VERSION ""

NS_ :

BS_:

BU_: WPC2 RLPSU DPSU PSB SHVU_RR APSU FCS EMCU SLB ARS RCM CGW_CCU ATS RLHV SGU PFSU ALBCU DSAU SWRC SHVU_FR RCS RRPSU BLTN_CAM SCM DLBCU OHCL RWPC RRHV WPC HOD ASAU

BO_ 2256644609 CLU_01_20ms_1: 8 CGW_CCU
 SG_ CLU_DtntOutSta : 28|2@1+ (1,0) [0|0] ""  FCS,WPC,RWPC,SWRC,APSU,RLHV,RRHV,SHVU_FR,SHVU_RR,DPSU,RCS,RRPSU,RLPSU,ATS,DSAU,ASAU,OHCL,WPC2
 SG_ CLU_RhstaLvlSta : 43|5@1+ (1,0) [0|0] ""  FCS,WPC,RWPC,SWRC,APSU,RLHV,RRHV,SHVU_FR,SHVU_RR,DPSU,RCS,RRPSU,RLPSU,ATS,DSAU,ASAU,OHCL,WPC2

BO_ 2470763009 CLU_09_00ms_1: 8 CGW_CCU
 SG_ USM_WpcSetReq : 34|2@1+ (1,0) [0|0] ""  WPC,WPC2

BO_ 2256644610 CLU_01_20ms_2: 8 CGW_CCU
 SG_ CLU_DisSpdVal_KPH : 0|9@1+ (1,0) [0|0] "km/h"  WPC,RWPC,APSU,RLHV,RRHV,SHVU_FR,SHVU_RR,DPSU,DLBCU,PFSU,RRPSU,RLPSU,ATS,DSAU,ASAU,RCM,ALBCU,WPC2
 SG_ CLU_AutoBrightSta : 15|8@1+ (1,0) [0|0] ""  FCS,WPC,RWPC,SWRC,APSU,RLHV,RRHV,SHVU_FR,SHVU_RR,DPSU,RCS,ATS,DSAU,ASAU,OHCL,BLTN_CAM,WPC2

BO_ 2214658049 EMS_02_10ms_1: 8 CGW_CCU
 SG_ ENG_EngSta : 61|3@1+ (1,0) [0|0] ""  SCM,WPC,RWPC,SWRC,APSU,RLHV,RRHV,SHVU_FR,SHVU_RR,DPSU,DLBCU,PFSU,RRPSU,RLPSU,HOD,RCM,BLTN_CAM,EMCU,WPC2

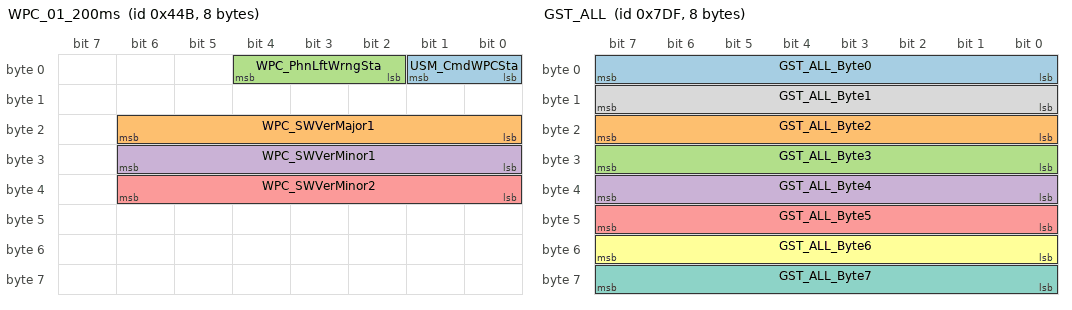
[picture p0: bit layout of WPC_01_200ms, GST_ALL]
BO_ 1099 WPC_01_200ms: 8 WPC
 SG_ USM_CmdWPCSta : 0|2@1+ (1,0) [0|0] ""  CGW_CCU
 SG_ WPC_SWVerMajor1 : 16|7@1+ (1,0) [0|0] ""  CGW_CCU
 SG_ WPC_PhnLftWrngSta : 2|3@1+ (1,0) [0|0] ""  CGW_CCU
 SG_ WPC_SWVerMinor1 : 24|7@1+ (1,0) [0|0] ""  CGW_CCU
 SG_ WPC_SWVerMinor2 : 32|7@1+ (1,0) [0|0] ""  CGW_CCU

BO_ 2470760705 CLU_05_00ms_1: 8 CGW_CCU
 SG_ USM_StaRst1Req : 34|2@1+ (1,0) [0|0] ""  WPC,DPSU,WPC2

BO_ 799 SBCM_DRV_01_200ms: 8 CGW_CCU
 SG_ Warn_DrvDrSwSta_SBCM : 20|2@1+ (1,0) [0|0] ""  WPC,RWPC,DPSU,ATS,BLTN_CAM,WPC2

BO_ 1195 HU_USM_E_04: 8 CGW_CCU
 SG_ CF_AVN_CluUSMReset : 62|2@1+ (1,0) [0|0] ""  WPC,RWPC,PSB,SLB,ARS,APSU,RLHV,RRHV,SHVU_FR,SHVU_RR,DPSU,DLBCU,PFSU,RRPSU,RLPSU,ATS,DSAU,ASAU,RCM,BLTN_CAM,ALBCU,WPC2

BO_ 1093 SMK_06_200ms: 8 CGW_CCU
 SG_ LFAnt_SrchSta : 42|2@1+ (1,0) [0|0] ""  WPC,RWPC,WPC2

BO_ 858 SBCM_AST_02_200ms: 8 CGW_CCU
 SG_ Warn_AsstDrSwSta_SBCM : 20|2@1+ (1,0) [0|0] ""  WPC,RWPC,APSU,ATS,BLTN_CAM,ALBCU,WPC2

BO_ 1193 HU_USM_E_02: 8 CGW_CCU
 SG_ CF_Gway_WPCNValueSet : 24|2@1+ (1,0) [0|0] ""  WPC,WPC2

BO_ 862 SBCM_RL_01_200ms: 8 CGW_CCU
 SG_ Warn_RrLftDrSwSta_SBCM : 16|2@1+ (1,0) [0|0] ""  WPC,RWPC,APSU,ATS,BLTN_CAM,WPC2

BO_ 2015 GST_ALL: 8 CGW_CCU
 SG_ GST_ALL_Byte0 : 0|8@1+ (1,0) [0|0] ""  FCS,SCM,WPC,RWPC,PSB,SLB,ARS,SWRC,APSU,RLHV,RRHV,SHVU_FR,SHVU_RR,DPSU,DLBCU,PFSU,RCS,RRPSU,RLPSU,HOD,ATS,DSAU,ASAU,RCM,EMCU,SGU,ALBCU,WPC2
 SG_ GST_ALL_Byte2 : 16|8@1+ (1,0) [0|0] ""  FCS,SCM,WPC,RWPC,PSB,SLB,ARS,SWRC,APSU,RLHV,RRHV,SHVU_FR,SHVU_RR,DPSU,DLBCU,PFSU,RCS,RRPSU,RLPSU,HOD,ATS,DSAU,ASAU,RCM,EMCU,SGU,ALBCU,WPC2
 SG_ GST_ALL_Byte3 : 24|8@1+ (1,0) [0|0] ""  FCS,SCM,WPC,RWPC,PSB,SLB,ARS,SWRC,APSU,RLHV,RRHV,SHVU_FR,SHVU_RR,DPSU,DLBCU,PFSU,RCS,RRPSU,RLPSU,HOD,ATS,DSAU,ASAU,RCM,EMCU,SGU,ALBCU,WPC2
 SG_ GST_ALL_Byte4 : 32|8@1+ (1,0) [0|0] ""  FCS,SCM,WPC,RWPC,PSB,SLB,ARS,SWRC,APSU,RLHV,RRHV,SHVU_FR,SHVU_RR,DPSU,DLBCU,PFSU,RCS,RRPSU,RLPSU,HOD,ATS,DSAU,ASAU,RCM,EMCU,SGU,ALBCU,WPC2
 SG_ GST_ALL_Byte5 : 40|8@1+ (1,0) [0|0] ""  FCS,SCM,WPC,RWPC,PSB,SLB,ARS,SWRC,APSU,RLHV,RRHV,SHVU_FR,SHVU_RR,DPSU,DLBCU,PFSU,RCS,RRPSU,RLPSU,HOD,ATS,DSAU,ASAU,RCM,EMCU,SGU,ALBCU,WPC2
 SG_ GST_ALL_Byte6 : 48|8@1+ (1,0) [0|0] ""  FCS,SCM,WPC,RWPC,PSB,SLB,ARS,SWRC,APSU,RLHV,RRHV,SHVU_FR,SHVU_RR,DPSU,DLBCU,PFSU,RCS,RRPSU,RLPSU,HOD,ATS,DSAU,ASAU,RCM,EMCU,SGU,ALBCU,WPC2
 SG_ GST_ALL_Byte7 : 56|8@1+ (1,0) [0|0] ""  FCS,SCM,WPC,RWPC,PSB,SLB,ARS,SWRC,APSU,RLHV,RRHV,SHVU_FR,SHVU_RR,DPSU,DLBCU,PFSU,RCS,RRPSU,RLPSU,HOD,ATS,DSAU,ASAU,RCM,EMCU,SGU,ALBCU,WPC2
 SG_ GST_ALL_Byte1 : 8|8@1+ (1,0) [0|0] ""  FCS,SCM,WPC,RWPC,PSB,SLB,ARS,SWRC,APSU,RLHV,RRHV,SHVU_FR,SHVU_RR,DPSU,DLBCU,PFSU,RCS,RRPSU,RLPSU,HOD,ATS,DSAU,ASAU,RCM,EMCU,SGU,ALBCU,WPC2

BO_ 1090 BCM_12_200ms: 8 CGW_CCU
 SG_ BCM_SmkOptTyp : 24|2@1+ (1,0) [0|0] ""  WPC,RWPC,WPC2

BO_ 2210462210 HCU_03_10ms_2: 8 CGW_CCU
 SG_ HCU_HevRdySta : 6|2@1+ (1,0) [0|0] ""  WPC,RWPC,SWRC,APSU,RLHV,RRHV,SHVU_FR,SHVU_RR,DPSU,DLBCU,PFSU,RRPSU,RLPSU,HOD,RCM,BLTN_CAM,WPC2

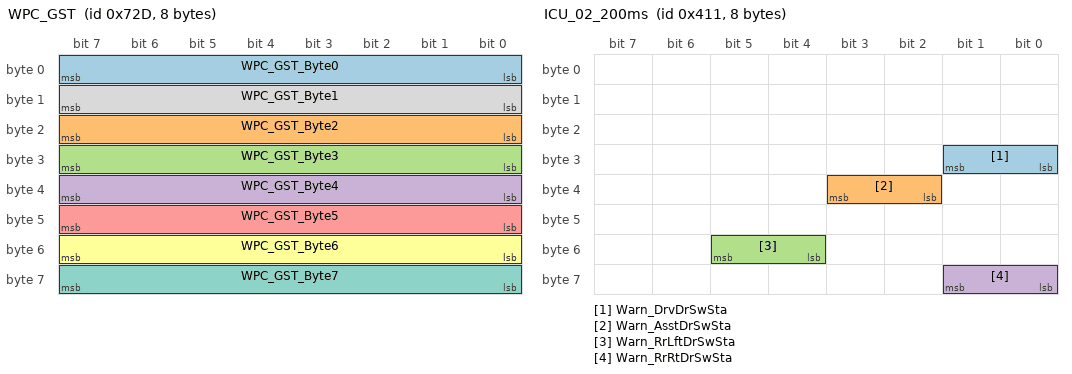
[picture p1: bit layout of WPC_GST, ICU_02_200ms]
BO_ 1837 WPC_GST: 8 WPC
 SG_ WPC_GST_Byte0 : 0|8@1+ (1,0) [0|0] ""  CGW_CCU
 SG_ WPC_GST_Byte2 : 16|8@1+ (1,0) [0|0] ""  CGW_CCU
 SG_ WPC_GST_Byte3 : 24|8@1+ (1,0) [0|0] ""  CGW_CCU
 SG_ WPC_GST_Byte4 : 32|8@1+ (1,0) [0|0] ""  CGW_CCU
 SG_ WPC_GST_Byte5 : 40|8@1+ (1,0) [0|0] ""  CGW_CCU
 SG_ WPC_GST_Byte6 : 48|8@1+ (1,0) [0|0] ""  CGW_CCU
 SG_ WPC_GST_Byte7 : 56|8@1+ (1,0) [0|0] ""  CGW_CCU
 SG_ WPC_GST_Byte1 : 8|8@1+ (1,0) [0|0] ""  CGW_CCU

BO_ 1050 BCM_07_200ms: 8 CGW_CCU
 SG_ Lamp_IntTailLmpOnReq : 36|2@1+ (1,0) [0|0] ""  FCS,WPC,RWPC,APSU,RLHV,RRHV,SHVU_FR,SHVU_RR,DPSU,WPC2

BO_ 905 SBCM_RR_01_200ms: 8 CGW_CCU
 SG_ Warn_RrRtDrSwSta_SBCM : 16|2@1+ (1,0) [0|0] ""  WPC,RWPC,APSU,RRPSU,ATS,BLTN_CAM,WPC2

BO_ 1041 ICU_02_200ms: 8 CGW_CCU
 SG_ Warn_DrvDrSwSta : 24|2@1+ (1,0) [0|0] ""  WPC,RWPC,DPSU,BLTN_CAM,WPC2
 SG_ Warn_AsstDrSwSta : 34|2@1+ (1,0) [0|0] ""  WPC,RWPC,APSU,RLPSU,BLTN_CAM,ALBCU,WPC2
 SG_ Warn_RrLftDrSwSta : 52|2@1+ (1,0) [0|0] ""  WPC,RWPC,APSU,RLHV,RLPSU,BLTN_CAM,WPC2
 SG_ Warn_RrRtDrSwSta : 56|2@1+ (1,0) [0|0] ""  WPC,RWPC,APSU,RRHV,RRPSU,RLPSU,BLTN_CAM,WPC2

BO_ 2353206529 CLU_20_200ms_1: 8 CGW_CCU
 SG_ CLU_ClusterUSM : 49|2@1+ (1,0) [0|0] ""  WPC,WPC2

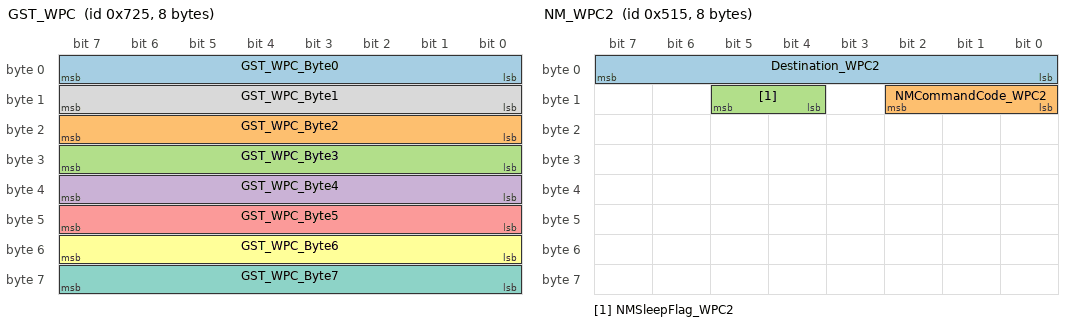
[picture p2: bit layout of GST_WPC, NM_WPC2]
BO_ 1829 GST_WPC: 8 CGW_CCU
 SG_ GST_WPC_Byte0 : 0|8@1+ (1,0) [0|0] ""  WPC
 SG_ GST_WPC_Byte2 : 16|8@1+ (1,0) [0|0] ""  WPC
 SG_ GST_WPC_Byte3 : 24|8@1+ (1,0) [0|0] ""  WPC
 SG_ GST_WPC_Byte4 : 32|8@1+ (1,0) [0|0] ""  WPC
 SG_ GST_WPC_Byte5 : 40|8@1+ (1,0) [0|0] ""  WPC
 SG_ GST_WPC_Byte6 : 48|8@1+ (1,0) [0|0] ""  WPC
 SG_ GST_WPC_Byte7 : 56|8@1+ (1,0) [0|0] ""  WPC
 SG_ GST_WPC_Byte1 : 8|8@1+ (1,0) [0|0] ""  WPC

BO_ 2160080129 VCU_01_10ms_1: 8 CGW_CCU
 SG_ VCU_EvDrvRdySta : 28|2@1+ (1,0) [0|3] ""  WPC,RWPC,SWRC,APSU,RLHV,RRHV,SHVU_FR,SHVU_RR,DPSU,DLBCU,PFSU,RRPSU,RLPSU,HOD,RCM,BLTN_CAM,WPC2

BO_ 1240 HU_GW_PE_01: 8 CGW_CCU
 SG_ CF_AVN_ProfileIDRValue : 40|4@1+ (1,0) [0|0] ""  WPC,RWPC,DPSU,DLBCU,RCM,BLTN_CAM,SGU,WPC2

BO_ 2214659330 EMS_07_10ms_2: 8 CGW_CCU
 SG_ HEV_EngOpSta : 28|3@1+ (1,0) [0|0] ""  WPC,RWPC,PFSU,WPC2

BO_ 1076 IAU_16_200ms: 8 CGW_CCU
 SG_ IAU_ProfileIDRVal : 10|4@1+ (1,0) [0|0] ""  WPC,RWPC,DPSU,DLBCU,RCM,BLTN_CAM,SGU,WPC2
 SG_ IAU_DigitalKey2Opt : 56|3@1+ (1,0) [0|0] ""  WPC,WPC2

BO_ 1301 NM_WPC2: 8 WPC2
 SG_ Destination_WPC2 : 0|8@1+ (1,0) [0|0] ""  RLPSU,DPSU,PSB,SHVU_RR,APSU,FCS,EMCU,SLB,ARS,RCM,CGW_CCU,ATS,RLHV,SGU,PFSU,ALBCU,DSAU,SWRC,SHVU_FR,RCS,RRPSU,BLTN_CAM,SCM,DLBCU,OHCL,RWPC,RRHV,WPC,HOD,ASAU
 SG_ NMCommandCode_WPC2 : 8|3@1+ (1,0) [0|0] ""  RLPSU,DPSU,PSB,SHVU_RR,APSU,FCS,EMCU,SLB,ARS,RCM,CGW_CCU,ATS,RLHV,SGU,PFSU,ALBCU,DSAU,SWRC,SHVU_FR,RCS,RRPSU,BLTN_CAM,SCM,DLBCU,OHCL,RWPC,RRHV,WPC,HOD,ASAU
 SG_ NMSleepFlag_WPC2 : 12|2@1+ (1,0) [0|0] ""  RLPSU,DPSU,PSB,SHVU_RR,APSU,FCS,EMCU,SLB,ARS,RCM,CGW_CCU,ATS,RLHV,SGU,PFSU,ALBCU,DSAU,SWRC,SHVU_FR,RCS,RRPSU,BLTN_CAM,SCM,DLBCU,OHCL,RWPC,RRHV,WPC,HOD,ASAU

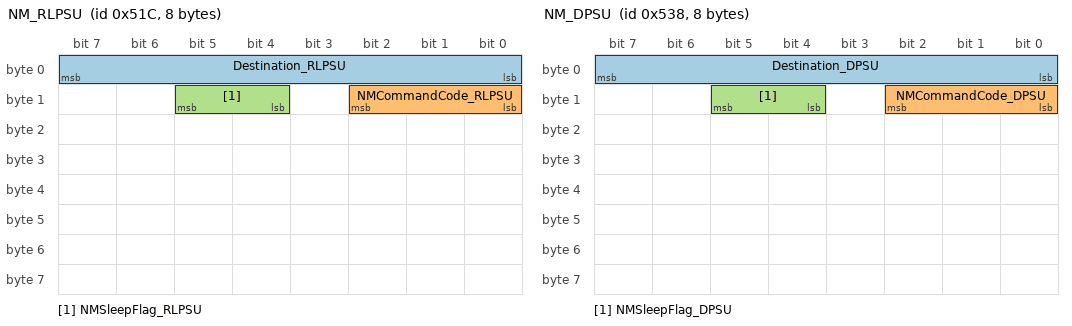
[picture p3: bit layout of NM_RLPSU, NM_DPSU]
BO_ 1308 NM_RLPSU: 8 RLPSU
 SG_ Destination_RLPSU : 0|8@1+ (1,0) [0|0] ""  WPC2,DPSU,PSB,SHVU_RR,APSU,FCS,EMCU,SLB,ARS,RCM,CGW_CCU,ATS,RLHV,SGU,PFSU,ALBCU,DSAU,SWRC,SHVU_FR,RCS,RRPSU,BLTN_CAM,SCM,DLBCU,OHCL,RWPC,RRHV,WPC,HOD,ASAU
 SG_ NMCommandCode_RLPSU : 8|3@1+ (1,0) [0|0] ""  WPC2,DPSU,PSB,SHVU_RR,APSU,FCS,EMCU,SLB,ARS,RCM,CGW_CCU,ATS,RLHV,SGU,PFSU,ALBCU,DSAU,SWRC,SHVU_FR,RCS,RRPSU,BLTN_CAM,SCM,DLBCU,OHCL,RWPC,RRHV,WPC,HOD,ASAU
 SG_ NMSleepFlag_RLPSU : 12|2@1+ (1,0) [0|0] ""  WPC2,DPSU,PSB,SHVU_RR,APSU,FCS,EMCU,SLB,ARS,RCM,CGW_CCU,ATS,RLHV,SGU,PFSU,ALBCU,DSAU,SWRC,SHVU_FR,RCS,RRPSU,BLTN_CAM,SCM,DLBCU,OHCL,RWPC,RRHV,WPC,HOD,ASAU

BO_ 1336 NM_DPSU: 8 DPSU
 SG_ Destination_DPSU : 0|8@1+ (1,0) [0|0] ""  WPC2,RLPSU,PSB,SHVU_RR,APSU,FCS,EMCU,SLB,ARS,RCM,CGW_CCU,ATS,RLHV,SGU,PFSU,ALBCU,DSAU,SWRC,SHVU_FR,RCS,RRPSU,BLTN_CAM,SCM,DLBCU,OHCL,RWPC,RRHV,WPC,HOD,ASAU
 SG_ NMCommandCode_DPSU : 8|3@1+ (1,0) [0|0] ""  WPC2,RLPSU,PSB,SHVU_RR,APSU,FCS,EMCU,SLB,ARS,RCM,CGW_CCU,ATS,RLHV,SGU,PFSU,ALBCU,DSAU,SWRC,SHVU_FR,RCS,RRPSU,BLTN_CAM,SCM,DLBCU,OHCL,RWPC,RRHV,WPC,HOD,ASAU
 SG_ NMSleepFlag_DPSU : 12|2@1+ (1,0) [0|0] ""  WPC2,RLPSU,PSB,SHVU_RR,APSU,FCS,EMCU,SLB,ARS,RCM,CGW_CCU,ATS,RLHV,SGU,PFSU,ALBCU,DSAU,SWRC,SHVU_FR,RCS,RRPSU,BLTN_CAM,SCM,DLBCU,OHCL,RWPC,RRHV,WPC,HOD,ASAU

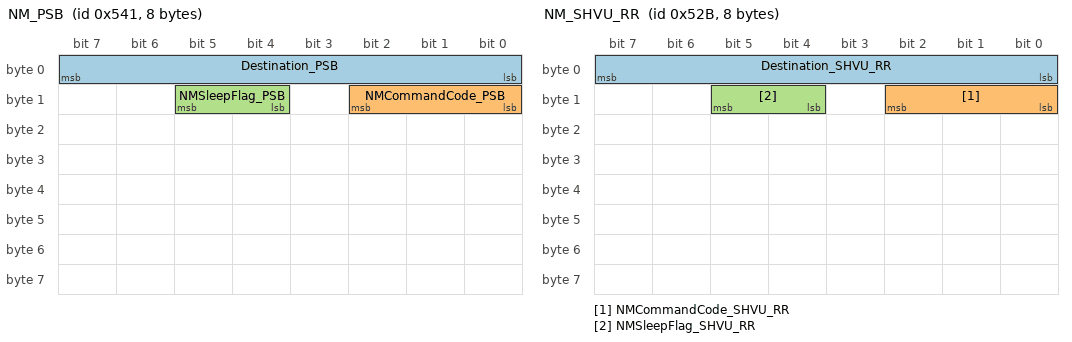
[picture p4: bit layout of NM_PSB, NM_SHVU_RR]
BO_ 1345 NM_PSB: 8 PSB
 SG_ Destination_PSB : 0|8@1+ (1,0) [0|0] ""  WPC2,RLPSU,DPSU,SHVU_RR,APSU,FCS,EMCU,SLB,ARS,RCM,CGW_CCU,ATS,RLHV,SGU,PFSU,ALBCU,DSAU,SWRC,SHVU_FR,RCS,RRPSU,BLTN_CAM,SCM,DLBCU,OHCL,RWPC,RRHV,WPC,HOD,ASAU
 SG_ NMCommandCode_PSB : 8|3@1+ (1,0) [0|0] ""  WPC2,RLPSU,DPSU,SHVU_RR,APSU,FCS,EMCU,SLB,ARS,RCM,CGW_CCU,ATS,RLHV,SGU,PFSU,ALBCU,DSAU,SWRC,SHVU_FR,RCS,RRPSU,BLTN_CAM,SCM,DLBCU,OHCL,RWPC,RRHV,WPC,HOD,ASAU
 SG_ NMSleepFlag_PSB : 12|2@1+ (1,0) [0|0] ""  WPC2,RLPSU,DPSU,SHVU_RR,APSU,FCS,EMCU,SLB,ARS,RCM,CGW_CCU,ATS,RLHV,SGU,PFSU,ALBCU,DSAU,SWRC,SHVU_FR,RCS,RRPSU,BLTN_CAM,SCM,DLBCU,OHCL,RWPC,RRHV,WPC,HOD,ASAU

BO_ 1323 NM_SHVU_RR: 8 SHVU_RR
 SG_ Destination_SHVU_RR : 0|8@1+ (1,0) [0|0] ""  WPC2,RLPSU,DPSU,PSB,APSU,FCS,EMCU,SLB,ARS,RCM,CGW_CCU,ATS,RLHV,SGU,PFSU,ALBCU,DSAU,SWRC,SHVU_FR,RCS,RRPSU,BLTN_CAM,SCM,DLBCU,OHCL,RWPC,RRHV,WPC,HOD,ASAU
 SG_ NMCommandCode_SHVU_RR : 8|3@1+ (1,0) [0|0] ""  WPC2,RLPSU,DPSU,PSB,APSU,FCS,EMCU,SLB,ARS,RCM,CGW_CCU,ATS,RLHV,SGU,PFSU,ALBCU,DSAU,SWRC,SHVU_FR,RCS,RRPSU,BLTN_CAM,SCM,DLBCU,OHCL,RWPC,RRHV,WPC,HOD,ASAU
 SG_ NMSleepFlag_SHVU_RR : 12|2@1+ (1,0) [0|0] ""  WPC2,RLPSU,DPSU,PSB,APSU,FCS,EMCU,SLB,ARS,RCM,CGW_CCU,ATS,RLHV,SGU,PFSU,ALBCU,DSAU,SWRC,SHVU_FR,RCS,RRPSU,BLTN_CAM,SCM,DLBCU,OHCL,RWPC,RRHV,WPC,HOD,ASAU

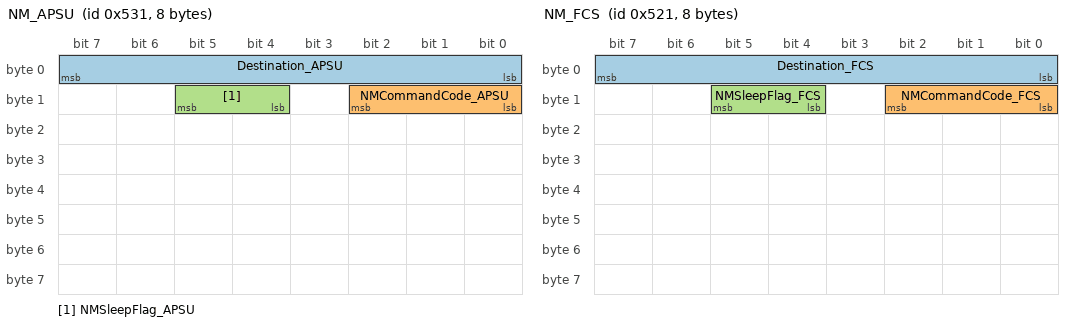
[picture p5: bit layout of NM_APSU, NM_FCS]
BO_ 1329 NM_APSU: 8 APSU
 SG_ Destination_APSU : 0|8@1+ (1,0) [0|0] ""  WPC2,RLPSU,DPSU,PSB,SHVU_RR,FCS,EMCU,SLB,ARS,RCM,CGW_CCU,ATS,RLHV,SGU,PFSU,ALBCU,DSAU,SWRC,SHVU_FR,RCS,RRPSU,BLTN_CAM,SCM,DLBCU,OHCL,RWPC,RRHV,WPC,HOD,ASAU
 SG_ NMCommandCode_APSU : 8|3@1+ (1,0) [0|0] ""  WPC2,RLPSU,DPSU,PSB,SHVU_RR,FCS,EMCU,SLB,ARS,RCM,CGW_CCU,ATS,RLHV,SGU,PFSU,ALBCU,DSAU,SWRC,SHVU_FR,RCS,RRPSU,BLTN_CAM,SCM,DLBCU,OHCL,RWPC,RRHV,WPC,HOD,ASAU
 SG_ NMSleepFlag_APSU : 12|2@1+ (1,0) [0|0] ""  WPC2,RLPSU,DPSU,PSB,SHVU_RR,FCS,EMCU,SLB,ARS,RCM,CGW_CCU,ATS,RLHV,SGU,PFSU,ALBCU,DSAU,SWRC,SHVU_FR,RCS,RRPSU,BLTN_CAM,SCM,DLBCU,OHCL,RWPC,RRHV,WPC,HOD,ASAU

BO_ 1313 NM_FCS: 8 FCS
 SG_ Destination_FCS : 0|8@1+ (1,0) [0|0] ""  WPC2,RLPSU,DPSU,PSB,SHVU_RR,APSU,EMCU,SLB,ARS,RCM,CGW_CCU,ATS,RLHV,SGU,PFSU,ALBCU,DSAU,SWRC,SHVU_FR,RCS,RRPSU,BLTN_CAM,SCM,DLBCU,OHCL,RWPC,RRHV,WPC,HOD,ASAU
 SG_ NMCommandCode_FCS : 8|3@1+ (1,0) [0|0] ""  WPC2,RLPSU,DPSU,PSB,SHVU_RR,APSU,EMCU,SLB,ARS,RCM,CGW_CCU,ATS,RLHV,SGU,PFSU,ALBCU,DSAU,SWRC,SHVU_FR,RCS,RRPSU,BLTN_CAM,SCM,DLBCU,OHCL,RWPC,RRHV,WPC,HOD,ASAU
 SG_ NMSleepFlag_FCS : 12|2@1+ (1,0) [0|0] ""  WPC2,RLPSU,DPSU,PSB,SHVU_RR,APSU,EMCU,SLB,ARS,RCM,CGW_CCU,ATS,RLHV,SGU,PFSU,ALBCU,DSAU,SWRC,SHVU_FR,RCS,RRPSU,BLTN_CAM,SCM,DLBCU,OHCL,RWPC,RRHV,WPC,HOD,ASAU

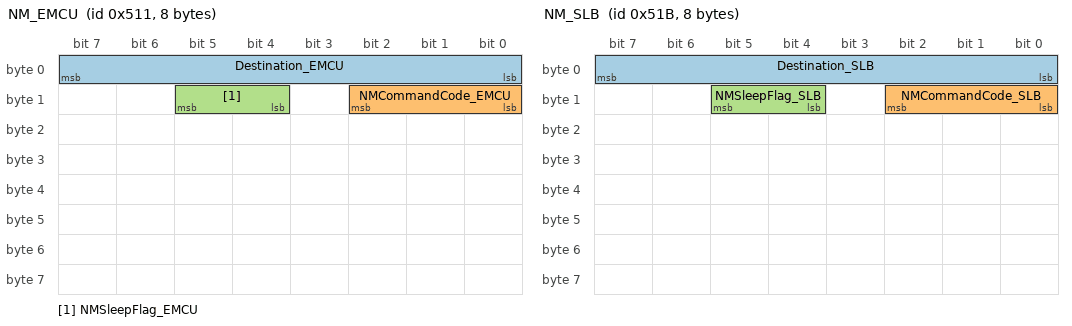
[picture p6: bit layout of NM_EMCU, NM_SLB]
BO_ 1297 NM_EMCU: 8 EMCU
 SG_ Destination_EMCU : 0|8@1+ (1,0) [0|0] ""  WPC2,RLPSU,DPSU,PSB,SHVU_RR,APSU,FCS,SLB,ARS,RCM,CGW_CCU,ATS,RLHV,SGU,PFSU,ALBCU,DSAU,SWRC,SHVU_FR,RCS,RRPSU,BLTN_CAM,SCM,DLBCU,OHCL,RWPC,RRHV,WPC,HOD,ASAU
 SG_ NMCommandCode_EMCU : 8|3@1+ (1,0) [0|0] ""  WPC2,RLPSU,DPSU,PSB,SHVU_RR,APSU,FCS,SLB,ARS,RCM,CGW_CCU,ATS,RLHV,SGU,PFSU,ALBCU,DSAU,SWRC,SHVU_FR,RCS,RRPSU,BLTN_CAM,SCM,DLBCU,OHCL,RWPC,RRHV,WPC,HOD,ASAU
 SG_ NMSleepFlag_EMCU : 12|2@1+ (1,0) [0|0] ""  WPC2,RLPSU,DPSU,PSB,SHVU_RR,APSU,FCS,SLB,ARS,RCM,CGW_CCU,ATS,RLHV,SGU,PFSU,ALBCU,DSAU,SWRC,SHVU_FR,RCS,RRPSU,BLTN_CAM,SCM,DLBCU,OHCL,RWPC,RRHV,WPC,HOD,ASAU

BO_ 1307 NM_SLB: 8 SLB
 SG_ Destination_SLB : 0|8@1+ (1,0) [0|0] ""  WPC2,RLPSU,DPSU,PSB,SHVU_RR,APSU,FCS,EMCU,ARS,RCM,CGW_CCU,ATS,RLHV,SGU,PFSU,ALBCU,DSAU,SWRC,SHVU_FR,RCS,RRPSU,BLTN_CAM,SCM,DLBCU,OHCL,RWPC,RRHV,WPC,HOD,ASAU
 SG_ NMCommandCode_SLB : 8|3@1+ (1,0) [0|0] ""  WPC2,RLPSU,DPSU,PSB,SHVU_RR,APSU,FCS,EMCU,ARS,RCM,CGW_CCU,ATS,RLHV,SGU,PFSU,ALBCU,DSAU,SWRC,SHVU_FR,RCS,RRPSU,BLTN_CAM,SCM,DLBCU,OHCL,RWPC,RRHV,WPC,HOD,ASAU
 SG_ NMSleepFlag_SLB : 12|2@1+ (1,0) [0|0] ""  WPC2,RLPSU,DPSU,PSB,SHVU_RR,APSU,FCS,EMCU,ARS,RCM,CGW_CCU,ATS,RLHV,SGU,PFSU,ALBCU,DSAU,SWRC,SHVU_FR,RCS,RRPSU,BLTN_CAM,SCM,DLBCU,OHCL,RWPC,RRHV,WPC,HOD,ASAU

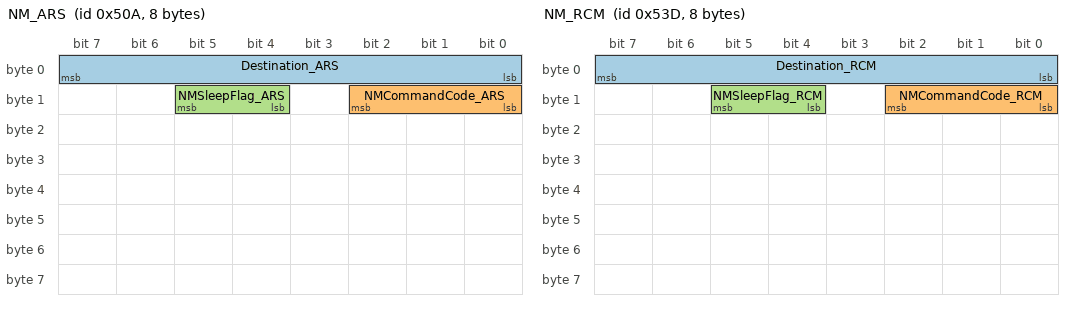
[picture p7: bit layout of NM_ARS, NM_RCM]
BO_ 1290 NM_ARS: 8 ARS
 SG_ Destination_ARS : 0|8@1+ (1,0) [0|0] ""  WPC2,RLPSU,DPSU,PSB,SHVU_RR,APSU,FCS,EMCU,SLB,RCM,CGW_CCU,ATS,RLHV,SGU,PFSU,ALBCU,DSAU,SWRC,SHVU_FR,RCS,RRPSU,BLTN_CAM,SCM,DLBCU,OHCL,RWPC,RRHV,WPC,HOD,ASAU
 SG_ NMCommandCode_ARS : 8|3@1+ (1,0) [0|0] ""  WPC2,RLPSU,DPSU,PSB,SHVU_RR,APSU,FCS,EMCU,SLB,RCM,CGW_CCU,ATS,RLHV,SGU,PFSU,ALBCU,DSAU,SWRC,SHVU_FR,RCS,RRPSU,BLTN_CAM,SCM,DLBCU,OHCL,RWPC,RRHV,WPC,HOD,ASAU
 SG_ NMSleepFlag_ARS : 12|2@1+ (1,0) [0|0] ""  WPC2,RLPSU,DPSU,PSB,SHVU_RR,APSU,FCS,EMCU,SLB,RCM,CGW_CCU,ATS,RLHV,SGU,PFSU,ALBCU,DSAU,SWRC,SHVU_FR,RCS,RRPSU,BLTN_CAM,SCM,DLBCU,OHCL,RWPC,RRHV,WPC,HOD,ASAU

BO_ 1341 NM_RCM: 8 RCM
 SG_ Destination_RCM : 0|8@1+ (1,0) [0|0] ""  WPC2,RLPSU,DPSU,PSB,SHVU_RR,APSU,FCS,EMCU,SLB,ARS,CGW_CCU,ATS,RLHV,SGU,PFSU,ALBCU,DSAU,SWRC,SHVU_FR,RCS,RRPSU,BLTN_CAM,SCM,DLBCU,OHCL,RWPC,RRHV,WPC,HOD,ASAU
 SG_ NMCommandCode_RCM : 8|3@1+ (1,0) [0|0] ""  WPC2,RLPSU,DPSU,PSB,SHVU_RR,APSU,FCS,EMCU,SLB,ARS,CGW_CCU,ATS,RLHV,SGU,PFSU,ALBCU,DSAU,SWRC,SHVU_FR,RCS,RRPSU,BLTN_CAM,SCM,DLBCU,OHCL,RWPC,RRHV,WPC,HOD,ASAU
 SG_ NMSleepFlag_RCM : 12|2@1+ (1,0) [0|0] ""  WPC2,RLPSU,DPSU,PSB,SHVU_RR,APSU,FCS,EMCU,SLB,ARS,CGW_CCU,ATS,RLHV,SGU,PFSU,ALBCU,DSAU,SWRC,SHVU_FR,RCS,RRPSU,BLTN_CAM,SCM,DLBCU,OHCL,RWPC,RRHV,WPC,HOD,ASAU

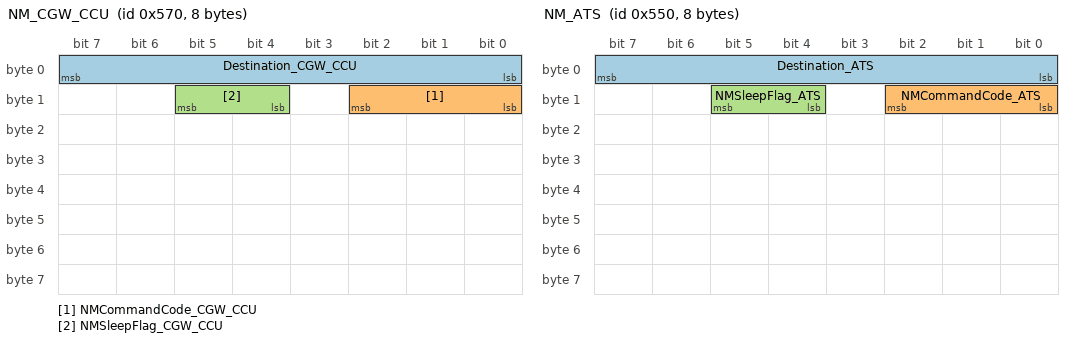
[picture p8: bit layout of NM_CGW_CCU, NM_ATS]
BO_ 1392 NM_CGW_CCU: 8 CGW_CCU
 SG_ Destination_CGW_CCU : 0|8@1+ (1,0) [0|0] ""  WPC2,RLPSU,DPSU,PSB,SHVU_RR,APSU,FCS,EMCU,SLB,ARS,RCM,ATS,RLHV,SGU,PFSU,ALBCU,DSAU,SWRC,SHVU_FR,RCS,RRPSU,BLTN_CAM,SCM,DLBCU,OHCL,RWPC,RRHV,WPC,HOD,ASAU
 SG_ NMCommandCode_CGW_CCU : 8|3@1+ (1,0) [0|0] ""  WPC2,RLPSU,DPSU,PSB,SHVU_RR,APSU,FCS,EMCU,SLB,ARS,RCM,ATS,RLHV,SGU,PFSU,ALBCU,DSAU,SWRC,SHVU_FR,RCS,RRPSU,BLTN_CAM,SCM,DLBCU,OHCL,RWPC,RRHV,WPC,HOD,ASAU
 SG_ NMSleepFlag_CGW_CCU : 12|2@1+ (1,0) [0|0] ""  WPC2,RLPSU,DPSU,PSB,SHVU_RR,APSU,FCS,EMCU,SLB,ARS,RCM,ATS,RLHV,SGU,PFSU,ALBCU,DSAU,SWRC,SHVU_FR,RCS,RRPSU,BLTN_CAM,SCM,DLBCU,OHCL,RWPC,RRHV,WPC,HOD,ASAU

BO_ 1360 NM_ATS: 8 ATS
 SG_ Destination_ATS : 0|8@1+ (1,0) [0|0] ""  WPC2,RLPSU,DPSU,PSB,SHVU_RR,APSU,FCS,EMCU,SLB,ARS,RCM,CGW_CCU,RLHV,SGU,PFSU,ALBCU,DSAU,SWRC,SHVU_FR,RCS,RRPSU,BLTN_CAM,SCM,DLBCU,OHCL,RWPC,RRHV,WPC,HOD,ASAU
 SG_ NMCommandCode_ATS : 8|3@1+ (1,0) [0|0] ""  WPC2,RLPSU,DPSU,PSB,SHVU_RR,APSU,FCS,EMCU,SLB,ARS,RCM,CGW_CCU,RLHV,SGU,PFSU,ALBCU,DSAU,SWRC,SHVU_FR,RCS,RRPSU,BLTN_CAM,SCM,DLBCU,OHCL,RWPC,RRHV,WPC,HOD,ASAU
 SG_ NMSleepFlag_ATS : 12|2@1+ (1,0) [0|0] ""  WPC2,RLPSU,DPSU,PSB,SHVU_RR,APSU,FCS,EMCU,SLB,ARS,RCM,CGW_CCU,RLHV,SGU,PFSU,ALBCU,DSAU,SWRC,SHVU_FR,RCS,RRPSU,BLTN_CAM,SCM,DLBCU,OHCL,RWPC,RRHV,WPC,HOD,ASAU

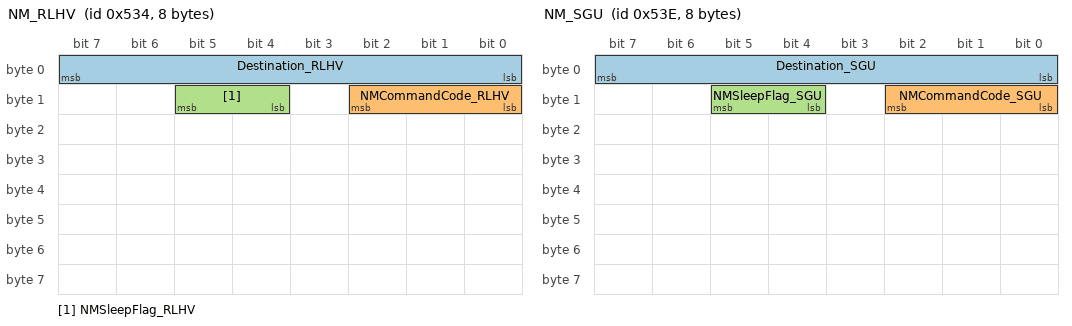
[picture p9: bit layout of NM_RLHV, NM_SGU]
BO_ 1332 NM_RLHV: 8 RLHV
 SG_ Destination_RLHV : 0|8@1+ (1,0) [0|0] ""  WPC2,RLPSU,DPSU,PSB,SHVU_RR,APSU,FCS,EMCU,SLB,ARS,RCM,CGW_CCU,ATS,SGU,PFSU,ALBCU,DSAU,SWRC,SHVU_FR,RCS,RRPSU,BLTN_CAM,SCM,DLBCU,OHCL,RWPC,RRHV,WPC,HOD,ASAU
 SG_ NMCommandCode_RLHV : 8|3@1+ (1,0) [0|0] ""  WPC2,RLPSU,DPSU,PSB,SHVU_RR,APSU,FCS,EMCU,SLB,ARS,RCM,CGW_CCU,ATS,SGU,PFSU,ALBCU,DSAU,SWRC,SHVU_FR,RCS,RRPSU,BLTN_CAM,SCM,DLBCU,OHCL,RWPC,RRHV,WPC,HOD,ASAU
 SG_ NMSleepFlag_RLHV : 12|2@1+ (1,0) [0|0] ""  WPC2,RLPSU,DPSU,PSB,SHVU_RR,APSU,FCS,EMCU,SLB,ARS,RCM,CGW_CCU,ATS,SGU,PFSU,ALBCU,DSAU,SWRC,SHVU_FR,RCS,RRPSU,BLTN_CAM,SCM,DLBCU,OHCL,RWPC,RRHV,WPC,HOD,ASAU

BO_ 1342 NM_SGU: 8 SGU
 SG_ Destination_SGU : 0|8@1+ (1,0) [0|0] ""  WPC2,RLPSU,DPSU,PSB,SHVU_RR,APSU,FCS,EMCU,SLB,ARS,RCM,CGW_CCU,ATS,RLHV,PFSU,ALBCU,DSAU,SWRC,SHVU_FR,RCS,RRPSU,BLTN_CAM,SCM,DLBCU,OHCL,RWPC,RRHV,WPC,HOD,ASAU
 SG_ NMCommandCode_SGU : 8|3@1+ (1,0) [0|0] ""  WPC2,RLPSU,DPSU,PSB,SHVU_RR,APSU,FCS,EMCU,SLB,ARS,RCM,CGW_CCU,ATS,RLHV,PFSU,ALBCU,DSAU,SWRC,SHVU_FR,RCS,RRPSU,BLTN_CAM,SCM,DLBCU,OHCL,RWPC,RRHV,WPC,HOD,ASAU
 SG_ NMSleepFlag_SGU : 12|2@1+ (1,0) [0|0] ""  WPC2,RLPSU,DPSU,PSB,SHVU_RR,APSU,FCS,EMCU,SLB,ARS,RCM,CGW_CCU,ATS,RLHV,PFSU,ALBCU,DSAU,SWRC,SHVU_FR,RCS,RRPSU,BLTN_CAM,SCM,DLBCU,OHCL,RWPC,RRHV,WPC,HOD,ASAU

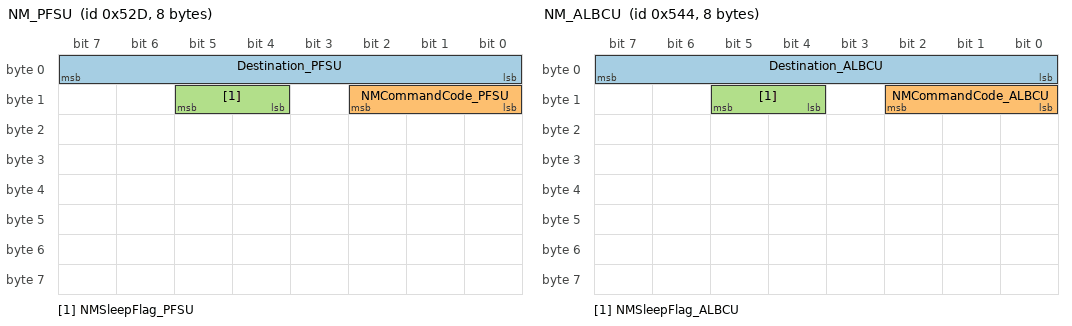
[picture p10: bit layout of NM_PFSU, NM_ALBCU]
BO_ 1325 NM_PFSU: 8 PFSU
 SG_ Destination_PFSU : 0|8@1+ (1,0) [0|0] ""  WPC2,RLPSU,DPSU,PSB,SHVU_RR,APSU,FCS,EMCU,SLB,ARS,RCM,CGW_CCU,ATS,RLHV,SGU,ALBCU,DSAU,SWRC,SHVU_FR,RCS,RRPSU,BLTN_CAM,SCM,DLBCU,OHCL,RWPC,RRHV,WPC,HOD,ASAU
 SG_ NMCommandCode_PFSU : 8|3@1+ (1,0) [0|0] ""  WPC2,RLPSU,DPSU,PSB,SHVU_RR,APSU,FCS,EMCU,SLB,ARS,RCM,CGW_CCU,ATS,RLHV,SGU,ALBCU,DSAU,SWRC,SHVU_FR,RCS,RRPSU,BLTN_CAM,SCM,DLBCU,OHCL,RWPC,RRHV,WPC,HOD,ASAU
 SG_ NMSleepFlag_PFSU : 12|2@1+ (1,0) [0|0] ""  WPC2,RLPSU,DPSU,PSB,SHVU_RR,APSU,FCS,EMCU,SLB,ARS,RCM,CGW_CCU,ATS,RLHV,SGU,ALBCU,DSAU,SWRC,SHVU_FR,RCS,RRPSU,BLTN_CAM,SCM,DLBCU,OHCL,RWPC,RRHV,WPC,HOD,ASAU

BO_ 1348 NM_ALBCU: 8 ALBCU
 SG_ Destination_ALBCU : 0|8@1+ (1,0) [0|0] ""  WPC2,RLPSU,DPSU,PSB,SHVU_RR,APSU,FCS,EMCU,SLB,ARS,RCM,CGW_CCU,ATS,RLHV,SGU,PFSU,DSAU,SWRC,SHVU_FR,RCS,RRPSU,BLTN_CAM,SCM,DLBCU,OHCL,RWPC,RRHV,WPC,HOD,ASAU
 SG_ NMCommandCode_ALBCU : 8|3@1+ (1,0) [0|0] ""  WPC2,RLPSU,DPSU,PSB,SHVU_RR,APSU,FCS,EMCU,SLB,ARS,RCM,CGW_CCU,ATS,RLHV,SGU,PFSU,DSAU,SWRC,SHVU_FR,RCS,RRPSU,BLTN_CAM,SCM,DLBCU,OHCL,RWPC,RRHV,WPC,HOD,ASAU
 SG_ NMSleepFlag_ALBCU : 12|2@1+ (1,0) [0|0] ""  WPC2,RLPSU,DPSU,PSB,SHVU_RR,APSU,FCS,EMCU,SLB,ARS,RCM,CGW_CCU,ATS,RLHV,SGU,PFSU,DSAU,SWRC,SHVU_FR,RCS,RRPSU,BLTN_CAM,SCM,DLBCU,OHCL,RWPC,RRHV,WPC,HOD,ASAU

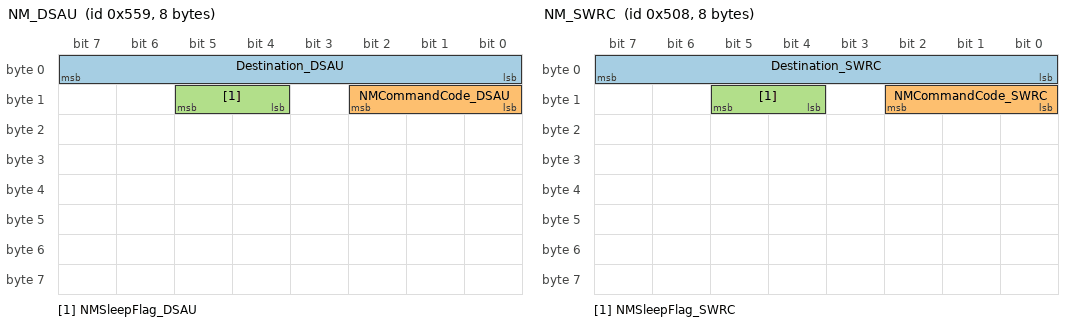
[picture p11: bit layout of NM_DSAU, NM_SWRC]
BO_ 1369 NM_DSAU: 8 DSAU
 SG_ Destination_DSAU : 0|8@1+ (1,0) [0|0] ""  WPC2,RLPSU,DPSU,PSB,SHVU_RR,APSU,FCS,EMCU,SLB,ARS,RCM,CGW_CCU,ATS,RLHV,SGU,PFSU,ALBCU,SWRC,SHVU_FR,RCS,RRPSU,BLTN_CAM,SCM,DLBCU,OHCL,RWPC,RRHV,WPC,HOD,ASAU
 SG_ NMCommandCode_DSAU : 8|3@1+ (1,0) [0|0] ""  WPC2,RLPSU,DPSU,PSB,SHVU_RR,APSU,FCS,EMCU,SLB,ARS,RCM,CGW_CCU,ATS,RLHV,SGU,PFSU,ALBCU,SWRC,SHVU_FR,RCS,RRPSU,BLTN_CAM,SCM,DLBCU,OHCL,RWPC,RRHV,WPC,HOD,ASAU
 SG_ NMSleepFlag_DSAU : 12|2@1+ (1,0) [0|0] ""  WPC2,RLPSU,DPSU,PSB,SHVU_RR,APSU,FCS,EMCU,SLB,ARS,RCM,CGW_CCU,ATS,RLHV,SGU,PFSU,ALBCU,SWRC,SHVU_FR,RCS,RRPSU,BLTN_CAM,SCM,DLBCU,OHCL,RWPC,RRHV,WPC,HOD,ASAU

BO_ 1288 NM_SWRC: 8 SWRC
 SG_ Destination_SWRC : 0|8@1+ (1,0) [0|0] ""  WPC2,RLPSU,DPSU,PSB,SHVU_RR,APSU,FCS,EMCU,SLB,ARS,RCM,CGW_CCU,ATS,RLHV,SGU,PFSU,ALBCU,DSAU,SHVU_FR,RCS,RRPSU,BLTN_CAM,SCM,DLBCU,OHCL,RWPC,RRHV,WPC,HOD,ASAU
 SG_ NMCommandCode_SWRC : 8|3@1+ (1,0) [0|0] ""  WPC2,RLPSU,DPSU,PSB,SHVU_RR,APSU,FCS,EMCU,SLB,ARS,RCM,CGW_CCU,ATS,RLHV,SGU,PFSU,ALBCU,DSAU,SHVU_FR,RCS,RRPSU,BLTN_CAM,SCM,DLBCU,OHCL,RWPC,RRHV,WPC,HOD,ASAU
 SG_ NMSleepFlag_SWRC : 12|2@1+ (1,0) [0|0] ""  WPC2,RLPSU,DPSU,PSB,SHVU_RR,APSU,FCS,EMCU,SLB,ARS,RCM,CGW_CCU,ATS,RLHV,SGU,PFSU,ALBCU,DSAU,SHVU_FR,RCS,RRPSU,BLTN_CAM,SCM,DLBCU,OHCL,RWPC,RRHV,WPC,HOD,ASAU

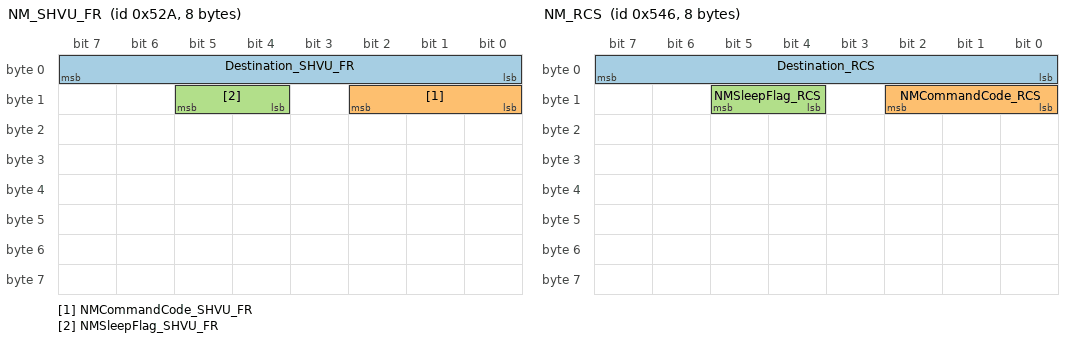
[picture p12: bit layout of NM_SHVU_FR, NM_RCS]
BO_ 1322 NM_SHVU_FR: 8 SHVU_FR
 SG_ Destination_SHVU_FR : 0|8@1+ (1,0) [0|0] ""  WPC2,RLPSU,DPSU,PSB,SHVU_RR,APSU,FCS,EMCU,SLB,ARS,RCM,CGW_CCU,ATS,RLHV,SGU,PFSU,ALBCU,DSAU,SWRC,RCS,RRPSU,BLTN_CAM,SCM,DLBCU,OHCL,RWPC,RRHV,WPC,HOD,ASAU
 SG_ NMCommandCode_SHVU_FR : 8|3@1+ (1,0) [0|0] ""  WPC2,RLPSU,DPSU,PSB,SHVU_RR,APSU,FCS,EMCU,SLB,ARS,RCM,CGW_CCU,ATS,RLHV,SGU,PFSU,ALBCU,DSAU,SWRC,RCS,RRPSU,BLTN_CAM,SCM,DLBCU,OHCL,RWPC,RRHV,WPC,HOD,ASAU
 SG_ NMSleepFlag_SHVU_FR : 12|2@1+ (1,0) [0|0] ""  WPC2,RLPSU,DPSU,PSB,SHVU_RR,APSU,FCS,EMCU,SLB,ARS,RCM,CGW_CCU,ATS,RLHV,SGU,PFSU,ALBCU,DSAU,SWRC,RCS,RRPSU,BLTN_CAM,SCM,DLBCU,OHCL,RWPC,RRHV,WPC,HOD,ASAU

BO_ 1350 NM_RCS: 8 RCS
 SG_ Destination_RCS : 0|8@1+ (1,0) [0|0] ""  WPC2,RLPSU,DPSU,PSB,SHVU_RR,APSU,FCS,EMCU,SLB,ARS,RCM,CGW_CCU,ATS,RLHV,SGU,PFSU,ALBCU,DSAU,SWRC,SHVU_FR,RRPSU,BLTN_CAM,SCM,DLBCU,OHCL,RWPC,RRHV,WPC,HOD,ASAU
 SG_ NMCommandCode_RCS : 8|3@1+ (1,0) [0|0] ""  WPC2,RLPSU,DPSU,PSB,SHVU_RR,APSU,FCS,EMCU,SLB,ARS,RCM,CGW_CCU,ATS,RLHV,SGU,PFSU,ALBCU,DSAU,SWRC,SHVU_FR,RRPSU,BLTN_CAM,SCM,DLBCU,OHCL,RWPC,RRHV,WPC,HOD,ASAU
 SG_ NMSleepFlag_RCS : 12|2@1+ (1,0) [0|0] ""  WPC2,RLPSU,DPSU,PSB,SHVU_RR,APSU,FCS,EMCU,SLB,ARS,RCM,CGW_CCU,ATS,RLHV,SGU,PFSU,ALBCU,DSAU,SWRC,SHVU_FR,RRPSU,BLTN_CAM,SCM,DLBCU,OHCL,RWPC,RRHV,WPC,HOD,ASAU

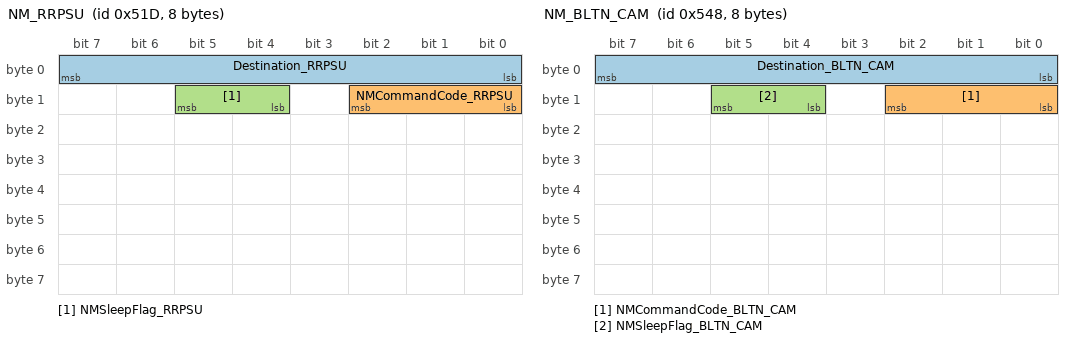
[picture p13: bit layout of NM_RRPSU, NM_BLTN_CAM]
BO_ 1309 NM_RRPSU: 8 RRPSU
 SG_ Destination_RRPSU : 0|8@1+ (1,0) [0|0] ""  WPC2,RLPSU,DPSU,PSB,SHVU_RR,APSU,FCS,EMCU,SLB,ARS,RCM,CGW_CCU,ATS,RLHV,SGU,PFSU,ALBCU,DSAU,SWRC,SHVU_FR,RCS,BLTN_CAM,SCM,DLBCU,OHCL,RWPC,RRHV,WPC,HOD,ASAU
 SG_ NMCommandCode_RRPSU : 8|3@1+ (1,0) [0|0] ""  WPC2,RLPSU,DPSU,PSB,SHVU_RR,APSU,FCS,EMCU,SLB,ARS,RCM,CGW_CCU,ATS,RLHV,SGU,PFSU,ALBCU,DSAU,SWRC,SHVU_FR,RCS,BLTN_CAM,SCM,DLBCU,OHCL,RWPC,RRHV,WPC,HOD,ASAU
 SG_ NMSleepFlag_RRPSU : 12|2@1+ (1,0) [0|0] ""  WPC2,RLPSU,DPSU,PSB,SHVU_RR,APSU,FCS,EMCU,SLB,ARS,RCM,CGW_CCU,ATS,RLHV,SGU,PFSU,ALBCU,DSAU,SWRC,SHVU_FR,RCS,BLTN_CAM,SCM,DLBCU,OHCL,RWPC,RRHV,WPC,HOD,ASAU

BO_ 1352 NM_BLTN_CAM: 8 BLTN_CAM
 SG_ Destination_BLTN_CAM : 0|8@1+ (1,0) [0|0] ""  WPC2,RLPSU,DPSU,PSB,SHVU_RR,APSU,FCS,EMCU,SLB,ARS,RCM,CGW_CCU,ATS,RLHV,SGU,PFSU,ALBCU,DSAU,SWRC,SHVU_FR,RCS,RRPSU,SCM,DLBCU,OHCL,RWPC,RRHV,WPC,HOD,ASAU
 SG_ NMCommandCode_BLTN_CAM : 8|3@1+ (1,0) [0|0] ""  WPC2,RLPSU,DPSU,PSB,SHVU_RR,APSU,FCS,EMCU,SLB,ARS,RCM,CGW_CCU,ATS,RLHV,SGU,PFSU,ALBCU,DSAU,SWRC,SHVU_FR,RCS,RRPSU,SCM,DLBCU,OHCL,RWPC,RRHV,WPC,HOD,ASAU
 SG_ NMSleepFlag_BLTN_CAM : 12|2@1+ (1,0) [0|0] ""  WPC2,RLPSU,DPSU,PSB,SHVU_RR,APSU,FCS,EMCU,SLB,ARS,RCM,CGW_CCU,ATS,RLHV,SGU,PFSU,ALBCU,DSAU,SWRC,SHVU_FR,RCS,RRPSU,SCM,DLBCU,OHCL,RWPC,RRHV,WPC,HOD,ASAU

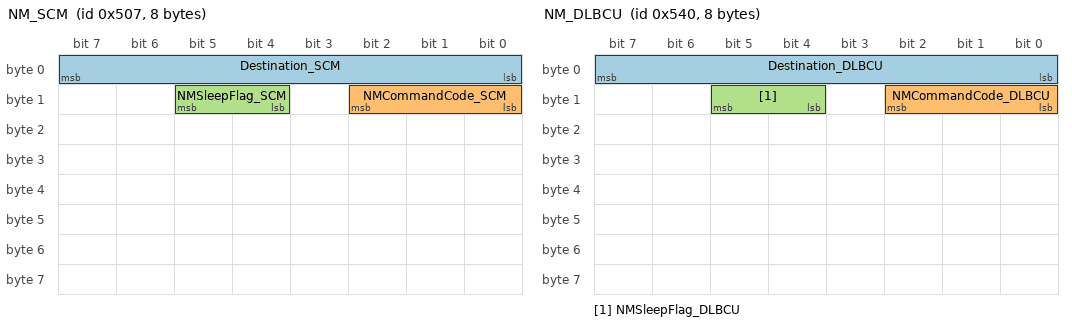
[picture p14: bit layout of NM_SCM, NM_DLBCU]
BO_ 1287 NM_SCM: 8 SCM
 SG_ Destination_SCM : 0|8@1+ (1,0) [0|0] ""  WPC2,RLPSU,DPSU,PSB,SHVU_RR,APSU,FCS,EMCU,SLB,ARS,RCM,CGW_CCU,ATS,RLHV,SGU,PFSU,ALBCU,DSAU,SWRC,SHVU_FR,RCS,RRPSU,BLTN_CAM,DLBCU,OHCL,RWPC,RRHV,WPC,HOD,ASAU
 SG_ NMCommandCode_SCM : 8|3@1+ (1,0) [0|0] ""  WPC2,RLPSU,DPSU,PSB,SHVU_RR,APSU,FCS,EMCU,SLB,ARS,RCM,CGW_CCU,ATS,RLHV,SGU,PFSU,ALBCU,DSAU,SWRC,SHVU_FR,RCS,RRPSU,BLTN_CAM,DLBCU,OHCL,RWPC,RRHV,WPC,HOD,ASAU
 SG_ NMSleepFlag_SCM : 12|2@1+ (1,0) [0|0] ""  WPC2,RLPSU,DPSU,PSB,SHVU_RR,APSU,FCS,EMCU,SLB,ARS,RCM,CGW_CCU,ATS,RLHV,SGU,PFSU,ALBCU,DSAU,SWRC,SHVU_FR,RCS,RRPSU,BLTN_CAM,DLBCU,OHCL,RWPC,RRHV,WPC,HOD,ASAU

BO_ 1344 NM_DLBCU: 8 DLBCU
 SG_ Destination_DLBCU : 0|8@1+ (1,0) [0|0] ""  WPC2,RLPSU,DPSU,PSB,SHVU_RR,APSU,FCS,EMCU,SLB,ARS,RCM,CGW_CCU,ATS,RLHV,SGU,PFSU,ALBCU,DSAU,SWRC,SHVU_FR,RCS,RRPSU,BLTN_CAM,SCM,OHCL,RWPC,RRHV,WPC,HOD,ASAU
 SG_ NMCommandCode_DLBCU : 8|3@1+ (1,0) [0|0] ""  WPC2,RLPSU,DPSU,PSB,SHVU_RR,APSU,FCS,EMCU,SLB,ARS,RCM,CGW_CCU,ATS,RLHV,SGU,PFSU,ALBCU,DSAU,SWRC,SHVU_FR,RCS,RRPSU,BLTN_CAM,SCM,OHCL,RWPC,RRHV,WPC,HOD,ASAU
 SG_ NMSleepFlag_DLBCU : 12|2@1+ (1,0) [0|0] ""  WPC2,RLPSU,DPSU,PSB,SHVU_RR,APSU,FCS,EMCU,SLB,ARS,RCM,CGW_CCU,ATS,RLHV,SGU,PFSU,ALBCU,DSAU,SWRC,SHVU_FR,RCS,RRPSU,BLTN_CAM,SCM,OHCL,RWPC,RRHV,WPC,HOD,ASAU

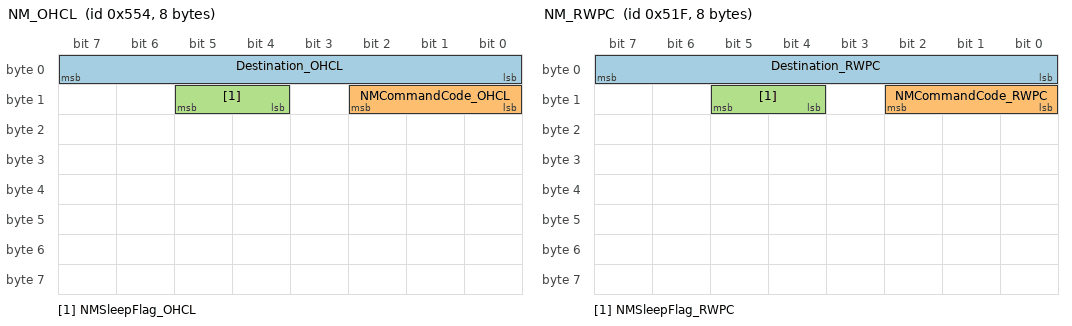
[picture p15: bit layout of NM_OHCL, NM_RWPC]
BO_ 1364 NM_OHCL: 8 OHCL
 SG_ Destination_OHCL : 0|8@1+ (1,0) [0|0] ""  WPC2,RLPSU,DPSU,PSB,SHVU_RR,APSU,FCS,EMCU,SLB,ARS,RCM,CGW_CCU,ATS,RLHV,SGU,PFSU,ALBCU,DSAU,SWRC,SHVU_FR,RCS,RRPSU,BLTN_CAM,SCM,DLBCU,RWPC,RRHV,WPC,HOD,ASAU
 SG_ NMCommandCode_OHCL : 8|3@1+ (1,0) [0|0] ""  WPC2,RLPSU,DPSU,PSB,SHVU_RR,APSU,FCS,EMCU,SLB,ARS,RCM,CGW_CCU,ATS,RLHV,SGU,PFSU,ALBCU,DSAU,SWRC,SHVU_FR,RCS,RRPSU,BLTN_CAM,SCM,DLBCU,RWPC,RRHV,WPC,HOD,ASAU
 SG_ NMSleepFlag_OHCL : 12|2@1+ (1,0) [0|0] ""  WPC2,RLPSU,DPSU,PSB,SHVU_RR,APSU,FCS,EMCU,SLB,ARS,RCM,CGW_CCU,ATS,RLHV,SGU,PFSU,ALBCU,DSAU,SWRC,SHVU_FR,RCS,RRPSU,BLTN_CAM,SCM,DLBCU,RWPC,RRHV,WPC,HOD,ASAU

BO_ 1311 NM_RWPC: 8 RWPC
 SG_ Destination_RWPC : 0|8@1+ (1,0) [0|0] ""  WPC2,RLPSU,DPSU,PSB,SHVU_RR,APSU,FCS,EMCU,SLB,ARS,RCM,CGW_CCU,ATS,RLHV,SGU,PFSU,ALBCU,DSAU,SWRC,SHVU_FR,RCS,RRPSU,BLTN_CAM,SCM,DLBCU,OHCL,RRHV,WPC,HOD,ASAU
 SG_ NMCommandCode_RWPC : 8|3@1+ (1,0) [0|0] ""  WPC2,RLPSU,DPSU,PSB,SHVU_RR,APSU,FCS,EMCU,SLB,ARS,RCM,CGW_CCU,ATS,RLHV,SGU,PFSU,ALBCU,DSAU,SWRC,SHVU_FR,RCS,RRPSU,BLTN_CAM,SCM,DLBCU,OHCL,RRHV,WPC,HOD,ASAU
 SG_ NMSleepFlag_RWPC : 12|2@1+ (1,0) [0|0] ""  WPC2,RLPSU,DPSU,PSB,SHVU_RR,APSU,FCS,EMCU,SLB,ARS,RCM,CGW_CCU,ATS,RLHV,SGU,PFSU,ALBCU,DSAU,SWRC,SHVU_FR,RCS,RRPSU,BLTN_CAM,SCM,DLBCU,OHCL,RRHV,WPC,HOD,ASAU

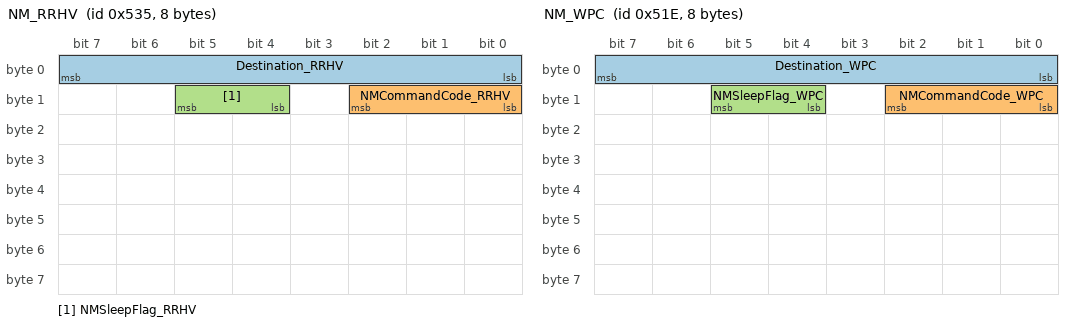
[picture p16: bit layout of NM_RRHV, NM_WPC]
BO_ 1333 NM_RRHV: 8 RRHV
 SG_ Destination_RRHV : 0|8@1+ (1,0) [0|0] ""  WPC2,RLPSU,DPSU,PSB,SHVU_RR,APSU,FCS,EMCU,SLB,ARS,RCM,CGW_CCU,ATS,RLHV,SGU,PFSU,ALBCU,DSAU,SWRC,SHVU_FR,RCS,RRPSU,BLTN_CAM,SCM,DLBCU,OHCL,RWPC,WPC,HOD,ASAU
 SG_ NMCommandCode_RRHV : 8|3@1+ (1,0) [0|0] ""  WPC2,RLPSU,DPSU,PSB,SHVU_RR,APSU,FCS,EMCU,SLB,ARS,RCM,CGW_CCU,ATS,RLHV,SGU,PFSU,ALBCU,DSAU,SWRC,SHVU_FR,RCS,RRPSU,BLTN_CAM,SCM,DLBCU,OHCL,RWPC,WPC,HOD,ASAU
 SG_ NMSleepFlag_RRHV : 12|2@1+ (1,0) [0|0] ""  WPC2,RLPSU,DPSU,PSB,SHVU_RR,APSU,FCS,EMCU,SLB,ARS,RCM,CGW_CCU,ATS,RLHV,SGU,PFSU,ALBCU,DSAU,SWRC,SHVU_FR,RCS,RRPSU,BLTN_CAM,SCM,DLBCU,OHCL,RWPC,WPC,HOD,ASAU

BO_ 1310 NM_WPC: 8 WPC
 SG_ Destination_WPC : 0|8@1+ (1,0) [0|0] ""  WPC2,RLPSU,DPSU,PSB,SHVU_RR,APSU,FCS,EMCU,SLB,ARS,RCM,CGW_CCU,ATS,RLHV,SGU,PFSU,ALBCU,DSAU,SWRC,SHVU_FR,RCS,RRPSU,BLTN_CAM,SCM,DLBCU,OHCL,RWPC,RRHV,HOD,ASAU
 SG_ NMCommandCode_WPC : 8|3@1+ (1,0) [0|0] ""  WPC2,RLPSU,DPSU,PSB,SHVU_RR,APSU,FCS,EMCU,SLB,ARS,RCM,CGW_CCU,ATS,RLHV,SGU,PFSU,ALBCU,DSAU,SWRC,SHVU_FR,RCS,RRPSU,BLTN_CAM,SCM,DLBCU,OHCL,RWPC,RRHV,HOD,ASAU
 SG_ NMSleepFlag_WPC : 12|2@1+ (1,0) [0|0] ""  WPC2,RLPSU,DPSU,PSB,SHVU_RR,APSU,FCS,EMCU,SLB,ARS,RCM,CGW_CCU,ATS,RLHV,SGU,PFSU,ALBCU,DSAU,SWRC,SHVU_FR,RCS,RRPSU,BLTN_CAM,SCM,DLBCU,OHCL,RWPC,RRHV,HOD,ASAU

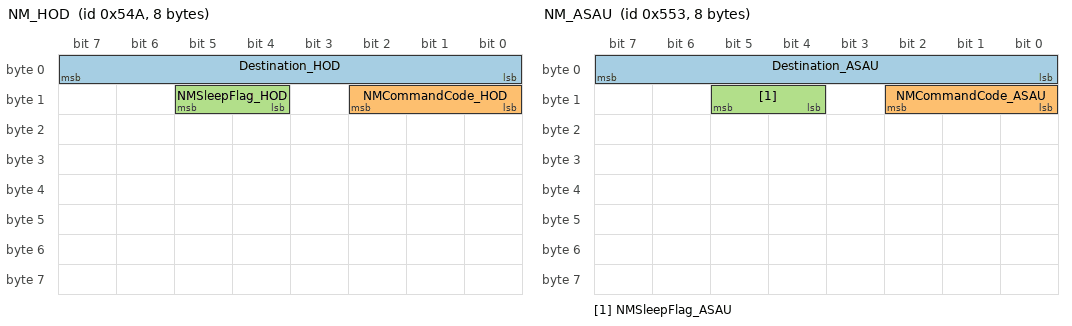
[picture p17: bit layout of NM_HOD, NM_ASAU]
BO_ 1354 NM_HOD: 8 HOD
 SG_ Destination_HOD : 0|8@1+ (1,0) [0|0] ""  WPC2,RLPSU,DPSU,PSB,SHVU_RR,APSU,FCS,EMCU,SLB,ARS,RCM,CGW_CCU,ATS,RLHV,SGU,PFSU,ALBCU,DSAU,SWRC,SHVU_FR,RCS,RRPSU,BLTN_CAM,SCM,DLBCU,OHCL,RWPC,RRHV,WPC,ASAU
 SG_ NMCommandCode_HOD : 8|3@1+ (1,0) [0|0] ""  WPC2,RLPSU,DPSU,PSB,SHVU_RR,APSU,FCS,EMCU,SLB,ARS,RCM,CGW_CCU,ATS,RLHV,SGU,PFSU,ALBCU,DSAU,SWRC,SHVU_FR,RCS,RRPSU,BLTN_CAM,SCM,DLBCU,OHCL,RWPC,RRHV,WPC,ASAU
 SG_ NMSleepFlag_HOD : 12|2@1+ (1,0) [0|0] ""  WPC2,RLPSU,DPSU,PSB,SHVU_RR,APSU,FCS,EMCU,SLB,ARS,RCM,CGW_CCU,ATS,RLHV,SGU,PFSU,ALBCU,DSAU,SWRC,SHVU_FR,RCS,RRPSU,BLTN_CAM,SCM,DLBCU,OHCL,RWPC,RRHV,WPC,ASAU

BO_ 1363 NM_ASAU: 8 ASAU
 SG_ Destination_ASAU : 0|8@1+ (1,0) [0|0] ""  WPC2,RLPSU,DPSU,PSB,SHVU_RR,APSU,FCS,EMCU,SLB,ARS,RCM,CGW_CCU,ATS,RLHV,SGU,PFSU,ALBCU,DSAU,SWRC,SHVU_FR,RCS,RRPSU,BLTN_CAM,SCM,DLBCU,OHCL,RWPC,RRHV,WPC,HOD
 SG_ NMCommandCode_ASAU : 8|3@1+ (1,0) [0|0] ""  WPC2,RLPSU,DPSU,PSB,SHVU_RR,APSU,FCS,EMCU,SLB,ARS,RCM,CGW_CCU,ATS,RLHV,SGU,PFSU,ALBCU,DSAU,SWRC,SHVU_FR,RCS,RRPSU,BLTN_CAM,SCM,DLBCU,OHCL,RWPC,RRHV,WPC,HOD
 SG_ NMSleepFlag_ASAU : 12|2@1+ (1,0) [0|0] ""  WPC2,RLPSU,DPSU,PSB,SHVU_RR,APSU,FCS,EMCU,SLB,ARS,RCM,CGW_CCU,ATS,RLHV,SGU,PFSU,ALBCU,DSAU,SWRC,SHVU_FR,RCS,RRPSU,BLTN_CAM,SCM,DLBCU,OHCL,RWPC,RRHV,WPC,HOD

CM_ BO_ 1050 "[PE] Periodic and On Event";
CM_ SG_ 1050 Lamp_IntTailLmpOnReq "Lamp_InternalTailLampOnRequest ##2G##BCM - BCMmsg19 - C_IntTailOn";
CM_ BO_ 1090 "[PE] Periodic and On Event";
CM_ SG_ 1090 BCM_SmkOptTyp "BCM_SmkOptionType ##2G##BCM - BCMmsg17 - C_SMKOption";
CM_ BO_ 2256644609 "[P] Periodic";
CM_ SG_ 2256644609 CLU_DtntOutSta "CLU_DetentOutStatus";
CM_ SG_ 2256644609 CLU_RhstaLvlSta "CLU_RheostatLevelStatus";
CM_ BO_ 2256644610 "[P] Periodic";
CM_ SG_ 2256644610 CLU_DisSpdVal_KPH "CLU_DisplaySpeedValue_KPH";
CM_ SG_ 2256644610 CLU_AutoBrightSta "CLU_AutoBrightStatus";
CM_ BO_ 2470760705 "[EC] On Event and On Change";
CM_ SG_ 2470760705 USM_StaRst1Req "USM_StatusReset1Request";
CM_ BO_ 2470763009 "[EC] On Event and On Change";
CM_ SG_ 2470763009 USM_WpcSetReq "USM_WpcSetRequest";
CM_ BO_ 2353206529 "[P] Periodic";
CM_ BO_ 2214658049 "[P] Periodic";
CM_ SG_ 2214658049 ENG_EngSta "ENG_EngineStatus ##2G##EMS - EMS16 - ENG_STAT";
CM_ BO_ 2214659330 "[P] Periodic";
CM_ SG_ 2214659330 HEV_EngOpSta "HEV_EngineOperatingStatus";
CM_ BO_ 2015 "[TP] Transport Protocol";
CM_ BO_ 1829 "[TP] Transport Protocol";
CM_ BO_ 2210462210 "[P] Periodic";
CM_ SG_ 2210462210 HCU_HevRdySta "HCU_HybridVehicleReadyStatus ##2G##HCU - HCU1 - CF_Hcu_HevRdy";
CM_ BO_ 1240 "[PE] Periodic and On Event";
CM_ SG_ 1240 CF_AVN_ProfileIDRValue "This signal is User ID value in H/Unit.";
CM_ BO_ 1193 "[EC] On Event and On Change";
CM_ SG_ 1193 CF_Gway_WPCNValueSet "Request to set Wireless Phone Charging mode";
CM_ BO_ 1195 "[EC] On Event and On Change";
CM_ SG_ 1195 CF_AVN_CluUSMReset "Request to reset all USM service";
CM_ BO_ 1076 "[PE] Periodic and On Event";
CM_ SG_ 1076 IAU_ProfileIDRVal "This signal Indicate the Current detected Profile ID by IAU.";
CM_ SG_ 1076 IAU_DigitalKey2Opt "Digital Key2 Option Signal";
CM_ BO_ 1041 "[PE] Periodic and On Event";
CM_ SG_ 1041 Warn_DrvDrSwSta "DoorLock_DriverDoorSwitchStatus ##2G## -  - C_DrvDrSw,CF_Gway_DrvDrSw,Warn_DrvDrSwSta";
CM_ SG_ 1041 Warn_AsstDrSwSta "Warn_AssistDoorSwitchStatus ##2G## -  - C_AstDrSw,CF_Gway_AstDrSw,Warn_AsstDrSwSta";
CM_ SG_ 1041 Warn_RrLftDrSwSta "Warn_RearLeftDoorSwitchStatus ##2G## -  - C_RLDrSw,CF_Gway_RLDrSw,Warn_RrLftDrSwSta";
CM_ SG_ 1041 Warn_RrRtDrSwSta "Warn_RearRightDoorSwitchStatus ##2G## -  - C_RRDrSw,CF_Gway_RRDrSw,Warn_RrRtDrSwSta";
CM_ BO_ 858 "[PE] Periodic and On Event";
CM_ SG_ 858 Warn_AsstDrSwSta_SBCM "Warn_AssistDoorSwitchStatus ##2G## -  - C_AstDrSw,CF_Gway_AstDrSw,Warn_AsstDrSwSta";
CM_ BO_ 799 "[PE] Periodic and On Event";
CM_ SG_ 799 Warn_DrvDrSwSta_SBCM "DoorLock_DriverDoorSwitchStatus ##2G## -  - C_DrvDrSw,CF_Gway_DrvDrSw,Warn_DrvDrSwSta";
CM_ BO_ 862 "[PE] Periodic and On Event";
CM_ SG_ 862 Warn_RrLftDrSwSta_SBCM "Warn_RearLeftDoorSwitchStatus ##2G## -  - C_RLDrSw,CF_Gway_RLDrSw,Warn_RrLftDrSwSta";
CM_ BO_ 905 "[PE] Periodic and On Event";
CM_ SG_ 905 Warn_RrRtDrSwSta_SBCM "Warn_RearRightDoorSwitchStatus ##2G## -  - C_RRDrSw,CF_Gway_RRDrSw,Warn_RrRtDrSwSta";
CM_ BO_ 1093 "[PE] Periodic and On Event";
CM_ SG_ 1093 LFAnt_SrchSta "LFAntenna_SearchingStatus ##2G##SMK - SMKmsg19 - C_LFSearchingOn";
CM_ BO_ 2160080129 "[P] Periodic";
CM_ SG_ 2160080129 VCU_EvDrvRdySta "VCU_EvDriveReadyStatus ##2G##VCU - VCU1 - CF_Vcu_EvRdy";
CM_ BO_ 1099 "[PE] Periodic and On Event";
CM_ SG_ 1099 USM_CmdWPCSta "USM_CommandWPCStatus";
CM_ SG_ 1099 WPC_SWVerMajor1 "First Word(ASCII) in WPC S/W Ver";
CM_ SG_ 1099 WPC_PhnLftWrngSta "WPC_PhoneLeftWarningStatus";
CM_ SG_ 1099 WPC_SWVerMinor1 "Second Word(ASCII) in WPC S/W Ver";
CM_ SG_ 1099 WPC_SWVerMinor2 "Third Word(ASCII) in WPC S/W Ver";
CM_ BO_ 1837 "[TP] Transport Protocol";
CM_ BO_ 1301 "NM Message";
CM_ SG_ 1301 Destination_WPC2 "NM Source Node Identifier";
CM_ SG_ 1301 NMCommandCode_WPC2 "NM Control Bit Vector - Repeat Message Request";
CM_ SG_ 1301 NMSleepFlag_WPC2 "NM Control Bit Vector - NM Coordinator ID";
CM_ BO_ 1308 "NM Message";
CM_ SG_ 1308 Destination_RLPSU "NM Source Node Identifier";
CM_ SG_ 1308 NMCommandCode_RLPSU "NM Control Bit Vector - Repeat Message Request";
CM_ SG_ 1308 NMSleepFlag_RLPSU "NM Control Bit Vector - NM Coordinator ID";
CM_ BO_ 1336 "NM Message";
CM_ SG_ 1336 Destination_DPSU "NM Source Node Identifier";
CM_ SG_ 1336 NMCommandCode_DPSU "NM Control Bit Vector - Repeat Message Request";
CM_ SG_ 1336 NMSleepFlag_DPSU "NM Control Bit Vector - NM Coordinator ID";
CM_ BO_ 1345 "NM Message";
CM_ SG_ 1345 Destination_PSB "NM Source Node Identifier";
CM_ SG_ 1345 NMCommandCode_PSB "NM Control Bit Vector - Repeat Message Request";
CM_ SG_ 1345 NMSleepFlag_PSB "NM Control Bit Vector - NM Coordinator ID";
CM_ BO_ 1323 "NM Message";
CM_ SG_ 1323 Destination_SHVU_RR "NM Source Node Identifier";
CM_ SG_ 1323 NMCommandCode_SHVU_RR "NM Control Bit Vector - Repeat Message Request";
CM_ SG_ 1323 NMSleepFlag_SHVU_RR "NM Control Bit Vector - NM Coordinator ID";
CM_ BO_ 1329 "NM Message";
CM_ SG_ 1329 Destination_APSU "NM Source Node Identifier";
CM_ SG_ 1329 NMCommandCode_APSU "NM Control Bit Vector - Repeat Message Request";
CM_ SG_ 1329 NMSleepFlag_APSU "NM Control Bit Vector - NM Coordinator ID";
CM_ BO_ 1313 "NM Message";
CM_ SG_ 1313 Destination_FCS "NM Source Node Identifier";
CM_ SG_ 1313 NMCommandCode_FCS "NM Control Bit Vector - Repeat Message Request";
CM_ SG_ 1313 NMSleepFlag_FCS "NM Control Bit Vector - NM Coordinator ID";
CM_ BO_ 1297 "NM Message";
CM_ SG_ 1297 Destination_EMCU "NM Source Node Identifier";
CM_ SG_ 1297 NMCommandCode_EMCU "NM Control Bit Vector - Repeat Message Request";
CM_ SG_ 1297 NMSleepFlag_EMCU "NM Control Bit Vector - NM Coordinator ID";
CM_ BO_ 1307 "NM Message";
CM_ SG_ 1307 Destination_SLB "NM Source Node Identifier";
CM_ SG_ 1307 NMCommandCode_SLB "NM Control Bit Vector - Repeat Message Request";
CM_ SG_ 1307 NMSleepFlag_SLB "NM Control Bit Vector - NM Coordinator ID";
CM_ BO_ 1290 "NM Message";
CM_ SG_ 1290 Destination_ARS "NM Source Node Identifier";
CM_ SG_ 1290 NMCommandCode_ARS "NM Control Bit Vector - Repeat Message Request";
CM_ SG_ 1290 NMSleepFlag_ARS "NM Control Bit Vector - NM Coordinator ID";
CM_ BO_ 1341 "NM Message";
CM_ SG_ 1341 Destination_RCM "NM Source Node Identifier";
CM_ SG_ 1341 NMCommandCode_RCM "NM Control Bit Vector - Repeat Message Request";
CM_ SG_ 1341 NMSleepFlag_RCM "NM Control Bit Vector - NM Coordinator ID";
CM_ BO_ 1392 "NM Message";
CM_ SG_ 1392 Destination_CGW_CCU "NM Source Node Identifier";
CM_ SG_ 1392 NMCommandCode_CGW_CCU "NM Control Bit Vector - Repeat Message Request";
CM_ SG_ 1392 NMSleepFlag_CGW_CCU "NM Control Bit Vector - NM Coordinator ID";
CM_ BO_ 1360 "NM Message";
CM_ SG_ 1360 Destination_ATS "NM Source Node Identifier";
CM_ SG_ 1360 NMCommandCode_ATS "NM Control Bit Vector - Repeat Message Request";
CM_ SG_ 1360 NMSleepFlag_ATS "NM Control Bit Vector - NM Coordinator ID";
CM_ BO_ 1332 "NM Message";
CM_ SG_ 1332 Destination_RLHV "NM Source Node Identifier";
CM_ SG_ 1332 NMCommandCode_RLHV "NM Control Bit Vector - Repeat Message Request";
CM_ SG_ 1332 NMSleepFlag_RLHV "NM Control Bit Vector - NM Coordinator ID";
CM_ BO_ 1342 "NM Message";
CM_ SG_ 1342 Destination_SGU "NM Source Node Identifier";
CM_ SG_ 1342 NMCommandCode_SGU "NM Control Bit Vector - Repeat Message Request";
CM_ SG_ 1342 NMSleepFlag_SGU "NM Control Bit Vector - NM Coordinator ID";
CM_ BO_ 1325 "NM Message";
CM_ SG_ 1325 Destination_PFSU "NM Source Node Identifier";
CM_ SG_ 1325 NMCommandCode_PFSU "NM Control Bit Vector - Repeat Message Request";
CM_ SG_ 1325 NMSleepFlag_PFSU "NM Control Bit Vector - NM Coordinator ID";
CM_ BO_ 1348 "NM Message";
CM_ SG_ 1348 Destination_ALBCU "NM Source Node Identifier";
CM_ SG_ 1348 NMCommandCode_ALBCU "NM Control Bit Vector - Repeat Message Request";
CM_ SG_ 1348 NMSleepFlag_ALBCU "NM Control Bit Vector - NM Coordinator ID";
CM_ BO_ 1369 "NM Message";
CM_ SG_ 1369 Destination_DSAU "NM Source Node Identifier";
CM_ SG_ 1369 NMCommandCode_DSAU "NM Control Bit Vector - Repeat Message Request";
CM_ SG_ 1369 NMSleepFlag_DSAU "NM Control Bit Vector - NM Coordinator ID";
CM_ BO_ 1288 "NM Message";
CM_ SG_ 1288 Destination_SWRC "NM Source Node Identifier";
CM_ SG_ 1288 NMCommandCode_SWRC "NM Control Bit Vector - Repeat Message Request";
CM_ SG_ 1288 NMSleepFlag_SWRC "NM Control Bit Vector - NM Coordinator ID";
CM_ BO_ 1322 "NM Message";
CM_ SG_ 1322 Destination_SHVU_FR "NM Source Node Identifier";
CM_ SG_ 1322 NMCommandCode_SHVU_FR "NM Control Bit Vector - Repeat Message Request";
CM_ SG_ 1322 NMSleepFlag_SHVU_FR "NM Control Bit Vector - NM Coordinator ID";
CM_ BO_ 1350 "NM Message";
CM_ SG_ 1350 Destination_RCS "NM Source Node Identifier";
CM_ SG_ 1350 NMCommandCode_RCS "NM Control Bit Vector - Repeat Message Request";
CM_ SG_ 1350 NMSleepFlag_RCS "NM Control Bit Vector - NM Coordinator ID";
CM_ BO_ 1309 "NM Message";
CM_ SG_ 1309 Destination_RRPSU "NM Source Node Identifier";
CM_ SG_ 1309 NMCommandCode_RRPSU "NM Control Bit Vector - Repeat Message Request";
CM_ SG_ 1309 NMSleepFlag_RRPSU "NM Control Bit Vector - NM Coordinator ID";
CM_ BO_ 1352 "NM Message";
CM_ SG_ 1352 Destination_BLTN_CAM "NM Source Node Identifier";
CM_ SG_ 1352 NMCommandCode_BLTN_CAM "NM Control Bit Vector - Repeat Message Request";
CM_ SG_ 1352 NMSleepFlag_BLTN_CAM "NM Control Bit Vector - NM Coordinator ID";
CM_ BO_ 1287 "NM Message";
CM_ SG_ 1287 Destination_SCM "NM Source Node Identifier";
CM_ SG_ 1287 NMCommandCode_SCM "NM Control Bit Vector - Repeat Message Request";
CM_ SG_ 1287 NMSleepFlag_SCM "NM Control Bit Vector - NM Coordinator ID";
CM_ BO_ 1344 "NM Message";
CM_ SG_ 1344 Destination_DLBCU "NM Source Node Identifier";
CM_ SG_ 1344 NMCommandCode_DLBCU "NM Control Bit Vector - Repeat Message Request";
CM_ SG_ 1344 NMSleepFlag_DLBCU "NM Control Bit Vector - NM Coordinator ID";
CM_ BO_ 1364 "NM Message";
CM_ SG_ 1364 Destination_OHCL "NM Source Node Identifier";
CM_ SG_ 1364 NMCommandCode_OHCL "NM Control Bit Vector - Repeat Message Request";
CM_ SG_ 1364 NMSleepFlag_OHCL "NM Control Bit Vector - NM Coordinator ID";
CM_ BO_ 1311 "NM Message";
CM_ SG_ 1311 Destination_RWPC "NM Source Node Identifier";
CM_ SG_ 1311 NMCommandCode_RWPC "NM Control Bit Vector - Repeat Message Request";
CM_ SG_ 1311 NMSleepFlag_RWPC "NM Control Bit Vector - NM Coordinator ID";
CM_ BO_ 1333 "NM Message";
CM_ SG_ 1333 Destination_RRHV "NM Source Node Identifier";
CM_ SG_ 1333 NMCommandCode_RRHV "NM Control Bit Vector - Repeat Message Request";
CM_ SG_ 1333 NMSleepFlag_RRHV "NM Control Bit Vector - NM Coordinator ID";
CM_ BO_ 1310 "NM Message";
CM_ SG_ 1310 Destination_WPC "NM Source Node Identifier";
CM_ SG_ 1310 NMCommandCode_WPC "NM Control Bit Vector - Repeat Message Request";
CM_ SG_ 1310 NMSleepFlag_WPC "NM Control Bit Vector - NM Coordinator ID";
CM_ BO_ 1354 "NM Message";
CM_ SG_ 1354 Destination_HOD "NM Source Node Identifier";
CM_ SG_ 1354 NMCommandCode_HOD "NM Control Bit Vector - Repeat Message Request";
CM_ SG_ 1354 NMSleepFlag_HOD "NM Control Bit Vector - NM Coordinator ID";
CM_ BO_ 1363 "NM Message";
CM_ SG_ 1363 Destination_ASAU "NM Source Node Identifier";
CM_ SG_ 1363 NMCommandCode_ASAU "NM Control Bit Vector - Repeat Message Request";
CM_ SG_ 1363 NMSleepFlag_ASAU "NM Control Bit Vector - NM Coordinator ID";
BA_DEF_ BO_ "DiagState" ENUM "No","Yes" ;
BA_DEF_ BO_ "DiagResponse" ENUM "No","Yes" ;
BA_DEF_ BO_ "DiagRequest" ENUM "No","Yes" ;
BA_DEF_ BO_ "TpMessage" ENUM "No","Yes" ;
BA_DEF_ BO_ "UsrMsgIDSforwardDeviation" INT 0 100 ;
BA_DEF_ BO_ "UsrMsgIDSbackwardDeviation" INT 50 1000 ;
BA_DEF_ "BusType" STRING ;
BA_DEF_ "DBName" STRING ;
BA_DEF_ "Baudrate" INT 50000 1000000 ;
BA_DEF_ "GenEnvVarEndingDsp" STRING ;
BA_DEF_ "GenEnvVarEndingSnd" STRING ;
BA_DEF_ "GenEnvVarPrefix" STRING ;
BA_DEF_ "GenNWMApBusSleep" STRING ;
BA_DEF_ "GenNWMApCanNormal" STRING ;
BA_DEF_ "GenNWMApCanOff" STRING ;
BA_DEF_ "GenNWMApCanOn" STRING ;
BA_DEF_ "GenNWMApCanSleep" STRING ;
BA_DEF_ "GenNWMApCanWakeUp" STRING ;
BA_DEF_ "GenNWMGotoMode_Awake" STRING ;
BA_DEF_ "GenNWMGotoMode_BusSleep" STRING ;
BA_DEF_ "GenNWMSleepTime" INT 1375 1650 ;
BA_DEF_ "GenNWMTalkNM" STRING ;
BA_DEF_ "Manufacturer" STRING ;
BA_DEF_ "NmBaseAddress" HEX 0 2047 ;
BA_DEF_ "NmMessageCount" INT 0 128 ;
BA_DEF_ "NmType" STRING ;
BA_DEF_ "SamplePointMax" INT 50 85 ;
BA_DEF_ "SamplePointMin" INT 55 85 ;
BA_DEF_ "SyncJumpWidthMax" INT 1 8 ;
BA_DEF_ "SyncJumpWidthMin" INT 1 4 ;
BA_DEF_ "VersionDay" INT 1 31 ;
BA_DEF_ "VersionMonth" INT 1 12 ;
BA_DEF_ "VersionNumber" INT 0 999999 ;
BA_DEF_ "VersionNumberInternal" INT 0 9999 ;
BA_DEF_ "VersionWeek" INT 1 53 ;
BA_DEF_ "VersionYear" INT 0 9999 ;
BA_DEF_ BU_ "NmStationAddress" HEX 0 127 ;
BA_DEF_ BU_ "NmNode" ENUM "No","Yes" ;
BA_DEF_ BU_ "GenNodSleepTime" INT 1375 1650 ;
BA_DEF_ BU_ "ILUsed" ENUM "No","Yes" ;
BA_DEF_ BU_ "NmCAN" INT 1 2 ;
BA_DEF_ BU_ "NodeLayerModules" STRING ;
BA_DEF_ BU_ "NWM_Knoten" ENUM "No","Yes" ;
BA_DEF_ BO_ "GenMsgCycleTime" INT 0 2000 ;
BA_DEF_ BO_ "GenMsgStartDelayTime" INT 0 2000 ;
BA_DEF_ BO_ "GenMsgSendType" ENUM "Cyclic","NoMsgSendType" ;
BA_DEF_ BO_ "GenMsgCycleTimeFast" INT 0 500 ;
BA_DEF_ BO_ "GenMsgDelayTime" INT 0 20 ;
BA_DEF_ BO_ "GenMsgILSupport" ENUM "No","Yes" ;
BA_DEF_ BO_ "GenMsgNrOfRepetition" INT 0 3 ;
BA_DEF_ BO_ "NmMessage" ENUM "No","Yes" ;
BA_DEF_ BO_ "NWM-Botschaft" ENUM "No","Yes" ;
BA_DEF_ BO_ "TpTxIndex" INT 0 255 ;
BA_DEF_ BO_ "VFrameFormat" ENUM "StandardCAN","ExtendedCAN","reserved","reserved","reserved","reserved","reserved","reserved","reserved","reserved","reserved","reserved","reserved","reserved","StandardCAN_FD","ExtendedCAN_FD" ;
BA_DEF_ SG_ "UserSigValidity" ENUM "B+","ACC","IG","IG1","IG2","IG3","IG1 or IG2","IG1 or IG3","Undef" ;
BA_DEF_ SG_ "UsrSigPurpose" ENUM "Undef","FN","DIAG","DIAG(Req)","DIAG(Res)","DIAG(Phy)","DEV","CCP(Req)","CCP(Res)","NM","TP" ;
BA_DEF_ SG_ "GenSigStartValue" INT 0 1215752192 ;
BA_DEF_ SG_ "NetworkRequest" ENUM "Yes","No" ;
BA_DEF_ SG_ "NetworkRequestHoldingTime" INT 0 65535 ;
BA_DEF_ SG_ "Description" STRING ;
BA_DEF_ SG_ "Version" STRING ;
BA_DEF_ SG_ "GenSigEnvVarType" ENUM "Int","Float","Undef" ;
BA_DEF_ SG_ "GenSigSendType" ENUM "Cyclic","OnWrite","OnWriteWithRepetition","OnChange","OnChangeWithRepetition","IfActive","IfActiveWithRepetition","NoSigSendType","OnChangeAndIfActive","OnChangeAndIfActiveWithRepetition" ;
BA_DEF_ SG_ "GwSigLatencyTime" INT 0 65536 ;
BA_DEF_ SG_ "GwSigMissingSourceType" ENUM "Undef","OldValue","DefaultValue","InitialValue" ;
BA_DEF_ SG_ "NWM-WakeupAllowed" ENUM "<n.a.>" ;
BA_DEF_ SG_ "RoutingFactor" INT 1 1215752192 ;
BA_DEF_REL_ BU_SG_REL_ "GenSigTimeoutTime" INT 0 7000 ;
BA_DEF_DEF_ "DiagState" "No" ;
BA_DEF_DEF_ "DiagResponse" "No" ;
BA_DEF_DEF_ "DiagRequest" "No" ;
BA_DEF_DEF_ "TpMessage" "No" ;
BA_DEF_DEF_ "UsrMsgIDSforwardDeviation" 10 ;
BA_DEF_DEF_ "UsrMsgIDSbackwardDeviation" 100 ;
BA_DEF_DEF_ "BusType" "CAN" ;
BA_DEF_DEF_ "DBName" "" ;
BA_DEF_DEF_ "Baudrate" 500000 ;
BA_DEF_DEF_ "GenEnvVarEndingDsp" "Dsp_" ;
BA_DEF_DEF_ "GenEnvVarEndingSnd" "_" ;
BA_DEF_DEF_ "GenEnvVarPrefix" "Env" ;
BA_DEF_DEF_ "GenNWMApBusSleep" "AppNmCanBusSleep()" ;
BA_DEF_DEF_ "GenNWMApCanNormal" "AppNmCanNormal()" ;
BA_DEF_DEF_ "GenNWMApCanOff" "ApplCanOffline()" ;
BA_DEF_DEF_ "GenNWMApCanOn" "ApplCanOnline()" ;
BA_DEF_DEF_ "GenNWMApCanSleep" "ApplNmCanSleep()" ;
BA_DEF_DEF_ "GenNWMApCanWakeUp" "ApplCanWakeUp()" ;
BA_DEF_DEF_ "GenNWMGotoMode_Awake" "GotoMode_Awake()" ;
BA_DEF_DEF_ "GenNWMGotoMode_BusSleep" "GotoMode_BusSleep()" ;
BA_DEF_DEF_ "GenNWMSleepTime" 1500 ;
BA_DEF_DEF_ "GenNWMTalkNM" "TalkNM()" ;
BA_DEF_DEF_ "Manufacturer" "HMC" ;
BA_DEF_DEF_ "NmBaseAddress" 1280 ;
BA_DEF_DEF_ "NmMessageCount" 128 ;
BA_DEF_DEF_ "NmType" "Vector" ;
BA_DEF_DEF_ "SamplePointMax" 80 ;
BA_DEF_DEF_ "SamplePointMin" 80 ;
BA_DEF_DEF_ "SyncJumpWidthMax" 3 ;
BA_DEF_DEF_ "SyncJumpWidthMin" 2 ;
BA_DEF_DEF_ "VersionDay" 1 ;
BA_DEF_DEF_ "VersionMonth" 1 ;
BA_DEF_DEF_ "VersionNumber" 0 ;
BA_DEF_DEF_ "VersionNumberInternal" 0 ;
BA_DEF_DEF_ "VersionWeek" 1 ;
BA_DEF_DEF_ "VersionYear" 0 ;
BA_DEF_DEF_ "NmStationAddress" 0 ;
BA_DEF_DEF_ "NmNode" "Yes" ;
BA_DEF_DEF_ "GenNodSleepTime" 1500 ;
BA_DEF_DEF_ "ILUsed" "Yes" ;
BA_DEF_DEF_ "NmCAN" 1 ;
BA_DEF_DEF_ "NodeLayerModules" "oseknm01.dll,CANoeILNLVector.dll" ;
BA_DEF_DEF_ "NWM_Knoten" "Yes" ;
BA_DEF_DEF_ "GenMsgCycleTime" 200 ;
BA_DEF_DEF_ "GenMsgStartDelayTime" 0 ;
BA_DEF_DEF_ "GenMsgSendType" "NoMsgSendType" ;
BA_DEF_DEF_ "GenMsgCycleTimeFast" 40 ;
BA_DEF_DEF_ "GenMsgDelayTime" 20 ;
BA_DEF_DEF_ "GenMsgILSupport" "Yes" ;
BA_DEF_DEF_ "GenMsgNrOfRepetition" 3 ;
BA_DEF_DEF_ "NmMessage" "No" ;
BA_DEF_DEF_ "NWM-Botschaft" "No" ;
BA_DEF_DEF_ "TpTxIndex" 0 ;
BA_DEF_DEF_ "VFrameFormat" "StandardCAN" ;
BA_DEF_DEF_ "UserSigValidity" "IG" ;
BA_DEF_DEF_ "UsrSigPurpose" "FN" ;
BA_DEF_DEF_ "GenSigStartValue" 0 ;
BA_DEF_DEF_ "NetworkRequest" "No" ;
BA_DEF_DEF_ "NetworkRequestHoldingTime" 0 ;
BA_DEF_DEF_ "Description" "" ;
BA_DEF_DEF_ "Version" "" ;
BA_DEF_DEF_ "GenSigEnvVarType" "Undef" ;
BA_DEF_DEF_ "GenSigSendType" "NoSigSendType" ;
BA_DEF_DEF_ "GwSigLatencyTime" 40 ;
BA_DEF_DEF_ "GwSigMissingSourceType" "Undef" ;
BA_DEF_DEF_ "NWM-WakeupAllowed" "<n.a.>" ;
BA_DEF_DEF_ "RoutingFactor" 1 ;
BA_DEF_DEF_REL_ "GenSigTimeoutTime" 500 ;
BA_ "DBName" "HS_B2";
BA_ "VersionYear" 1;
BA_ "VersionNumber" 220301;
BA_ "NmStationAddress" BU_ CGW_CCU 112;
BA_ "GenMsgSendType" BO_ 1050 0;
BA_ "NmStationAddress" BU_ FCS 33;
BA_ "NmStationAddress" BU_ WPC 30;
BA_ "NmStationAddress" BU_ RWPC 31;
BA_ "NmStationAddress" BU_ APSU 49;
BA_ "NmStationAddress" BU_ RLHV 52;
BA_ "NmStationAddress" BU_ RRHV 53;
BA_ "NmStationAddress" BU_ SHVU_FR 42;
BA_ "NmStationAddress" BU_ SHVU_RR 43;
BA_ "NmStationAddress" BU_ DPSU 56;
BA_ "NmStationAddress" BU_ WPC2 21;
BA_ "Description" SG_ 1050 Lamp_IntTailLmpOnReq "-(Old)C_INTTailOn";
BA_ "GenSigSendType" SG_ 1050 Lamp_IntTailLmpOnReq 4;
BA_ "UserSigValidity" SG_ 1050 Lamp_IntTailLmpOnReq 0;
BA_REL_ "GenSigTimeoutTime" BU_SG_REL_ FCS SG_ 1050 Lamp_IntTailLmpOnReq 1500;
BA_REL_ "GenSigTimeoutTime" BU_SG_REL_ WPC SG_ 1050 Lamp_IntTailLmpOnReq 1500;
BA_REL_ "GenSigTimeoutTime" BU_SG_REL_ RWPC SG_ 1050 Lamp_IntTailLmpOnReq 1500;
BA_REL_ "GenSigTimeoutTime" BU_SG_REL_ APSU SG_ 1050 Lamp_IntTailLmpOnReq 1500;
BA_REL_ "GenSigTimeoutTime" BU_SG_REL_ RLHV SG_ 1050 Lamp_IntTailLmpOnReq 1500;
BA_REL_ "GenSigTimeoutTime" BU_SG_REL_ RRHV SG_ 1050 Lamp_IntTailLmpOnReq 1500;
BA_REL_ "GenSigTimeoutTime" BU_SG_REL_ SHVU_FR SG_ 1050 Lamp_IntTailLmpOnReq 1500;
BA_REL_ "GenSigTimeoutTime" BU_SG_REL_ SHVU_RR SG_ 1050 Lamp_IntTailLmpOnReq 1500;
BA_REL_ "GenSigTimeoutTime" BU_SG_REL_ DPSU SG_ 1050 Lamp_IntTailLmpOnReq 1500;
BA_REL_ "GenSigTimeoutTime" BU_SG_REL_ WPC2 SG_ 1050 Lamp_IntTailLmpOnReq 1500;
BA_ "NetworkRequest" SG_ 1050 Lamp_IntTailLmpOnReq 0;
BA_ "NetworkRequestHoldingTime" SG_ 1050 Lamp_IntTailLmpOnReq 5000;
BA_ "Version" SG_ 1050 Lamp_IntTailLmpOnReq "17.12.00";
BA_ "GenMsgSendType" BO_ 1090 0;
BA_ "Description" SG_ 1090 BCM_SmkOptTyp "-(Old)C_PICOption";
BA_ "GenSigSendType" SG_ 1090 BCM_SmkOptTyp 4;
BA_ "UserSigValidity" SG_ 1090 BCM_SmkOptTyp 0;
BA_REL_ "GenSigTimeoutTime" BU_SG_REL_ WPC SG_ 1090 BCM_SmkOptTyp 1500;
BA_REL_ "GenSigTimeoutTime" BU_SG_REL_ RWPC SG_ 1090 BCM_SmkOptTyp 1500;
BA_REL_ "GenSigTimeoutTime" BU_SG_REL_ WPC2 SG_ 1090 BCM_SmkOptTyp 1500;
BA_ "NetworkRequest" SG_ 1090 BCM_SmkOptTyp 0;
BA_ "NetworkRequestHoldingTime" SG_ 1090 BCM_SmkOptTyp 5000;
BA_ "Version" SG_ 1090 BCM_SmkOptTyp "17.12.00";
BA_ "GenMsgSendType" BO_ 2256644609 0;
BA_ "GenMsgCycleTime" BO_ 2256644609 100;
BA_ "GenMsgCycleTimeFast" BO_ 2256644609 0;
BA_ "GenMsgNrOfRepetition" BO_ 2256644609 0;
BA_ "VFrameFormat" BO_ 2256644609 1;
BA_ "NmStationAddress" BU_ SWRC 8;
BA_ "NmStationAddress" BU_ RCS 70;
BA_ "NmStationAddress" BU_ RRPSU 29;
BA_ "NmStationAddress" BU_ RLPSU 28;
BA_ "NmStationAddress" BU_ ATS 80;
BA_ "NmStationAddress" BU_ DSAU 89;
BA_ "NmStationAddress" BU_ ASAU 83;
BA_ "NmStationAddress" BU_ OHCL 84;
BA_ "Description" SG_ 2256644609 CLU_DtntOutSta "This signal indicates the status of detent illumination. Cluster sends the detent information for a Unified Illumination system.";
BA_ "UserSigValidity" SG_ 2256644609 CLU_DtntOutSta 0;
BA_REL_ "GenSigTimeoutTime" BU_SG_REL_ FCS SG_ 2256644609 CLU_DtntOutSta 1500;
BA_REL_ "GenSigTimeoutTime" BU_SG_REL_ WPC SG_ 2256644609 CLU_DtntOutSta 1500;
BA_REL_ "GenSigTimeoutTime" BU_SG_REL_ RWPC SG_ 2256644609 CLU_DtntOutSta 1500;
BA_REL_ "GenSigTimeoutTime" BU_SG_REL_ SWRC SG_ 2256644609 CLU_DtntOutSta 1500;
BA_REL_ "GenSigTimeoutTime" BU_SG_REL_ APSU SG_ 2256644609 CLU_DtntOutSta 1500;
BA_REL_ "GenSigTimeoutTime" BU_SG_REL_ RLHV SG_ 2256644609 CLU_DtntOutSta 1500;
BA_REL_ "GenSigTimeoutTime" BU_SG_REL_ RRHV SG_ 2256644609 CLU_DtntOutSta 1500;
BA_REL_ "GenSigTimeoutTime" BU_SG_REL_ SHVU_FR SG_ 2256644609 CLU_DtntOutSta 1500;
BA_REL_ "GenSigTimeoutTime" BU_SG_REL_ SHVU_RR SG_ 2256644609 CLU_DtntOutSta 1500;
BA_REL_ "GenSigTimeoutTime" BU_SG_REL_ DPSU SG_ 2256644609 CLU_DtntOutSta 1500;
BA_REL_ "GenSigTimeoutTime" BU_SG_REL_ RCS SG_ 2256644609 CLU_DtntOutSta 1500;
BA_REL_ "GenSigTimeoutTime" BU_SG_REL_ RRPSU SG_ 2256644609 CLU_DtntOutSta 1500;
BA_REL_ "GenSigTimeoutTime" BU_SG_REL_ RLPSU SG_ 2256644609 CLU_DtntOutSta 1500;
BA_REL_ "GenSigTimeoutTime" BU_SG_REL_ ATS SG_ 2256644609 CLU_DtntOutSta 1500;
BA_REL_ "GenSigTimeoutTime" BU_SG_REL_ DSAU SG_ 2256644609 CLU_DtntOutSta 1500;
BA_REL_ "GenSigTimeoutTime" BU_SG_REL_ ASAU SG_ 2256644609 CLU_DtntOutSta 1500;
BA_REL_ "GenSigTimeoutTime" BU_SG_REL_ OHCL SG_ 2256644609 CLU_DtntOutSta 1500;
BA_REL_ "GenSigTimeoutTime" BU_SG_REL_ WPC2 SG_ 2256644609 CLU_DtntOutSta 1500;
BA_ "RoutingFactor" SG_ 2256644609 CLU_DtntOutSta 5;
BA_ "Version" SG_ 2256644609 CLU_DtntOutSta "17.11.00";
BA_ "Description" SG_ 2256644609 CLU_RhstaLvlSta "This signal is used for a rheostat level of CLUSTER from 1 to 21 level (21 level : Detent) for a Unified Illumination system.



『 Start Value : Current value";
BA_ "UserSigValidity" SG_ 2256644609 CLU_RhstaLvlSta 0;
BA_REL_ "GenSigTimeoutTime" BU_SG_REL_ FCS SG_ 2256644609 CLU_RhstaLvlSta 1500;
BA_REL_ "GenSigTimeoutTime" BU_SG_REL_ WPC SG_ 2256644609 CLU_RhstaLvlSta 1500;
BA_REL_ "GenSigTimeoutTime" BU_SG_REL_ RWPC SG_ 2256644609 CLU_RhstaLvlSta 1500;
BA_REL_ "GenSigTimeoutTime" BU_SG_REL_ SWRC SG_ 2256644609 CLU_RhstaLvlSta 1500;
BA_REL_ "GenSigTimeoutTime" BU_SG_REL_ APSU SG_ 2256644609 CLU_RhstaLvlSta 1500;
BA_REL_ "GenSigTimeoutTime" BU_SG_REL_ RLHV SG_ 2256644609 CLU_RhstaLvlSta 1500;
BA_REL_ "GenSigTimeoutTime" BU_SG_REL_ RRHV SG_ 2256644609 CLU_RhstaLvlSta 1500;
BA_REL_ "GenSigTimeoutTime" BU_SG_REL_ SHVU_FR SG_ 2256644609 CLU_RhstaLvlSta 1500;
BA_REL_ "GenSigTimeoutTime" BU_SG_REL_ SHVU_RR SG_ 2256644609 CLU_RhstaLvlSta 1500;
BA_REL_ "GenSigTimeoutTime" BU_SG_REL_ DPSU SG_ 2256644609 CLU_RhstaLvlSta 1500;
BA_REL_ "GenSigTimeoutTime" BU_SG_REL_ RCS SG_ 2256644609 CLU_RhstaLvlSta 1500;
BA_REL_ "GenSigTimeoutTime" BU_SG_REL_ RRPSU SG_ 2256644609 CLU_RhstaLvlSta 1500;
BA_REL_ "GenSigTimeoutTime" BU_SG_REL_ RLPSU SG_ 2256644609 CLU_RhstaLvlSta 1500;
BA_REL_ "GenSigTimeoutTime" BU_SG_REL_ ATS SG_ 2256644609 CLU_RhstaLvlSta 1500;
BA_REL_ "GenSigTimeoutTime" BU_SG_REL_ DSAU SG_ 2256644609 CLU_RhstaLvlSta 1500;
BA_REL_ "GenSigTimeoutTime" BU_SG_REL_ ASAU SG_ 2256644609 CLU_RhstaLvlSta 1500;
BA_REL_ "GenSigTimeoutTime" BU_SG_REL_ OHCL SG_ 2256644609 CLU_RhstaLvlSta 1500;
BA_REL_ "GenSigTimeoutTime" BU_SG_REL_ WPC2 SG_ 2256644609 CLU_RhstaLvlSta 1500;
BA_ "RoutingFactor" SG_ 2256644609 CLU_RhstaLvlSta 5;
BA_ "Version" SG_ 2256644609 CLU_RhstaLvlSta "17.11.00";
BA_ "GenMsgSendType" BO_ 2256644610 0;
BA_ "GenMsgCycleTime" BO_ 2256644610 100;
BA_ "GenMsgCycleTimeFast" BO_ 2256644610 0;
BA_ "GenMsgNrOfRepetition" BO_ 2256644610 0;
BA_ "VFrameFormat" BO_ 2256644610 1;
BA_ "NmStationAddress" BU_ DLBCU 64;
BA_ "NmStationAddress" BU_ PFSU 45;
BA_ "NmStationAddress" BU_ RCM 61;
BA_ "NmStationAddress" BU_ ALBCU 68;
BA_ "Description" SG_ 2256644610 CLU_DisSpdVal_KPH "The vehicle speed which is indicated in the speedmeter.

This signal should be sent in km/h only.";
BA_ "UserSigValidity" SG_ 2256644610 CLU_DisSpdVal_KPH 3;
BA_REL_ "GenSigTimeoutTime" BU_SG_REL_ WPC SG_ 2256644610 CLU_DisSpdVal_KPH 1500;
BA_REL_ "GenSigTimeoutTime" BU_SG_REL_ RWPC SG_ 2256644610 CLU_DisSpdVal_KPH 1500;
BA_REL_ "GenSigTimeoutTime" BU_SG_REL_ APSU SG_ 2256644610 CLU_DisSpdVal_KPH 1500;
BA_REL_ "GenSigTimeoutTime" BU_SG_REL_ RLHV SG_ 2256644610 CLU_DisSpdVal_KPH 1500;
BA_REL_ "GenSigTimeoutTime" BU_SG_REL_ RRHV SG_ 2256644610 CLU_DisSpdVal_KPH 1500;
BA_REL_ "GenSigTimeoutTime" BU_SG_REL_ SHVU_FR SG_ 2256644610 CLU_DisSpdVal_KPH 1500;
BA_REL_ "GenSigTimeoutTime" BU_SG_REL_ SHVU_RR SG_ 2256644610 CLU_DisSpdVal_KPH 1500;
BA_REL_ "GenSigTimeoutTime" BU_SG_REL_ DPSU SG_ 2256644610 CLU_DisSpdVal_KPH 1500;
BA_REL_ "GenSigTimeoutTime" BU_SG_REL_ DLBCU SG_ 2256644610 CLU_DisSpdVal_KPH 1500;
BA_REL_ "GenSigTimeoutTime" BU_SG_REL_ PFSU SG_ 2256644610 CLU_DisSpdVal_KPH 1500;
BA_REL_ "GenSigTimeoutTime" BU_SG_REL_ RRPSU SG_ 2256644610 CLU_DisSpdVal_KPH 1500;
BA_REL_ "GenSigTimeoutTime" BU_SG_REL_ RLPSU SG_ 2256644610 CLU_DisSpdVal_KPH 1500;
BA_REL_ "GenSigTimeoutTime" BU_SG_REL_ ATS SG_ 2256644610 CLU_DisSpdVal_KPH 1500;
BA_REL_ "GenSigTimeoutTime" BU_SG_REL_ DSAU SG_ 2256644610 CLU_DisSpdVal_KPH 1500;
BA_REL_ "GenSigTimeoutTime" BU_SG_REL_ ASAU SG_ 2256644610 CLU_DisSpdVal_KPH 1500;
BA_REL_ "GenSigTimeoutTime" BU_SG_REL_ RCM SG_ 2256644610 CLU_DisSpdVal_KPH 1500;
BA_REL_ "GenSigTimeoutTime" BU_SG_REL_ ALBCU SG_ 2256644610 CLU_DisSpdVal_KPH 1500;
BA_REL_ "GenSigTimeoutTime" BU_SG_REL_ WPC2 SG_ 2256644610 CLU_DisSpdVal_KPH 1500;
BA_ "RoutingFactor" SG_ 2256644610 CLU_DisSpdVal_KPH 5;
BA_ "Version" SG_ 2256644610 CLU_DisSpdVal_KPH "17.12.09";
BA_ "NmStationAddress" BU_ BLTN_CAM 72;
BA_ "Description" SG_ 2256644610 CLU_AutoBrightSta "This signal is used for a auto bright level of CLUSTER from 1step to 200step for a Unified Illumination system.



『 Start Value : Current value";
BA_ "UserSigValidity" SG_ 2256644610 CLU_AutoBrightSta 0;
BA_REL_ "GenSigTimeoutTime" BU_SG_REL_ FCS SG_ 2256644610 CLU_AutoBrightSta 1500;
BA_REL_ "GenSigTimeoutTime" BU_SG_REL_ WPC SG_ 2256644610 CLU_AutoBrightSta 1500;
BA_REL_ "GenSigTimeoutTime" BU_SG_REL_ RWPC SG_ 2256644610 CLU_AutoBrightSta 1500;
BA_REL_ "GenSigTimeoutTime" BU_SG_REL_ SWRC SG_ 2256644610 CLU_AutoBrightSta 1500;
BA_REL_ "GenSigTimeoutTime" BU_SG_REL_ APSU SG_ 2256644610 CLU_AutoBrightSta 1500;
BA_REL_ "GenSigTimeoutTime" BU_SG_REL_ RLHV SG_ 2256644610 CLU_AutoBrightSta 1500;
BA_REL_ "GenSigTimeoutTime" BU_SG_REL_ RRHV SG_ 2256644610 CLU_AutoBrightSta 1500;
BA_REL_ "GenSigTimeoutTime" BU_SG_REL_ SHVU_FR SG_ 2256644610 CLU_AutoBrightSta 1500;
BA_REL_ "GenSigTimeoutTime" BU_SG_REL_ SHVU_RR SG_ 2256644610 CLU_AutoBrightSta 1500;
BA_REL_ "GenSigTimeoutTime" BU_SG_REL_ DPSU SG_ 2256644610 CLU_AutoBrightSta 1500;
BA_REL_ "GenSigTimeoutTime" BU_SG_REL_ RCS SG_ 2256644610 CLU_AutoBrightSta 1500;
BA_REL_ "GenSigTimeoutTime" BU_SG_REL_ ATS SG_ 2256644610 CLU_AutoBrightSta 1500;
BA_REL_ "GenSigTimeoutTime" BU_SG_REL_ DSAU SG_ 2256644610 CLU_AutoBrightSta 1500;
BA_REL_ "GenSigTimeoutTime" BU_SG_REL_ ASAU SG_ 2256644610 CLU_AutoBrightSta 1500;
BA_REL_ "GenSigTimeoutTime" BU_SG_REL_ OHCL SG_ 2256644610 CLU_AutoBrightSta 1500;
BA_REL_ "GenSigTimeoutTime" BU_SG_REL_ BLTN_CAM SG_ 2256644610 CLU_AutoBrightSta 1500;
BA_REL_ "GenSigTimeoutTime" BU_SG_REL_ WPC2 SG_ 2256644610 CLU_AutoBrightSta 1500;
BA_ "RoutingFactor" SG_ 2256644610 CLU_AutoBrightSta 5;
BA_ "Version" SG_ 2256644610 CLU_AutoBrightSta "20.12.05";
BA_ "GenMsgCycleTime" BO_ 2470760705 0;
BA_ "VFrameFormat" BO_ 2470760705 1;
BA_ "Description" SG_ 2470760705 USM_StaRst1Req "This signal is used for a request to reset the value of USM menus.

When this signal change, the message (CLU16) is sent 3 times.";
BA_ "GenSigSendType" SG_ 2470760705 USM_StaRst1Req 4;
BA_ "UserSigValidity" SG_ 2470760705 USM_StaRst1Req 3;
BA_REL_ "GenSigTimeoutTime" BU_SG_REL_ WPC SG_ 2470760705 USM_StaRst1Req 0;
BA_REL_ "GenSigTimeoutTime" BU_SG_REL_ DPSU SG_ 2470760705 USM_StaRst1Req 0;
BA_REL_ "GenSigTimeoutTime" BU_SG_REL_ WPC2 SG_ 2470760705 USM_StaRst1Req 0;
BA_ "Version" SG_ 2470760705 USM_StaRst1Req "17.11.00";
BA_ "GenMsgCycleTime" BO_ 2470763009 0;
BA_ "VFrameFormat" BO_ 2470763009 1;
BA_ "Description" SG_ 2470763009 USM_WpcSetReq "USM Function for WPC(Wireless Phone Chager) on/off SW";
BA_ "GenSigSendType" SG_ 2470763009 USM_WpcSetReq 4;
BA_ "UserSigValidity" SG_ 2470763009 USM_WpcSetReq 3;
BA_REL_ "GenSigTimeoutTime" BU_SG_REL_ WPC SG_ 2470763009 USM_WpcSetReq 0;
BA_REL_ "GenSigTimeoutTime" BU_SG_REL_ WPC2 SG_ 2470763009 USM_WpcSetReq 0;
BA_ "Version" SG_ 2470763009 USM_WpcSetReq "17.11.00";
BA_ "GenMsgSendType" BO_ 2353206529 0;
BA_ "GenMsgCycleTimeFast" BO_ 2353206529 0;
BA_ "GenMsgNrOfRepetition" BO_ 2353206529 0;
BA_ "VFrameFormat" BO_ 2353206529 1;
BA_ "Description" SG_ 2353206529 CLU_ClusterUSM "USM application of Cluster

If USM is applied in Cluster, Signal send 0x1";
BA_ "UserSigValidity" SG_ 2353206529 CLU_ClusterUSM 3;
BA_REL_ "GenSigTimeoutTime" BU_SG_REL_ WPC SG_ 2353206529 CLU_ClusterUSM 1500;
BA_REL_ "GenSigTimeoutTime" BU_SG_REL_ WPC2 SG_ 2353206529 CLU_ClusterUSM 1500;
BA_ "Version" SG_ 2353206529 CLU_ClusterUSM "20.06.05";
BA_ "GenMsgSendType" BO_ 2214658049 0;
BA_ "GenMsgCycleTime" BO_ 2214658049 50;
BA_ "GenMsgCycleTimeFast" BO_ 2214658049 0;
BA_ "GenMsgNrOfRepetition" BO_ 2214658049 0;
BA_ "VFrameFormat" BO_ 2214658049 1;
BA_ "NmStationAddress" BU_ SCM 7;
BA_ "NmStationAddress" BU_ HOD 74;
BA_ "NmStationAddress" BU_ EMCU 17;
BA_ "Description" SG_ 2214658049 ENG_EngSta "This signal indicates that a status of engine.";
BA_ "UserSigValidity" SG_ 2214658049 ENG_EngSta 3;
BA_ "RoutingFactor" SG_ 2214658049 ENG_EngSta 5;
BA_ "Version" SG_ 2214658049 ENG_EngSta "17.12.00";
BA_ "GenMsgSendType" BO_ 2214659330 0;
BA_ "GenMsgCycleTime" BO_ 2214659330 50;
BA_ "GenMsgCycleTimeFast" BO_ 2214659330 0;
BA_ "GenMsgNrOfRepetition" BO_ 2214659330 0;
BA_ "VFrameFormat" BO_ 2214659330 1;
BA_ "Description" SG_ 2214659330 HEV_EngOpSta "Engine Operating State";
BA_ "UserSigValidity" SG_ 2214659330 HEV_EngOpSta 3;
BA_ "RoutingFactor" SG_ 2214659330 HEV_EngOpSta 5;
BA_ "Version" SG_ 2214659330 HEV_EngOpSta "18.05.04";
BA_ "GenMsgCycleTime" BO_ 2015 0;
BA_ "GenMsgCycleTimeFast" BO_ 2015 0;
BA_ "GenMsgNrOfRepetition" BO_ 2015 0;
BA_ "DiagState" BO_ 2015 1;
BA_ "GenMsgILSupport" BO_ 2015 0;
BA_ "TpMessage" BO_ 2015 1;
BA_ "NmStationAddress" BU_ PSB 65;
BA_ "NmStationAddress" BU_ SLB 27;
BA_ "NmStationAddress" BU_ ARS 10;
BA_ "NmStationAddress" BU_ SGU 62;
BA_ "Description" SG_ 2015 GST_ALL_Byte0 "TP Index : 0";
BA_ "UsrSigPurpose" SG_ 2015 GST_ALL_Byte0 0;
BA_ "UserSigValidity" SG_ 2015 GST_ALL_Byte0 0;
BA_REL_ "GenSigTimeoutTime" BU_SG_REL_ FCS SG_ 2015 GST_ALL_Byte0 0;
BA_REL_ "GenSigTimeoutTime" BU_SG_REL_ SCM SG_ 2015 GST_ALL_Byte0 0;
BA_REL_ "GenSigTimeoutTime" BU_SG_REL_ WPC SG_ 2015 GST_ALL_Byte0 0;
BA_REL_ "GenSigTimeoutTime" BU_SG_REL_ RWPC SG_ 2015 GST_ALL_Byte0 0;
BA_REL_ "GenSigTimeoutTime" BU_SG_REL_ PSB SG_ 2015 GST_ALL_Byte0 0;
BA_REL_ "GenSigTimeoutTime" BU_SG_REL_ SLB SG_ 2015 GST_ALL_Byte0 0;
BA_REL_ "GenSigTimeoutTime" BU_SG_REL_ ARS SG_ 2015 GST_ALL_Byte0 0;
BA_REL_ "GenSigTimeoutTime" BU_SG_REL_ SWRC SG_ 2015 GST_ALL_Byte0 0;
BA_REL_ "GenSigTimeoutTime" BU_SG_REL_ APSU SG_ 2015 GST_ALL_Byte0 0;
BA_REL_ "GenSigTimeoutTime" BU_SG_REL_ RLHV SG_ 2015 GST_ALL_Byte0 0;
BA_REL_ "GenSigTimeoutTime" BU_SG_REL_ RRHV SG_ 2015 GST_ALL_Byte0 0;
BA_REL_ "GenSigTimeoutTime" BU_SG_REL_ SHVU_FR SG_ 2015 GST_ALL_Byte0 0;
BA_REL_ "GenSigTimeoutTime" BU_SG_REL_ SHVU_RR SG_ 2015 GST_ALL_Byte0 0;
BA_REL_ "GenSigTimeoutTime" BU_SG_REL_ DPSU SG_ 2015 GST_ALL_Byte0 0;
BA_REL_ "GenSigTimeoutTime" BU_SG_REL_ DLBCU SG_ 2015 GST_ALL_Byte0 0;
BA_REL_ "GenSigTimeoutTime" BU_SG_REL_ PFSU SG_ 2015 GST_ALL_Byte0 0;
BA_REL_ "GenSigTimeoutTime" BU_SG_REL_ RCS SG_ 2015 GST_ALL_Byte0 0;
BA_REL_ "GenSigTimeoutTime" BU_SG_REL_ RRPSU SG_ 2015 GST_ALL_Byte0 0;
BA_REL_ "GenSigTimeoutTime" BU_SG_REL_ RLPSU SG_ 2015 GST_ALL_Byte0 0;
BA_REL_ "GenSigTimeoutTime" BU_SG_REL_ HOD SG_ 2015 GST_ALL_Byte0 0;
BA_REL_ "GenSigTimeoutTime" BU_SG_REL_ ATS SG_ 2015 GST_ALL_Byte0 0;
BA_REL_ "GenSigTimeoutTime" BU_SG_REL_ DSAU SG_ 2015 GST_ALL_Byte0 0;
BA_REL_ "GenSigTimeoutTime" BU_SG_REL_ ASAU SG_ 2015 GST_ALL_Byte0 0;
BA_REL_ "GenSigTimeoutTime" BU_SG_REL_ RCM SG_ 2015 GST_ALL_Byte0 0;
BA_REL_ "GenSigTimeoutTime" BU_SG_REL_ EMCU SG_ 2015 GST_ALL_Byte0 0;
BA_REL_ "GenSigTimeoutTime" BU_SG_REL_ SGU SG_ 2015 GST_ALL_Byte0 0;
BA_REL_ "GenSigTimeoutTime" BU_SG_REL_ ALBCU SG_ 2015 GST_ALL_Byte0 0;
BA_REL_ "GenSigTimeoutTime" BU_SG_REL_ WPC2 SG_ 2015 GST_ALL_Byte0 0;
BA_ "NetworkRequest" SG_ 2015 GST_ALL_Byte0 0;
BA_ "NetworkRequestHoldingTime" SG_ 2015 GST_ALL_Byte0 5000;
BA_ "Version" SG_ 2015 GST_ALL_Byte0 "21.02.04";
BA_ "Description" SG_ 2015 GST_ALL_Byte2 "TP Index : 0";
BA_ "UsrSigPurpose" SG_ 2015 GST_ALL_Byte2 0;
BA_ "UserSigValidity" SG_ 2015 GST_ALL_Byte2 0;
BA_REL_ "GenSigTimeoutTime" BU_SG_REL_ FCS SG_ 2015 GST_ALL_Byte2 0;
BA_REL_ "GenSigTimeoutTime" BU_SG_REL_ SCM SG_ 2015 GST_ALL_Byte2 0;
BA_REL_ "GenSigTimeoutTime" BU_SG_REL_ WPC SG_ 2015 GST_ALL_Byte2 0;
BA_REL_ "GenSigTimeoutTime" BU_SG_REL_ RWPC SG_ 2015 GST_ALL_Byte2 0;
BA_REL_ "GenSigTimeoutTime" BU_SG_REL_ PSB SG_ 2015 GST_ALL_Byte2 0;
BA_REL_ "GenSigTimeoutTime" BU_SG_REL_ SLB SG_ 2015 GST_ALL_Byte2 0;
BA_REL_ "GenSigTimeoutTime" BU_SG_REL_ ARS SG_ 2015 GST_ALL_Byte2 0;
BA_REL_ "GenSigTimeoutTime" BU_SG_REL_ SWRC SG_ 2015 GST_ALL_Byte2 0;
BA_REL_ "GenSigTimeoutTime" BU_SG_REL_ APSU SG_ 2015 GST_ALL_Byte2 0;
BA_REL_ "GenSigTimeoutTime" BU_SG_REL_ RLHV SG_ 2015 GST_ALL_Byte2 0;
BA_REL_ "GenSigTimeoutTime" BU_SG_REL_ RRHV SG_ 2015 GST_ALL_Byte2 0;
BA_REL_ "GenSigTimeoutTime" BU_SG_REL_ SHVU_FR SG_ 2015 GST_ALL_Byte2 0;
BA_REL_ "GenSigTimeoutTime" BU_SG_REL_ SHVU_RR SG_ 2015 GST_ALL_Byte2 0;
BA_REL_ "GenSigTimeoutTime" BU_SG_REL_ DPSU SG_ 2015 GST_ALL_Byte2 0;
BA_REL_ "GenSigTimeoutTime" BU_SG_REL_ DLBCU SG_ 2015 GST_ALL_Byte2 0;
BA_REL_ "GenSigTimeoutTime" BU_SG_REL_ PFSU SG_ 2015 GST_ALL_Byte2 0;
BA_REL_ "GenSigTimeoutTime" BU_SG_REL_ RCS SG_ 2015 GST_ALL_Byte2 0;
BA_REL_ "GenSigTimeoutTime" BU_SG_REL_ RRPSU SG_ 2015 GST_ALL_Byte2 0;
BA_REL_ "GenSigTimeoutTime" BU_SG_REL_ RLPSU SG_ 2015 GST_ALL_Byte2 0;
BA_REL_ "GenSigTimeoutTime" BU_SG_REL_ HOD SG_ 2015 GST_ALL_Byte2 0;
BA_REL_ "GenSigTimeoutTime" BU_SG_REL_ ATS SG_ 2015 GST_ALL_Byte2 0;
BA_REL_ "GenSigTimeoutTime" BU_SG_REL_ DSAU SG_ 2015 GST_ALL_Byte2 0;
BA_REL_ "GenSigTimeoutTime" BU_SG_REL_ ASAU SG_ 2015 GST_ALL_Byte2 0;
BA_REL_ "GenSigTimeoutTime" BU_SG_REL_ RCM SG_ 2015 GST_ALL_Byte2 0;
BA_REL_ "GenSigTimeoutTime" BU_SG_REL_ EMCU SG_ 2015 GST_ALL_Byte2 0;
BA_REL_ "GenSigTimeoutTime" BU_SG_REL_ SGU SG_ 2015 GST_ALL_Byte2 0;
BA_REL_ "GenSigTimeoutTime" BU_SG_REL_ ALBCU SG_ 2015 GST_ALL_Byte2 0;
BA_REL_ "GenSigTimeoutTime" BU_SG_REL_ WPC2 SG_ 2015 GST_ALL_Byte2 0;
BA_ "NetworkRequest" SG_ 2015 GST_ALL_Byte2 0;
BA_ "NetworkRequestHoldingTime" SG_ 2015 GST_ALL_Byte2 5000;
BA_ "Version" SG_ 2015 GST_ALL_Byte2 "21.02.04";
BA_ "Description" SG_ 2015 GST_ALL_Byte3 "TP Index : 0";
BA_ "UsrSigPurpose" SG_ 2015 GST_ALL_Byte3 0;
BA_ "UserSigValidity" SG_ 2015 GST_ALL_Byte3 0;
BA_REL_ "GenSigTimeoutTime" BU_SG_REL_ FCS SG_ 2015 GST_ALL_Byte3 0;
BA_REL_ "GenSigTimeoutTime" BU_SG_REL_ SCM SG_ 2015 GST_ALL_Byte3 0;
BA_REL_ "GenSigTimeoutTime" BU_SG_REL_ WPC SG_ 2015 GST_ALL_Byte3 0;
BA_REL_ "GenSigTimeoutTime" BU_SG_REL_ RWPC SG_ 2015 GST_ALL_Byte3 0;
BA_REL_ "GenSigTimeoutTime" BU_SG_REL_ PSB SG_ 2015 GST_ALL_Byte3 0;
BA_REL_ "GenSigTimeoutTime" BU_SG_REL_ SLB SG_ 2015 GST_ALL_Byte3 0;
BA_REL_ "GenSigTimeoutTime" BU_SG_REL_ ARS SG_ 2015 GST_ALL_Byte3 0;
BA_REL_ "GenSigTimeoutTime" BU_SG_REL_ SWRC SG_ 2015 GST_ALL_Byte3 0;
BA_REL_ "GenSigTimeoutTime" BU_SG_REL_ APSU SG_ 2015 GST_ALL_Byte3 0;
BA_REL_ "GenSigTimeoutTime" BU_SG_REL_ RLHV SG_ 2015 GST_ALL_Byte3 0;
BA_REL_ "GenSigTimeoutTime" BU_SG_REL_ RRHV SG_ 2015 GST_ALL_Byte3 0;
BA_REL_ "GenSigTimeoutTime" BU_SG_REL_ SHVU_FR SG_ 2015 GST_ALL_Byte3 0;
BA_REL_ "GenSigTimeoutTime" BU_SG_REL_ SHVU_RR SG_ 2015 GST_ALL_Byte3 0;
BA_REL_ "GenSigTimeoutTime" BU_SG_REL_ DPSU SG_ 2015 GST_ALL_Byte3 0;
BA_REL_ "GenSigTimeoutTime" BU_SG_REL_ DLBCU SG_ 2015 GST_ALL_Byte3 0;
BA_REL_ "GenSigTimeoutTime" BU_SG_REL_ PFSU SG_ 2015 GST_ALL_Byte3 0;
BA_REL_ "GenSigTimeoutTime" BU_SG_REL_ RCS SG_ 2015 GST_ALL_Byte3 0;
BA_REL_ "GenSigTimeoutTime" BU_SG_REL_ RRPSU SG_ 2015 GST_ALL_Byte3 0;
BA_REL_ "GenSigTimeoutTime" BU_SG_REL_ RLPSU SG_ 2015 GST_ALL_Byte3 0;
BA_REL_ "GenSigTimeoutTime" BU_SG_REL_ HOD SG_ 2015 GST_ALL_Byte3 0;
BA_REL_ "GenSigTimeoutTime" BU_SG_REL_ ATS SG_ 2015 GST_ALL_Byte3 0;
BA_REL_ "GenSigTimeoutTime" BU_SG_REL_ DSAU SG_ 2015 GST_ALL_Byte3 0;
BA_REL_ "GenSigTimeoutTime" BU_SG_REL_ ASAU SG_ 2015 GST_ALL_Byte3 0;
BA_REL_ "GenSigTimeoutTime" BU_SG_REL_ RCM SG_ 2015 GST_ALL_Byte3 0;
BA_REL_ "GenSigTimeoutTime" BU_SG_REL_ EMCU SG_ 2015 GST_ALL_Byte3 0;
BA_REL_ "GenSigTimeoutTime" BU_SG_REL_ SGU SG_ 2015 GST_ALL_Byte3 0;
BA_REL_ "GenSigTimeoutTime" BU_SG_REL_ ALBCU SG_ 2015 GST_ALL_Byte3 0;
BA_REL_ "GenSigTimeoutTime" BU_SG_REL_ WPC2 SG_ 2015 GST_ALL_Byte3 0;
BA_ "NetworkRequest" SG_ 2015 GST_ALL_Byte3 0;
BA_ "NetworkRequestHoldingTime" SG_ 2015 GST_ALL_Byte3 5000;
BA_ "Version" SG_ 2015 GST_ALL_Byte3 "21.02.04";
BA_ "Description" SG_ 2015 GST_ALL_Byte4 "TP Index : 0";
BA_ "UsrSigPurpose" SG_ 2015 GST_ALL_Byte4 0;
BA_ "UserSigValidity" SG_ 2015 GST_ALL_Byte4 0;
BA_REL_ "GenSigTimeoutTime" BU_SG_REL_ FCS SG_ 2015 GST_ALL_Byte4 0;
BA_REL_ "GenSigTimeoutTime" BU_SG_REL_ SCM SG_ 2015 GST_ALL_Byte4 0;
BA_REL_ "GenSigTimeoutTime" BU_SG_REL_ WPC SG_ 2015 GST_ALL_Byte4 0;
BA_REL_ "GenSigTimeoutTime" BU_SG_REL_ RWPC SG_ 2015 GST_ALL_Byte4 0;
BA_REL_ "GenSigTimeoutTime" BU_SG_REL_ PSB SG_ 2015 GST_ALL_Byte4 0;
BA_REL_ "GenSigTimeoutTime" BU_SG_REL_ SLB SG_ 2015 GST_ALL_Byte4 0;
BA_REL_ "GenSigTimeoutTime" BU_SG_REL_ ARS SG_ 2015 GST_ALL_Byte4 0;
BA_REL_ "GenSigTimeoutTime" BU_SG_REL_ SWRC SG_ 2015 GST_ALL_Byte4 0;
BA_REL_ "GenSigTimeoutTime" BU_SG_REL_ APSU SG_ 2015 GST_ALL_Byte4 0;
BA_REL_ "GenSigTimeoutTime" BU_SG_REL_ RLHV SG_ 2015 GST_ALL_Byte4 0;
BA_REL_ "GenSigTimeoutTime" BU_SG_REL_ RRHV SG_ 2015 GST_ALL_Byte4 0;
BA_REL_ "GenSigTimeoutTime" BU_SG_REL_ SHVU_FR SG_ 2015 GST_ALL_Byte4 0;
BA_REL_ "GenSigTimeoutTime" BU_SG_REL_ SHVU_RR SG_ 2015 GST_ALL_Byte4 0;
BA_REL_ "GenSigTimeoutTime" BU_SG_REL_ DPSU SG_ 2015 GST_ALL_Byte4 0;
BA_REL_ "GenSigTimeoutTime" BU_SG_REL_ DLBCU SG_ 2015 GST_ALL_Byte4 0;
BA_REL_ "GenSigTimeoutTime" BU_SG_REL_ PFSU SG_ 2015 GST_ALL_Byte4 0;
BA_REL_ "GenSigTimeoutTime" BU_SG_REL_ RCS SG_ 2015 GST_ALL_Byte4 0;
BA_REL_ "GenSigTimeoutTime" BU_SG_REL_ RRPSU SG_ 2015 GST_ALL_Byte4 0;
BA_REL_ "GenSigTimeoutTime" BU_SG_REL_ RLPSU SG_ 2015 GST_ALL_Byte4 0;
BA_REL_ "GenSigTimeoutTime" BU_SG_REL_ HOD SG_ 2015 GST_ALL_Byte4 0;
BA_REL_ "GenSigTimeoutTime" BU_SG_REL_ ATS SG_ 2015 GST_ALL_Byte4 0;
BA_REL_ "GenSigTimeoutTime" BU_SG_REL_ DSAU SG_ 2015 GST_ALL_Byte4 0;
BA_REL_ "GenSigTimeoutTime" BU_SG_REL_ ASAU SG_ 2015 GST_ALL_Byte4 0;
BA_REL_ "GenSigTimeoutTime" BU_SG_REL_ RCM SG_ 2015 GST_ALL_Byte4 0;
BA_REL_ "GenSigTimeoutTime" BU_SG_REL_ EMCU SG_ 2015 GST_ALL_Byte4 0;
BA_REL_ "GenSigTimeoutTime" BU_SG_REL_ SGU SG_ 2015 GST_ALL_Byte4 0;
BA_REL_ "GenSigTimeoutTime" BU_SG_REL_ ALBCU SG_ 2015 GST_ALL_Byte4 0;
BA_REL_ "GenSigTimeoutTime" BU_SG_REL_ WPC2 SG_ 2015 GST_ALL_Byte4 0;
BA_ "NetworkRequest" SG_ 2015 GST_ALL_Byte4 0;
BA_ "NetworkRequestHoldingTime" SG_ 2015 GST_ALL_Byte4 5000;
BA_ "Version" SG_ 2015 GST_ALL_Byte4 "21.02.04";
BA_ "Description" SG_ 2015 GST_ALL_Byte5 "TP Index : 0";
BA_ "UsrSigPurpose" SG_ 2015 GST_ALL_Byte5 0;
BA_ "UserSigValidity" SG_ 2015 GST_ALL_Byte5 0;
BA_REL_ "GenSigTimeoutTime" BU_SG_REL_ FCS SG_ 2015 GST_ALL_Byte5 0;
BA_REL_ "GenSigTimeoutTime" BU_SG_REL_ SCM SG_ 2015 GST_ALL_Byte5 0;
BA_REL_ "GenSigTimeoutTime" BU_SG_REL_ WPC SG_ 2015 GST_ALL_Byte5 0;
BA_REL_ "GenSigTimeoutTime" BU_SG_REL_ RWPC SG_ 2015 GST_ALL_Byte5 0;
BA_REL_ "GenSigTimeoutTime" BU_SG_REL_ PSB SG_ 2015 GST_ALL_Byte5 0;
BA_REL_ "GenSigTimeoutTime" BU_SG_REL_ SLB SG_ 2015 GST_ALL_Byte5 0;
BA_REL_ "GenSigTimeoutTime" BU_SG_REL_ ARS SG_ 2015 GST_ALL_Byte5 0;
BA_REL_ "GenSigTimeoutTime" BU_SG_REL_ SWRC SG_ 2015 GST_ALL_Byte5 0;
BA_REL_ "GenSigTimeoutTime" BU_SG_REL_ APSU SG_ 2015 GST_ALL_Byte5 0;
BA_REL_ "GenSigTimeoutTime" BU_SG_REL_ RLHV SG_ 2015 GST_ALL_Byte5 0;
BA_REL_ "GenSigTimeoutTime" BU_SG_REL_ RRHV SG_ 2015 GST_ALL_Byte5 0;
BA_REL_ "GenSigTimeoutTime" BU_SG_REL_ SHVU_FR SG_ 2015 GST_ALL_Byte5 0;
BA_REL_ "GenSigTimeoutTime" BU_SG_REL_ SHVU_RR SG_ 2015 GST_ALL_Byte5 0;
BA_REL_ "GenSigTimeoutTime" BU_SG_REL_ DPSU SG_ 2015 GST_ALL_Byte5 0;
BA_REL_ "GenSigTimeoutTime" BU_SG_REL_ DLBCU SG_ 2015 GST_ALL_Byte5 0;
BA_REL_ "GenSigTimeoutTime" BU_SG_REL_ PFSU SG_ 2015 GST_ALL_Byte5 0;
BA_REL_ "GenSigTimeoutTime" BU_SG_REL_ RCS SG_ 2015 GST_ALL_Byte5 0;
BA_REL_ "GenSigTimeoutTime" BU_SG_REL_ RRPSU SG_ 2015 GST_ALL_Byte5 0;
BA_REL_ "GenSigTimeoutTime" BU_SG_REL_ RLPSU SG_ 2015 GST_ALL_Byte5 0;
BA_REL_ "GenSigTimeoutTime" BU_SG_REL_ HOD SG_ 2015 GST_ALL_Byte5 0;
BA_REL_ "GenSigTimeoutTime" BU_SG_REL_ ATS SG_ 2015 GST_ALL_Byte5 0;
BA_REL_ "GenSigTimeoutTime" BU_SG_REL_ DSAU SG_ 2015 GST_ALL_Byte5 0;
BA_REL_ "GenSigTimeoutTime" BU_SG_REL_ ASAU SG_ 2015 GST_ALL_Byte5 0;
BA_REL_ "GenSigTimeoutTime" BU_SG_REL_ RCM SG_ 2015 GST_ALL_Byte5 0;
BA_REL_ "GenSigTimeoutTime" BU_SG_REL_ EMCU SG_ 2015 GST_ALL_Byte5 0;
BA_REL_ "GenSigTimeoutTime" BU_SG_REL_ SGU SG_ 2015 GST_ALL_Byte5 0;
BA_REL_ "GenSigTimeoutTime" BU_SG_REL_ ALBCU SG_ 2015 GST_ALL_Byte5 0;
BA_REL_ "GenSigTimeoutTime" BU_SG_REL_ WPC2 SG_ 2015 GST_ALL_Byte5 0;
BA_ "NetworkRequest" SG_ 2015 GST_ALL_Byte5 0;
BA_ "NetworkRequestHoldingTime" SG_ 2015 GST_ALL_Byte5 5000;
BA_ "Version" SG_ 2015 GST_ALL_Byte5 "21.02.04";
BA_ "Description" SG_ 2015 GST_ALL_Byte6 "TP Index : 0";
BA_ "UsrSigPurpose" SG_ 2015 GST_ALL_Byte6 0;
BA_ "UserSigValidity" SG_ 2015 GST_ALL_Byte6 0;
BA_REL_ "GenSigTimeoutTime" BU_SG_REL_ FCS SG_ 2015 GST_ALL_Byte6 0;
BA_REL_ "GenSigTimeoutTime" BU_SG_REL_ SCM SG_ 2015 GST_ALL_Byte6 0;
BA_REL_ "GenSigTimeoutTime" BU_SG_REL_ WPC SG_ 2015 GST_ALL_Byte6 0;
BA_REL_ "GenSigTimeoutTime" BU_SG_REL_ RWPC SG_ 2015 GST_ALL_Byte6 0;
BA_REL_ "GenSigTimeoutTime" BU_SG_REL_ PSB SG_ 2015 GST_ALL_Byte6 0;
BA_REL_ "GenSigTimeoutTime" BU_SG_REL_ SLB SG_ 2015 GST_ALL_Byte6 0;
BA_REL_ "GenSigTimeoutTime" BU_SG_REL_ ARS SG_ 2015 GST_ALL_Byte6 0;
BA_REL_ "GenSigTimeoutTime" BU_SG_REL_ SWRC SG_ 2015 GST_ALL_Byte6 0;
BA_REL_ "GenSigTimeoutTime" BU_SG_REL_ APSU SG_ 2015 GST_ALL_Byte6 0;
BA_REL_ "GenSigTimeoutTime" BU_SG_REL_ RLHV SG_ 2015 GST_ALL_Byte6 0;
BA_REL_ "GenSigTimeoutTime" BU_SG_REL_ RRHV SG_ 2015 GST_ALL_Byte6 0;
BA_REL_ "GenSigTimeoutTime" BU_SG_REL_ SHVU_FR SG_ 2015 GST_ALL_Byte6 0;
BA_REL_ "GenSigTimeoutTime" BU_SG_REL_ SHVU_RR SG_ 2015 GST_ALL_Byte6 0;
BA_REL_ "GenSigTimeoutTime" BU_SG_REL_ DPSU SG_ 2015 GST_ALL_Byte6 0;
BA_REL_ "GenSigTimeoutTime" BU_SG_REL_ DLBCU SG_ 2015 GST_ALL_Byte6 0;
BA_REL_ "GenSigTimeoutTime" BU_SG_REL_ PFSU SG_ 2015 GST_ALL_Byte6 0;
BA_REL_ "GenSigTimeoutTime" BU_SG_REL_ RCS SG_ 2015 GST_ALL_Byte6 0;
BA_REL_ "GenSigTimeoutTime" BU_SG_REL_ RRPSU SG_ 2015 GST_ALL_Byte6 0;
BA_REL_ "GenSigTimeoutTime" BU_SG_REL_ RLPSU SG_ 2015 GST_ALL_Byte6 0;
BA_REL_ "GenSigTimeoutTime" BU_SG_REL_ HOD SG_ 2015 GST_ALL_Byte6 0;
BA_REL_ "GenSigTimeoutTime" BU_SG_REL_ ATS SG_ 2015 GST_ALL_Byte6 0;
BA_REL_ "GenSigTimeoutTime" BU_SG_REL_ DSAU SG_ 2015 GST_ALL_Byte6 0;
BA_REL_ "GenSigTimeoutTime" BU_SG_REL_ ASAU SG_ 2015 GST_ALL_Byte6 0;
BA_REL_ "GenSigTimeoutTime" BU_SG_REL_ RCM SG_ 2015 GST_ALL_Byte6 0;
BA_REL_ "GenSigTimeoutTime" BU_SG_REL_ EMCU SG_ 2015 GST_ALL_Byte6 0;
BA_REL_ "GenSigTimeoutTime" BU_SG_REL_ SGU SG_ 2015 GST_ALL_Byte6 0;
BA_REL_ "GenSigTimeoutTime" BU_SG_REL_ ALBCU SG_ 2015 GST_ALL_Byte6 0;
BA_REL_ "GenSigTimeoutTime" BU_SG_REL_ WPC2 SG_ 2015 GST_ALL_Byte6 0;
BA_ "NetworkRequest" SG_ 2015 GST_ALL_Byte6 0;
BA_ "NetworkRequestHoldingTime" SG_ 2015 GST_ALL_Byte6 5000;
BA_ "Version" SG_ 2015 GST_ALL_Byte6 "21.02.04";
BA_ "Description" SG_ 2015 GST_ALL_Byte7 "TP Index : 0";
BA_ "UsrSigPurpose" SG_ 2015 GST_ALL_Byte7 0;
BA_ "UserSigValidity" SG_ 2015 GST_ALL_Byte7 0;
BA_REL_ "GenSigTimeoutTime" BU_SG_REL_ FCS SG_ 2015 GST_ALL_Byte7 0;
BA_REL_ "GenSigTimeoutTime" BU_SG_REL_ SCM SG_ 2015 GST_ALL_Byte7 0;
BA_REL_ "GenSigTimeoutTime" BU_SG_REL_ WPC SG_ 2015 GST_ALL_Byte7 0;
BA_REL_ "GenSigTimeoutTime" BU_SG_REL_ RWPC SG_ 2015 GST_ALL_Byte7 0;
BA_REL_ "GenSigTimeoutTime" BU_SG_REL_ PSB SG_ 2015 GST_ALL_Byte7 0;
BA_REL_ "GenSigTimeoutTime" BU_SG_REL_ SLB SG_ 2015 GST_ALL_Byte7 0;
BA_REL_ "GenSigTimeoutTime" BU_SG_REL_ ARS SG_ 2015 GST_ALL_Byte7 0;
BA_REL_ "GenSigTimeoutTime" BU_SG_REL_ SWRC SG_ 2015 GST_ALL_Byte7 0;
BA_REL_ "GenSigTimeoutTime" BU_SG_REL_ APSU SG_ 2015 GST_ALL_Byte7 0;
BA_REL_ "GenSigTimeoutTime" BU_SG_REL_ RLHV SG_ 2015 GST_ALL_Byte7 0;
BA_REL_ "GenSigTimeoutTime" BU_SG_REL_ RRHV SG_ 2015 GST_ALL_Byte7 0;
BA_REL_ "GenSigTimeoutTime" BU_SG_REL_ SHVU_FR SG_ 2015 GST_ALL_Byte7 0;
BA_REL_ "GenSigTimeoutTime" BU_SG_REL_ SHVU_RR SG_ 2015 GST_ALL_Byte7 0;
BA_REL_ "GenSigTimeoutTime" BU_SG_REL_ DPSU SG_ 2015 GST_ALL_Byte7 0;
BA_REL_ "GenSigTimeoutTime" BU_SG_REL_ DLBCU SG_ 2015 GST_ALL_Byte7 0;
BA_REL_ "GenSigTimeoutTime" BU_SG_REL_ PFSU SG_ 2015 GST_ALL_Byte7 0;
BA_REL_ "GenSigTimeoutTime" BU_SG_REL_ RCS SG_ 2015 GST_ALL_Byte7 0;
BA_REL_ "GenSigTimeoutTime" BU_SG_REL_ RRPSU SG_ 2015 GST_ALL_Byte7 0;
BA_REL_ "GenSigTimeoutTime" BU_SG_REL_ RLPSU SG_ 2015 GST_ALL_Byte7 0;
BA_REL_ "GenSigTimeoutTime" BU_SG_REL_ HOD SG_ 2015 GST_ALL_Byte7 0;
BA_REL_ "GenSigTimeoutTime" BU_SG_REL_ ATS SG_ 2015 GST_ALL_Byte7 0;
BA_REL_ "GenSigTimeoutTime" BU_SG_REL_ DSAU SG_ 2015 GST_ALL_Byte7 0;
BA_REL_ "GenSigTimeoutTime" BU_SG_REL_ ASAU SG_ 2015 GST_ALL_Byte7 0;
BA_REL_ "GenSigTimeoutTime" BU_SG_REL_ RCM SG_ 2015 GST_ALL_Byte7 0;
BA_REL_ "GenSigTimeoutTime" BU_SG_REL_ EMCU SG_ 2015 GST_ALL_Byte7 0;
BA_REL_ "GenSigTimeoutTime" BU_SG_REL_ SGU SG_ 2015 GST_ALL_Byte7 0;
BA_REL_ "GenSigTimeoutTime" BU_SG_REL_ ALBCU SG_ 2015 GST_ALL_Byte7 0;
BA_REL_ "GenSigTimeoutTime" BU_SG_REL_ WPC2 SG_ 2015 GST_ALL_Byte7 0;
BA_ "NetworkRequest" SG_ 2015 GST_ALL_Byte7 0;
BA_ "NetworkRequestHoldingTime" SG_ 2015 GST_ALL_Byte7 5000;
BA_ "Version" SG_ 2015 GST_ALL_Byte7 "21.02.04";
BA_ "Description" SG_ 2015 GST_ALL_Byte1 "TP Index : 0";
BA_ "UsrSigPurpose" SG_ 2015 GST_ALL_Byte1 0;
BA_ "UserSigValidity" SG_ 2015 GST_ALL_Byte1 0;
BA_REL_ "GenSigTimeoutTime" BU_SG_REL_ FCS SG_ 2015 GST_ALL_Byte1 0;
BA_REL_ "GenSigTimeoutTime" BU_SG_REL_ SCM SG_ 2015 GST_ALL_Byte1 0;
BA_REL_ "GenSigTimeoutTime" BU_SG_REL_ WPC SG_ 2015 GST_ALL_Byte1 0;
BA_REL_ "GenSigTimeoutTime" BU_SG_REL_ RWPC SG_ 2015 GST_ALL_Byte1 0;
BA_REL_ "GenSigTimeoutTime" BU_SG_REL_ PSB SG_ 2015 GST_ALL_Byte1 0;
BA_REL_ "GenSigTimeoutTime" BU_SG_REL_ SLB SG_ 2015 GST_ALL_Byte1 0;
BA_REL_ "GenSigTimeoutTime" BU_SG_REL_ ARS SG_ 2015 GST_ALL_Byte1 0;
BA_REL_ "GenSigTimeoutTime" BU_SG_REL_ SWRC SG_ 2015 GST_ALL_Byte1 0;
BA_REL_ "GenSigTimeoutTime" BU_SG_REL_ APSU SG_ 2015 GST_ALL_Byte1 0;
BA_REL_ "GenSigTimeoutTime" BU_SG_REL_ RLHV SG_ 2015 GST_ALL_Byte1 0;
BA_REL_ "GenSigTimeoutTime" BU_SG_REL_ RRHV SG_ 2015 GST_ALL_Byte1 0;
BA_REL_ "GenSigTimeoutTime" BU_SG_REL_ SHVU_FR SG_ 2015 GST_ALL_Byte1 0;
BA_REL_ "GenSigTimeoutTime" BU_SG_REL_ SHVU_RR SG_ 2015 GST_ALL_Byte1 0;
BA_REL_ "GenSigTimeoutTime" BU_SG_REL_ DPSU SG_ 2015 GST_ALL_Byte1 0;
BA_REL_ "GenSigTimeoutTime" BU_SG_REL_ DLBCU SG_ 2015 GST_ALL_Byte1 0;
BA_REL_ "GenSigTimeoutTime" BU_SG_REL_ PFSU SG_ 2015 GST_ALL_Byte1 0;
BA_REL_ "GenSigTimeoutTime" BU_SG_REL_ RCS SG_ 2015 GST_ALL_Byte1 0;
BA_REL_ "GenSigTimeoutTime" BU_SG_REL_ RRPSU SG_ 2015 GST_ALL_Byte1 0;
BA_REL_ "GenSigTimeoutTime" BU_SG_REL_ RLPSU SG_ 2015 GST_ALL_Byte1 0;
BA_REL_ "GenSigTimeoutTime" BU_SG_REL_ HOD SG_ 2015 GST_ALL_Byte1 0;
BA_REL_ "GenSigTimeoutTime" BU_SG_REL_ ATS SG_ 2015 GST_ALL_Byte1 0;
BA_REL_ "GenSigTimeoutTime" BU_SG_REL_ DSAU SG_ 2015 GST_ALL_Byte1 0;
BA_REL_ "GenSigTimeoutTime" BU_SG_REL_ ASAU SG_ 2015 GST_ALL_Byte1 0;
BA_REL_ "GenSigTimeoutTime" BU_SG_REL_ RCM SG_ 2015 GST_ALL_Byte1 0;
BA_REL_ "GenSigTimeoutTime" BU_SG_REL_ EMCU SG_ 2015 GST_ALL_Byte1 0;
BA_REL_ "GenSigTimeoutTime" BU_SG_REL_ SGU SG_ 2015 GST_ALL_Byte1 0;
BA_REL_ "GenSigTimeoutTime" BU_SG_REL_ ALBCU SG_ 2015 GST_ALL_Byte1 0;
BA_REL_ "GenSigTimeoutTime" BU_SG_REL_ WPC2 SG_ 2015 GST_ALL_Byte1 0;
BA_ "NetworkRequest" SG_ 2015 GST_ALL_Byte1 0;
BA_ "NetworkRequestHoldingTime" SG_ 2015 GST_ALL_Byte1 5000;
BA_ "Version" SG_ 2015 GST_ALL_Byte1 "21.02.04";
BA_ "GenMsgCycleTime" BO_ 1829 0;
BA_ "GenMsgCycleTimeFast" BO_ 1829 0;
BA_ "GenMsgNrOfRepetition" BO_ 1829 0;
BA_ "DiagRequest" BO_ 1829 1;
BA_ "GenMsgILSupport" BO_ 1829 0;
BA_ "TpMessage" BO_ 1829 1;
BA_ "TpTxIndex" BO_ 1829 180;
BA_ "Description" SG_ 1829 GST_WPC_Byte0 "TP Index : 180";
BA_ "UsrSigPurpose" SG_ 1829 GST_WPC_Byte0 3;
BA_ "UserSigValidity" SG_ 1829 GST_WPC_Byte0 0;
BA_REL_ "GenSigTimeoutTime" BU_SG_REL_ WPC SG_ 1829 GST_WPC_Byte0 0;
BA_ "NetworkRequest" SG_ 1829 GST_WPC_Byte0 0;
BA_ "NetworkRequestHoldingTime" SG_ 1829 GST_WPC_Byte0 5000;
BA_ "Version" SG_ 1829 GST_WPC_Byte0 "21.02.04";
BA_ "Description" SG_ 1829 GST_WPC_Byte2 "TP Index : 180";
BA_ "UsrSigPurpose" SG_ 1829 GST_WPC_Byte2 3;
BA_ "UserSigValidity" SG_ 1829 GST_WPC_Byte2 0;
BA_REL_ "GenSigTimeoutTime" BU_SG_REL_ WPC SG_ 1829 GST_WPC_Byte2 0;
BA_ "NetworkRequest" SG_ 1829 GST_WPC_Byte2 0;
BA_ "NetworkRequestHoldingTime" SG_ 1829 GST_WPC_Byte2 5000;
BA_ "Version" SG_ 1829 GST_WPC_Byte2 "21.02.04";
BA_ "Description" SG_ 1829 GST_WPC_Byte3 "TP Index : 180";
BA_ "UsrSigPurpose" SG_ 1829 GST_WPC_Byte3 3;
BA_ "UserSigValidity" SG_ 1829 GST_WPC_Byte3 0;
BA_REL_ "GenSigTimeoutTime" BU_SG_REL_ WPC SG_ 1829 GST_WPC_Byte3 0;
BA_ "NetworkRequest" SG_ 1829 GST_WPC_Byte3 0;
BA_ "NetworkRequestHoldingTime" SG_ 1829 GST_WPC_Byte3 5000;
BA_ "Version" SG_ 1829 GST_WPC_Byte3 "21.02.04";
BA_ "Description" SG_ 1829 GST_WPC_Byte4 "TP Index : 180";
BA_ "UsrSigPurpose" SG_ 1829 GST_WPC_Byte4 3;
BA_ "UserSigValidity" SG_ 1829 GST_WPC_Byte4 0;
BA_REL_ "GenSigTimeoutTime" BU_SG_REL_ WPC SG_ 1829 GST_WPC_Byte4 0;
BA_ "NetworkRequest" SG_ 1829 GST_WPC_Byte4 0;
BA_ "NetworkRequestHoldingTime" SG_ 1829 GST_WPC_Byte4 5000;
BA_ "Version" SG_ 1829 GST_WPC_Byte4 "21.02.04";
BA_ "Description" SG_ 1829 GST_WPC_Byte5 "TP Index : 180";
BA_ "UsrSigPurpose" SG_ 1829 GST_WPC_Byte5 3;
BA_ "UserSigValidity" SG_ 1829 GST_WPC_Byte5 0;
BA_REL_ "GenSigTimeoutTime" BU_SG_REL_ WPC SG_ 1829 GST_WPC_Byte5 0;
BA_ "NetworkRequest" SG_ 1829 GST_WPC_Byte5 0;
BA_ "NetworkRequestHoldingTime" SG_ 1829 GST_WPC_Byte5 5000;
BA_ "Version" SG_ 1829 GST_WPC_Byte5 "21.02.04";
BA_ "Description" SG_ 1829 GST_WPC_Byte6 "TP Index : 180";
BA_ "UsrSigPurpose" SG_ 1829 GST_WPC_Byte6 3;
BA_ "UserSigValidity" SG_ 1829 GST_WPC_Byte6 0;
BA_REL_ "GenSigTimeoutTime" BU_SG_REL_ WPC SG_ 1829 GST_WPC_Byte6 0;
BA_ "NetworkRequest" SG_ 1829 GST_WPC_Byte6 0;
BA_ "NetworkRequestHoldingTime" SG_ 1829 GST_WPC_Byte6 5000;
BA_ "Version" SG_ 1829 GST_WPC_Byte6 "21.02.04";
BA_ "Description" SG_ 1829 GST_WPC_Byte7 "TP Index : 180";
BA_ "UsrSigPurpose" SG_ 1829 GST_WPC_Byte7 3;
BA_ "UserSigValidity" SG_ 1829 GST_WPC_Byte7 0;
BA_REL_ "GenSigTimeoutTime" BU_SG_REL_ WPC SG_ 1829 GST_WPC_Byte7 0;
BA_ "NetworkRequest" SG_ 1829 GST_WPC_Byte7 0;
BA_ "NetworkRequestHoldingTime" SG_ 1829 GST_WPC_Byte7 5000;
BA_ "Version" SG_ 1829 GST_WPC_Byte7 "21.02.04";
BA_ "Description" SG_ 1829 GST_WPC_Byte1 "TP Index : 180";
BA_ "UsrSigPurpose" SG_ 1829 GST_WPC_Byte1 3;
BA_ "UserSigValidity" SG_ 1829 GST_WPC_Byte1 0;
BA_REL_ "GenSigTimeoutTime" BU_SG_REL_ WPC SG_ 1829 GST_WPC_Byte1 0;
BA_ "NetworkRequest" SG_ 1829 GST_WPC_Byte1 0;
BA_ "NetworkRequestHoldingTime" SG_ 1829 GST_WPC_Byte1 5000;
BA_ "Version" SG_ 1829 GST_WPC_Byte1 "21.02.04";
BA_ "GenMsgSendType" BO_ 2210462210 0;
BA_ "GenMsgCycleTime" BO_ 2210462210 50;
BA_ "GenMsgCycleTimeFast" BO_ 2210462210 0;
BA_ "GenMsgNrOfRepetition" BO_ 2210462210 0;
BA_ "VFrameFormat" BO_ 2210462210 1;
BA_ "Description" SG_ 2210462210 HCU_HevRdySta "Hybrid Vehicle Drivable ready";
BA_ "UserSigValidity" SG_ 2210462210 HCU_HevRdySta 3;
BA_ "RoutingFactor" SG_ 2210462210 HCU_HevRdySta 5;
BA_ "Version" SG_ 2210462210 HCU_HevRdySta "18.08.02";
BA_ "GenMsgSendType" BO_ 1240 0;
BA_ "Description" SG_ 1240 CF_AVN_ProfileIDRValue "18.08.22_This signal is only used in User Profile applied H/Unit";
BA_ "GenSigSendType" SG_ 1240 CF_AVN_ProfileIDRValue 4;
BA_ "GenSigStartValue" SG_ 1240 CF_AVN_ProfileIDRValue 15;
BA_ "UserSigValidity" SG_ 1240 CF_AVN_ProfileIDRValue 0;
BA_REL_ "GenSigTimeoutTime" BU_SG_REL_ WPC SG_ 1240 CF_AVN_ProfileIDRValue 1500;
BA_REL_ "GenSigTimeoutTime" BU_SG_REL_ RWPC SG_ 1240 CF_AVN_ProfileIDRValue 1500;
BA_REL_ "GenSigTimeoutTime" BU_SG_REL_ DPSU SG_ 1240 CF_AVN_ProfileIDRValue 1500;
BA_REL_ "GenSigTimeoutTime" BU_SG_REL_ DLBCU SG_ 1240 CF_AVN_ProfileIDRValue 1500;
BA_REL_ "GenSigTimeoutTime" BU_SG_REL_ RCM SG_ 1240 CF_AVN_ProfileIDRValue 1500;
BA_REL_ "GenSigTimeoutTime" BU_SG_REL_ BLTN_CAM SG_ 1240 CF_AVN_ProfileIDRValue 1500;
BA_REL_ "GenSigTimeoutTime" BU_SG_REL_ SGU SG_ 1240 CF_AVN_ProfileIDRValue 1500;
BA_REL_ "GenSigTimeoutTime" BU_SG_REL_ WPC2 SG_ 1240 CF_AVN_ProfileIDRValue 1500;
BA_ "Version" SG_ 1240 CF_AVN_ProfileIDRValue "18.09.04";
BA_ "GenMsgCycleTime" BO_ 1193 0;
BA_ "Description" SG_ 1193 CF_Gway_WPCNValueSet "18.08.09_";
BA_ "GenSigSendType" SG_ 1193 CF_Gway_WPCNValueSet 4;
BA_ "UserSigValidity" SG_ 1193 CF_Gway_WPCNValueSet 3;
BA_REL_ "GenSigTimeoutTime" BU_SG_REL_ WPC SG_ 1193 CF_Gway_WPCNValueSet 0;
BA_REL_ "GenSigTimeoutTime" BU_SG_REL_ WPC2 SG_ 1193 CF_Gway_WPCNValueSet 0;
BA_ "Version" SG_ 1193 CF_Gway_WPCNValueSet "18.09.04";
BA_ "GenMsgCycleTime" BO_ 1195 0;
BA_ "GenSigSendType" SG_ 1195 CF_AVN_CluUSMReset 4;
BA_ "UserSigValidity" SG_ 1195 CF_AVN_CluUSMReset 3;
BA_REL_ "GenSigTimeoutTime" BU_SG_REL_ WPC SG_ 1195 CF_AVN_CluUSMReset 0;
BA_REL_ "GenSigTimeoutTime" BU_SG_REL_ RWPC SG_ 1195 CF_AVN_CluUSMReset 0;
BA_REL_ "GenSigTimeoutTime" BU_SG_REL_ PSB SG_ 1195 CF_AVN_CluUSMReset 0;
BA_REL_ "GenSigTimeoutTime" BU_SG_REL_ SLB SG_ 1195 CF_AVN_CluUSMReset 0;
BA_REL_ "GenSigTimeoutTime" BU_SG_REL_ ARS SG_ 1195 CF_AVN_CluUSMReset 0;
BA_REL_ "GenSigTimeoutTime" BU_SG_REL_ APSU SG_ 1195 CF_AVN_CluUSMReset 0;
BA_REL_ "GenSigTimeoutTime" BU_SG_REL_ RLHV SG_ 1195 CF_AVN_CluUSMReset 0;
BA_REL_ "GenSigTimeoutTime" BU_SG_REL_ RRHV SG_ 1195 CF_AVN_CluUSMReset 0;
BA_REL_ "GenSigTimeoutTime" BU_SG_REL_ SHVU_FR SG_ 1195 CF_AVN_CluUSMReset 0;
BA_REL_ "GenSigTimeoutTime" BU_SG_REL_ SHVU_RR SG_ 1195 CF_AVN_CluUSMReset 0;
BA_REL_ "GenSigTimeoutTime" BU_SG_REL_ DPSU SG_ 1195 CF_AVN_CluUSMReset 0;
BA_REL_ "GenSigTimeoutTime" BU_SG_REL_ DLBCU SG_ 1195 CF_AVN_CluUSMReset 0;
BA_REL_ "GenSigTimeoutTime" BU_SG_REL_ PFSU SG_ 1195 CF_AVN_CluUSMReset 0;
BA_REL_ "GenSigTimeoutTime" BU_SG_REL_ RRPSU SG_ 1195 CF_AVN_CluUSMReset 0;
BA_REL_ "GenSigTimeoutTime" BU_SG_REL_ RLPSU SG_ 1195 CF_AVN_CluUSMReset 0;
BA_REL_ "GenSigTimeoutTime" BU_SG_REL_ ATS SG_ 1195 CF_AVN_CluUSMReset 0;
BA_REL_ "GenSigTimeoutTime" BU_SG_REL_ DSAU SG_ 1195 CF_AVN_CluUSMReset 0;
BA_REL_ "GenSigTimeoutTime" BU_SG_REL_ ASAU SG_ 1195 CF_AVN_CluUSMReset 0;
BA_REL_ "GenSigTimeoutTime" BU_SG_REL_ RCM SG_ 1195 CF_AVN_CluUSMReset 0;
BA_REL_ "GenSigTimeoutTime" BU_SG_REL_ BLTN_CAM SG_ 1195 CF_AVN_CluUSMReset 0;
BA_REL_ "GenSigTimeoutTime" BU_SG_REL_ ALBCU SG_ 1195 CF_AVN_CluUSMReset 0;
BA_REL_ "GenSigTimeoutTime" BU_SG_REL_ WPC2 SG_ 1195 CF_AVN_CluUSMReset 0;
BA_ "Version" SG_ 1195 CF_AVN_CluUSMReset "21.01.08";
BA_ "GenMsgSendType" BO_ 1076 0;
BA_ "GenSigSendType" SG_ 1076 IAU_ProfileIDRVal 4;
BA_ "UserSigValidity" SG_ 1076 IAU_ProfileIDRVal 0;
BA_REL_ "GenSigTimeoutTime" BU_SG_REL_ WPC SG_ 1076 IAU_ProfileIDRVal 1500;
BA_REL_ "GenSigTimeoutTime" BU_SG_REL_ RWPC SG_ 1076 IAU_ProfileIDRVal 1500;
BA_REL_ "GenSigTimeoutTime" BU_SG_REL_ DPSU SG_ 1076 IAU_ProfileIDRVal 1500;
BA_REL_ "GenSigTimeoutTime" BU_SG_REL_ DLBCU SG_ 1076 IAU_ProfileIDRVal 1500;
BA_REL_ "GenSigTimeoutTime" BU_SG_REL_ RCM SG_ 1076 IAU_ProfileIDRVal 1500;
BA_REL_ "GenSigTimeoutTime" BU_SG_REL_ BLTN_CAM SG_ 1076 IAU_ProfileIDRVal 1500;
BA_REL_ "GenSigTimeoutTime" BU_SG_REL_ SGU SG_ 1076 IAU_ProfileIDRVal 1500;
BA_REL_ "GenSigTimeoutTime" BU_SG_REL_ WPC2 SG_ 1076 IAU_ProfileIDRVal 1500;
BA_ "NetworkRequest" SG_ 1076 IAU_ProfileIDRVal 0;
BA_ "NetworkRequestHoldingTime" SG_ 1076 IAU_ProfileIDRVal 5000;
BA_ "Version" SG_ 1076 IAU_ProfileIDRVal "20.05.02";
BA_ "Description" SG_ 1076 IAU_DigitalKey2Opt "This signal describe Digital Key capability";
BA_ "GenSigSendType" SG_ 1076 IAU_DigitalKey2Opt 4;
BA_ "UserSigValidity" SG_ 1076 IAU_DigitalKey2Opt 0;
BA_REL_ "GenSigTimeoutTime" BU_SG_REL_ WPC SG_ 1076 IAU_DigitalKey2Opt 1500;
BA_REL_ "GenSigTimeoutTime" BU_SG_REL_ WPC2 SG_ 1076 IAU_DigitalKey2Opt 1500;
BA_ "NetworkRequest" SG_ 1076 IAU_DigitalKey2Opt 0;
BA_ "NetworkRequestHoldingTime" SG_ 1076 IAU_DigitalKey2Opt 5000;
BA_ "Version" SG_ 1076 IAU_DigitalKey2Opt "20.08.00";
BA_ "GenMsgSendType" BO_ 1041 0;
BA_ "GenSigSendType" SG_ 1041 Warn_DrvDrSwSta 4;
BA_ "UserSigValidity" SG_ 1041 Warn_DrvDrSwSta 0;
BA_REL_ "GenSigTimeoutTime" BU_SG_REL_ WPC SG_ 1041 Warn_DrvDrSwSta 1500;
BA_REL_ "GenSigTimeoutTime" BU_SG_REL_ RWPC SG_ 1041 Warn_DrvDrSwSta 1500;
BA_REL_ "GenSigTimeoutTime" BU_SG_REL_ DPSU SG_ 1041 Warn_DrvDrSwSta 1500;
BA_REL_ "GenSigTimeoutTime" BU_SG_REL_ BLTN_CAM SG_ 1041 Warn_DrvDrSwSta 1500;
BA_REL_ "GenSigTimeoutTime" BU_SG_REL_ WPC2 SG_ 1041 Warn_DrvDrSwSta 1500;
BA_ "NetworkRequest" SG_ 1041 Warn_DrvDrSwSta 0;
BA_ "NetworkRequestHoldingTime" SG_ 1041 Warn_DrvDrSwSta 5000;
BA_ "Version" SG_ 1041 Warn_DrvDrSwSta "17.12.00";
BA_ "GenSigSendType" SG_ 1041 Warn_AsstDrSwSta 4;
BA_ "UserSigValidity" SG_ 1041 Warn_AsstDrSwSta 0;
BA_REL_ "GenSigTimeoutTime" BU_SG_REL_ WPC SG_ 1041 Warn_AsstDrSwSta 1500;
BA_REL_ "GenSigTimeoutTime" BU_SG_REL_ RWPC SG_ 1041 Warn_AsstDrSwSta 1500;
BA_REL_ "GenSigTimeoutTime" BU_SG_REL_ APSU SG_ 1041 Warn_AsstDrSwSta 1500;
BA_REL_ "GenSigTimeoutTime" BU_SG_REL_ RLPSU SG_ 1041 Warn_AsstDrSwSta 1500;
BA_REL_ "GenSigTimeoutTime" BU_SG_REL_ BLTN_CAM SG_ 1041 Warn_AsstDrSwSta 1500;
BA_REL_ "GenSigTimeoutTime" BU_SG_REL_ ALBCU SG_ 1041 Warn_AsstDrSwSta 1500;
BA_REL_ "GenSigTimeoutTime" BU_SG_REL_ WPC2 SG_ 1041 Warn_AsstDrSwSta 1500;
BA_ "NetworkRequest" SG_ 1041 Warn_AsstDrSwSta 0;
BA_ "NetworkRequestHoldingTime" SG_ 1041 Warn_AsstDrSwSta 5000;
BA_ "Version" SG_ 1041 Warn_AsstDrSwSta "17.12.00";
BA_ "GenSigSendType" SG_ 1041 Warn_RrLftDrSwSta 4;
BA_ "UserSigValidity" SG_ 1041 Warn_RrLftDrSwSta 0;
BA_REL_ "GenSigTimeoutTime" BU_SG_REL_ WPC SG_ 1041 Warn_RrLftDrSwSta 1500;
BA_REL_ "GenSigTimeoutTime" BU_SG_REL_ RWPC SG_ 1041 Warn_RrLftDrSwSta 1500;
BA_REL_ "GenSigTimeoutTime" BU_SG_REL_ APSU SG_ 1041 Warn_RrLftDrSwSta 1500;
BA_REL_ "GenSigTimeoutTime" BU_SG_REL_ RLHV SG_ 1041 Warn_RrLftDrSwSta 1500;
BA_REL_ "GenSigTimeoutTime" BU_SG_REL_ RLPSU SG_ 1041 Warn_RrLftDrSwSta 1500;
BA_REL_ "GenSigTimeoutTime" BU_SG_REL_ BLTN_CAM SG_ 1041 Warn_RrLftDrSwSta 1500;
BA_REL_ "GenSigTimeoutTime" BU_SG_REL_ WPC2 SG_ 1041 Warn_RrLftDrSwSta 1500;
BA_ "NetworkRequest" SG_ 1041 Warn_RrLftDrSwSta 0;
BA_ "NetworkRequestHoldingTime" SG_ 1041 Warn_RrLftDrSwSta 5000;
BA_ "Version" SG_ 1041 Warn_RrLftDrSwSta "17.12.00";
BA_ "GenSigSendType" SG_ 1041 Warn_RrRtDrSwSta 4;
BA_ "UserSigValidity" SG_ 1041 Warn_RrRtDrSwSta 0;
BA_REL_ "GenSigTimeoutTime" BU_SG_REL_ WPC SG_ 1041 Warn_RrRtDrSwSta 1500;
BA_REL_ "GenSigTimeoutTime" BU_SG_REL_ RWPC SG_ 1041 Warn_RrRtDrSwSta 1500;
BA_REL_ "GenSigTimeoutTime" BU_SG_REL_ APSU SG_ 1041 Warn_RrRtDrSwSta 1500;
BA_REL_ "GenSigTimeoutTime" BU_SG_REL_ RRHV SG_ 1041 Warn_RrRtDrSwSta 1500;
BA_REL_ "GenSigTimeoutTime" BU_SG_REL_ RRPSU SG_ 1041 Warn_RrRtDrSwSta 1500;
BA_REL_ "GenSigTimeoutTime" BU_SG_REL_ RLPSU SG_ 1041 Warn_RrRtDrSwSta 1500;
BA_REL_ "GenSigTimeoutTime" BU_SG_REL_ BLTN_CAM SG_ 1041 Warn_RrRtDrSwSta 1500;
BA_REL_ "GenSigTimeoutTime" BU_SG_REL_ WPC2 SG_ 1041 Warn_RrRtDrSwSta 1500;
BA_ "NetworkRequest" SG_ 1041 Warn_RrRtDrSwSta 0;
BA_ "NetworkRequestHoldingTime" SG_ 1041 Warn_RrRtDrSwSta 5000;
BA_ "Version" SG_ 1041 Warn_RrRtDrSwSta "17.12.00";
BA_ "GenMsgSendType" BO_ 858 0;
BA_ "Description" SG_ 858 Warn_AsstDrSwSta_SBCM "Warning Assist Door Switch Status";
BA_ "GenSigSendType" SG_ 858 Warn_AsstDrSwSta_SBCM 4;
BA_ "UserSigValidity" SG_ 858 Warn_AsstDrSwSta_SBCM 0;
BA_REL_ "GenSigTimeoutTime" BU_SG_REL_ WPC SG_ 858 Warn_AsstDrSwSta_SBCM 1500;
BA_REL_ "GenSigTimeoutTime" BU_SG_REL_ RWPC SG_ 858 Warn_AsstDrSwSta_SBCM 1500;
BA_REL_ "GenSigTimeoutTime" BU_SG_REL_ APSU SG_ 858 Warn_AsstDrSwSta_SBCM 1500;
BA_REL_ "GenSigTimeoutTime" BU_SG_REL_ ATS SG_ 858 Warn_AsstDrSwSta_SBCM 1500;
BA_REL_ "GenSigTimeoutTime" BU_SG_REL_ BLTN_CAM SG_ 858 Warn_AsstDrSwSta_SBCM 1500;
BA_REL_ "GenSigTimeoutTime" BU_SG_REL_ ALBCU SG_ 858 Warn_AsstDrSwSta_SBCM 1500;
BA_REL_ "GenSigTimeoutTime" BU_SG_REL_ WPC2 SG_ 858 Warn_AsstDrSwSta_SBCM 1500;
BA_ "NetworkRequest" SG_ 858 Warn_AsstDrSwSta_SBCM 0;
BA_ "Version" SG_ 858 Warn_AsstDrSwSta_SBCM "21.07.07";
BA_ "GenMsgSendType" BO_ 799 0;
BA_ "Description" SG_ 799 Warn_DrvDrSwSta_SBCM "Warning Drive Door Switch State";
BA_ "GenSigSendType" SG_ 799 Warn_DrvDrSwSta_SBCM 4;
BA_ "UserSigValidity" SG_ 799 Warn_DrvDrSwSta_SBCM 0;
BA_REL_ "GenSigTimeoutTime" BU_SG_REL_ WPC SG_ 799 Warn_DrvDrSwSta_SBCM 1500;
BA_REL_ "GenSigTimeoutTime" BU_SG_REL_ RWPC SG_ 799 Warn_DrvDrSwSta_SBCM 1500;
BA_REL_ "GenSigTimeoutTime" BU_SG_REL_ DPSU SG_ 799 Warn_DrvDrSwSta_SBCM 1500;
BA_REL_ "GenSigTimeoutTime" BU_SG_REL_ ATS SG_ 799 Warn_DrvDrSwSta_SBCM 1500;
BA_REL_ "GenSigTimeoutTime" BU_SG_REL_ BLTN_CAM SG_ 799 Warn_DrvDrSwSta_SBCM 1500;
BA_REL_ "GenSigTimeoutTime" BU_SG_REL_ WPC2 SG_ 799 Warn_DrvDrSwSta_SBCM 1500;
BA_ "NetworkRequest" SG_ 799 Warn_DrvDrSwSta_SBCM 0;
BA_ "Version" SG_ 799 Warn_DrvDrSwSta_SBCM "21.07.07";
BA_ "GenMsgSendType" BO_ 862 0;
BA_ "Description" SG_ 862 Warn_RrLftDrSwSta_SBCM "Warning Rear Left Door Switch Status";
BA_ "GenSigSendType" SG_ 862 Warn_RrLftDrSwSta_SBCM 4;
BA_ "UserSigValidity" SG_ 862 Warn_RrLftDrSwSta_SBCM 0;
BA_REL_ "GenSigTimeoutTime" BU_SG_REL_ WPC SG_ 862 Warn_RrLftDrSwSta_SBCM 1500;
BA_REL_ "GenSigTimeoutTime" BU_SG_REL_ RWPC SG_ 862 Warn_RrLftDrSwSta_SBCM 1500;
BA_REL_ "GenSigTimeoutTime" BU_SG_REL_ APSU SG_ 862 Warn_RrLftDrSwSta_SBCM 1500;
BA_REL_ "GenSigTimeoutTime" BU_SG_REL_ ATS SG_ 862 Warn_RrLftDrSwSta_SBCM 1500;
BA_REL_ "GenSigTimeoutTime" BU_SG_REL_ BLTN_CAM SG_ 862 Warn_RrLftDrSwSta_SBCM 1500;
BA_REL_ "GenSigTimeoutTime" BU_SG_REL_ WPC2 SG_ 862 Warn_RrLftDrSwSta_SBCM 1500;
BA_ "NetworkRequest" SG_ 862 Warn_RrLftDrSwSta_SBCM 0;
BA_ "Version" SG_ 862 Warn_RrLftDrSwSta_SBCM "21.07.07";
BA_ "GenMsgSendType" BO_ 905 0;
BA_ "Description" SG_ 905 Warn_RrRtDrSwSta_SBCM "Warning Rear Right Door Switch Status";
BA_ "GenSigSendType" SG_ 905 Warn_RrRtDrSwSta_SBCM 4;
BA_ "UserSigValidity" SG_ 905 Warn_RrRtDrSwSta_SBCM 0;
BA_REL_ "GenSigTimeoutTime" BU_SG_REL_ WPC SG_ 905 Warn_RrRtDrSwSta_SBCM 1500;
BA_REL_ "GenSigTimeoutTime" BU_SG_REL_ RWPC SG_ 905 Warn_RrRtDrSwSta_SBCM 1500;
BA_REL_ "GenSigTimeoutTime" BU_SG_REL_ APSU SG_ 905 Warn_RrRtDrSwSta_SBCM 1500;
BA_REL_ "GenSigTimeoutTime" BU_SG_REL_ RRPSU SG_ 905 Warn_RrRtDrSwSta_SBCM 1500;
BA_REL_ "GenSigTimeoutTime" BU_SG_REL_ ATS SG_ 905 Warn_RrRtDrSwSta_SBCM 1500;
BA_REL_ "GenSigTimeoutTime" BU_SG_REL_ BLTN_CAM SG_ 905 Warn_RrRtDrSwSta_SBCM 1500;
BA_REL_ "GenSigTimeoutTime" BU_SG_REL_ WPC2 SG_ 905 Warn_RrRtDrSwSta_SBCM 1500;
BA_ "NetworkRequest" SG_ 905 Warn_RrRtDrSwSta_SBCM 0;
BA_ "Version" SG_ 905 Warn_RrRtDrSwSta_SBCM "21.07.07";
BA_ "GenMsgSendType" BO_ 1093 0;
BA_ "Description" SG_ 1093 LFAnt_SrchSta "SMK LF Searching Status



This signal indicates that SMK operates LF searching for finding FOB.

WPC uses this signal for suspending wirless charging.";
BA_ "GenSigSendType" SG_ 1093 LFAnt_SrchSta 4;
BA_ "UserSigValidity" SG_ 1093 LFAnt_SrchSta 0;
BA_REL_ "GenSigTimeoutTime" BU_SG_REL_ WPC SG_ 1093 LFAnt_SrchSta 1500;
BA_REL_ "GenSigTimeoutTime" BU_SG_REL_ RWPC SG_ 1093 LFAnt_SrchSta 1500;
BA_REL_ "GenSigTimeoutTime" BU_SG_REL_ WPC2 SG_ 1093 LFAnt_SrchSta 1500;
BA_ "Version" SG_ 1093 LFAnt_SrchSta "17.12.00";
BA_ "GenMsgSendType" BO_ 2160080129 0;
BA_ "GenMsgCycleTime" BO_ 2160080129 50;
BA_ "GenMsgCycleTimeFast" BO_ 2160080129 0;
BA_ "GenMsgNrOfRepetition" BO_ 2160080129 0;
BA_ "VFrameFormat" BO_ 2160080129 1;
BA_ "Description" SG_ 2160080129 VCU_EvDrvRdySta "EV Ready";
BA_ "UserSigValidity" SG_ 2160080129 VCU_EvDrvRdySta 7;
BA_ "RoutingFactor" SG_ 2160080129 VCU_EvDrvRdySta 5;
BA_ "Version" SG_ 2160080129 VCU_EvDrvRdySta "20.04.05";
BA_ "GenMsgSendType" BO_ 1099 0;
BA_ "Description" SG_ 1099 USM_CmdWPCSta "USM request value of WPC";
BA_ "GenSigSendType" SG_ 1099 USM_CmdWPCSta 4;
BA_ "UserSigValidity" SG_ 1099 USM_CmdWPCSta 0;
BA_REL_ "GenSigTimeoutTime" BU_SG_REL_ CGW_CCU SG_ 1099 USM_CmdWPCSta 1500;
BA_ "NetworkRequest" SG_ 1099 USM_CmdWPCSta 0;
BA_ "NetworkRequestHoldingTime" SG_ 1099 USM_CmdWPCSta 5000;
BA_ "Version" SG_ 1099 USM_CmdWPCSta "17.11.00";
BA_ "Description" SG_ 1099 WPC_SWVerMajor1 "Indicate the WPC software version as follows:

- The software version is displayed in three digits.

- The Major and Minor digits are separated by '.'

- Signal values are transmitted to ASCII codes.



『 Example

WPC_SWVerMajor1 : 0x41 (HEX) -> ASCII CODE : 'A' 

WPC_SWVerMinor1 : 0x30 (HEX) -> ASCII CODE : '0'

WPC_SWVerMinor2 : 0x33 (HEX) -> ASCII CODE : '3'

=> WPC S/W Ver is displayed 'A.03'";
BA_ "GenSigSendType" SG_ 1099 WPC_SWVerMajor1 4;
BA_ "UserSigValidity" SG_ 1099 WPC_SWVerMajor1 0;
BA_REL_ "GenSigTimeoutTime" BU_SG_REL_ CGW_CCU SG_ 1099 WPC_SWVerMajor1 1500;
BA_ "Version" SG_ 1099 WPC_SWVerMajor1 "20.12.04";
BA_ "Description" SG_ 1099 WPC_PhnLftWrngSta "Warning by WPC for User (Phone left in vehicle)";
BA_ "GenSigSendType" SG_ 1099 WPC_PhnLftWrngSta 4;
BA_ "UserSigValidity" SG_ 1099 WPC_PhnLftWrngSta 0;
BA_REL_ "GenSigTimeoutTime" BU_SG_REL_ CGW_CCU SG_ 1099 WPC_PhnLftWrngSta 1500;
BA_ "NetworkRequest" SG_ 1099 WPC_PhnLftWrngSta 0;
BA_ "NetworkRequestHoldingTime" SG_ 1099 WPC_PhnLftWrngSta 5000;
BA_ "Version" SG_ 1099 WPC_PhnLftWrngSta "18.02.03";
BA_ "Description" SG_ 1099 WPC_SWVerMinor1 "Indicate the WPC software version as follows:

- The software version is displayed in three digits.

- The Major and Minor digits are separated by '.'

- Signal values are transmitted to ASCII codes.



『 Example

WPC_SWVerMajor1 : 0x41 (HEX) -> ASCII CODE : 'A' 

WPC_SWVerMinor1 : 0x30 (HEX) -> ASCII CODE : '0'

WPC_SWVerMinor2 : 0x33 (HEX) -> ASCII CODE : '3'

=> WPC S/W Ver is displayed 'A.03'";
BA_ "GenSigSendType" SG_ 1099 WPC_SWVerMinor1 4;
BA_ "UserSigValidity" SG_ 1099 WPC_SWVerMinor1 0;
BA_REL_ "GenSigTimeoutTime" BU_SG_REL_ CGW_CCU SG_ 1099 WPC_SWVerMinor1 1500;
BA_ "Version" SG_ 1099 WPC_SWVerMinor1 "18.10.06";
BA_ "Description" SG_ 1099 WPC_SWVerMinor2 "Indicate the WPC software version as follows:

- The software version is displayed in three digits.

- The Major and Minor digits are separated by '.'

- Signal values are transmitted to ASCII codes.



『 Example

WPC_SWVerMajor1 : 0x41 (HEX) -> ASCII CODE : 'A' 

WPC_SWVerMinor1 : 0x30 (HEX) -> ASCII CODE : '0'

WPC_SWVerMinor2 : 0x33 (HEX) -> ASCII CODE : '3'

=> WPC S/W Ver is displayed 'A.03'";
BA_ "GenSigSendType" SG_ 1099 WPC_SWVerMinor2 4;
BA_ "UserSigValidity" SG_ 1099 WPC_SWVerMinor2 0;
BA_REL_ "GenSigTimeoutTime" BU_SG_REL_ CGW_CCU SG_ 1099 WPC_SWVerMinor2 1500;
BA_ "Version" SG_ 1099 WPC_SWVerMinor2 "18.10.06";
BA_ "GenMsgCycleTime" BO_ 1837 0;
BA_ "GenMsgCycleTimeFast" BO_ 1837 0;
BA_ "GenMsgNrOfRepetition" BO_ 1837 0;
BA_ "DiagResponse" BO_ 1837 1;
BA_ "GenMsgILSupport" BO_ 1837 0;
BA_ "TpMessage" BO_ 1837 1;
BA_ "TpTxIndex" BO_ 1837 180;
BA_ "Description" SG_ 1837 WPC_GST_Byte0 "TP Index : 180";
BA_ "UsrSigPurpose" SG_ 1837 WPC_GST_Byte0 4;
BA_ "UserSigValidity" SG_ 1837 WPC_GST_Byte0 0;
BA_REL_ "GenSigTimeoutTime" BU_SG_REL_ CGW_CCU SG_ 1837 WPC_GST_Byte0 0;
BA_ "NetworkRequest" SG_ 1837 WPC_GST_Byte0 0;
BA_ "NetworkRequestHoldingTime" SG_ 1837 WPC_GST_Byte0 5000;
BA_ "Version" SG_ 1837 WPC_GST_Byte0 "21.02.04";
BA_ "Description" SG_ 1837 WPC_GST_Byte2 "TP Index : 180";
BA_ "UsrSigPurpose" SG_ 1837 WPC_GST_Byte2 4;
BA_ "UserSigValidity" SG_ 1837 WPC_GST_Byte2 0;
BA_REL_ "GenSigTimeoutTime" BU_SG_REL_ CGW_CCU SG_ 1837 WPC_GST_Byte2 0;
BA_ "NetworkRequest" SG_ 1837 WPC_GST_Byte2 0;
BA_ "NetworkRequestHoldingTime" SG_ 1837 WPC_GST_Byte2 5000;
BA_ "Version" SG_ 1837 WPC_GST_Byte2 "21.02.04";
BA_ "Description" SG_ 1837 WPC_GST_Byte3 "TP Index : 180";
BA_ "UsrSigPurpose" SG_ 1837 WPC_GST_Byte3 4;
BA_ "UserSigValidity" SG_ 1837 WPC_GST_Byte3 0;
BA_REL_ "GenSigTimeoutTime" BU_SG_REL_ CGW_CCU SG_ 1837 WPC_GST_Byte3 0;
BA_ "NetworkRequest" SG_ 1837 WPC_GST_Byte3 0;
BA_ "NetworkRequestHoldingTime" SG_ 1837 WPC_GST_Byte3 5000;
BA_ "Version" SG_ 1837 WPC_GST_Byte3 "21.02.04";
BA_ "Description" SG_ 1837 WPC_GST_Byte4 "TP Index : 180";
BA_ "UsrSigPurpose" SG_ 1837 WPC_GST_Byte4 4;
BA_ "UserSigValidity" SG_ 1837 WPC_GST_Byte4 0;
BA_REL_ "GenSigTimeoutTime" BU_SG_REL_ CGW_CCU SG_ 1837 WPC_GST_Byte4 0;
BA_ "NetworkRequest" SG_ 1837 WPC_GST_Byte4 0;
BA_ "NetworkRequestHoldingTime" SG_ 1837 WPC_GST_Byte4 5000;
BA_ "Version" SG_ 1837 WPC_GST_Byte4 "21.02.04";
BA_ "Description" SG_ 1837 WPC_GST_Byte5 "TP Index : 180";
BA_ "UsrSigPurpose" SG_ 1837 WPC_GST_Byte5 4;
BA_ "UserSigValidity" SG_ 1837 WPC_GST_Byte5 0;
BA_REL_ "GenSigTimeoutTime" BU_SG_REL_ CGW_CCU SG_ 1837 WPC_GST_Byte5 0;
BA_ "NetworkRequest" SG_ 1837 WPC_GST_Byte5 0;
BA_ "NetworkRequestHoldingTime" SG_ 1837 WPC_GST_Byte5 5000;
BA_ "Version" SG_ 1837 WPC_GST_Byte5 "21.02.04";
BA_ "Description" SG_ 1837 WPC_GST_Byte6 "TP Index : 180";
BA_ "UsrSigPurpose" SG_ 1837 WPC_GST_Byte6 4;
BA_ "UserSigValidity" SG_ 1837 WPC_GST_Byte6 0;
BA_REL_ "GenSigTimeoutTime" BU_SG_REL_ CGW_CCU SG_ 1837 WPC_GST_Byte6 0;
BA_ "NetworkRequest" SG_ 1837 WPC_GST_Byte6 0;
BA_ "NetworkRequestHoldingTime" SG_ 1837 WPC_GST_Byte6 5000;
BA_ "Version" SG_ 1837 WPC_GST_Byte6 "21.02.04";
BA_ "Description" SG_ 1837 WPC_GST_Byte7 "TP Index : 180";
BA_ "UsrSigPurpose" SG_ 1837 WPC_GST_Byte7 4;
BA_ "UserSigValidity" SG_ 1837 WPC_GST_Byte7 0;
BA_REL_ "GenSigTimeoutTime" BU_SG_REL_ CGW_CCU SG_ 1837 WPC_GST_Byte7 0;
BA_ "NetworkRequest" SG_ 1837 WPC_GST_Byte7 0;
BA_ "NetworkRequestHoldingTime" SG_ 1837 WPC_GST_Byte7 5000;
BA_ "Version" SG_ 1837 WPC_GST_Byte7 "21.02.04";
BA_ "Description" SG_ 1837 WPC_GST_Byte1 "TP Index : 180";
BA_ "UsrSigPurpose" SG_ 1837 WPC_GST_Byte1 4;
BA_ "UserSigValidity" SG_ 1837 WPC_GST_Byte1 0;
BA_REL_ "GenSigTimeoutTime" BU_SG_REL_ CGW_CCU SG_ 1837 WPC_GST_Byte1 0;
BA_ "NetworkRequest" SG_ 1837 WPC_GST_Byte1 0;
BA_ "NetworkRequestHoldingTime" SG_ 1837 WPC_GST_Byte1 5000;
BA_ "Version" SG_ 1837 WPC_GST_Byte1 "21.02.04";
BA_ "NmMessage" BO_ 1301 1;
BA_ "GenMsgILSupport" BO_ 1301 0;
BA_ "NWM-Botschaft" BO_ 1301 1;
BA_ "UsrSigPurpose" SG_ 1301 Destination_WPC2 9;
BA_ "UserSigValidity" SG_ 1301 Destination_WPC2 0;
BA_ "UsrSigPurpose" SG_ 1301 NMCommandCode_WPC2 9;
BA_ "UserSigValidity" SG_ 1301 NMCommandCode_WPC2 0;
BA_ "UsrSigPurpose" SG_ 1301 NMSleepFlag_WPC2 9;
BA_ "UserSigValidity" SG_ 1301 NMSleepFlag_WPC2 0;
BA_ "NmMessage" BO_ 1308 1;
BA_ "GenMsgILSupport" BO_ 1308 0;
BA_ "NWM-Botschaft" BO_ 1308 1;
BA_ "UsrSigPurpose" SG_ 1308 Destination_RLPSU 9;
BA_ "UserSigValidity" SG_ 1308 Destination_RLPSU 0;
BA_ "UsrSigPurpose" SG_ 1308 NMCommandCode_RLPSU 9;
BA_ "UserSigValidity" SG_ 1308 NMCommandCode_RLPSU 0;
BA_ "UsrSigPurpose" SG_ 1308 NMSleepFlag_RLPSU 9;
BA_ "UserSigValidity" SG_ 1308 NMSleepFlag_RLPSU 0;
BA_ "NmMessage" BO_ 1336 1;
BA_ "GenMsgILSupport" BO_ 1336 0;
BA_ "NWM-Botschaft" BO_ 1336 1;
BA_ "UsrSigPurpose" SG_ 1336 Destination_DPSU 9;
BA_ "UserSigValidity" SG_ 1336 Destination_DPSU 0;
BA_ "UsrSigPurpose" SG_ 1336 NMCommandCode_DPSU 9;
BA_ "UserSigValidity" SG_ 1336 NMCommandCode_DPSU 0;
BA_ "UsrSigPurpose" SG_ 1336 NMSleepFlag_DPSU 9;
BA_ "UserSigValidity" SG_ 1336 NMSleepFlag_DPSU 0;
BA_ "NmMessage" BO_ 1345 1;
BA_ "GenMsgILSupport" BO_ 1345 0;
BA_ "NWM-Botschaft" BO_ 1345 1;
BA_ "UsrSigPurpose" SG_ 1345 Destination_PSB 9;
BA_ "UserSigValidity" SG_ 1345 Destination_PSB 0;
BA_ "UsrSigPurpose" SG_ 1345 NMCommandCode_PSB 9;
BA_ "UserSigValidity" SG_ 1345 NMCommandCode_PSB 0;
BA_ "UsrSigPurpose" SG_ 1345 NMSleepFlag_PSB 9;
BA_ "UserSigValidity" SG_ 1345 NMSleepFlag_PSB 0;
BA_ "NmMessage" BO_ 1323 1;
BA_ "GenMsgILSupport" BO_ 1323 0;
BA_ "NWM-Botschaft" BO_ 1323 1;
BA_ "UsrSigPurpose" SG_ 1323 Destination_SHVU_RR 9;
BA_ "UserSigValidity" SG_ 1323 Destination_SHVU_RR 0;
BA_ "UsrSigPurpose" SG_ 1323 NMCommandCode_SHVU_RR 9;
BA_ "UserSigValidity" SG_ 1323 NMCommandCode_SHVU_RR 0;
BA_ "UsrSigPurpose" SG_ 1323 NMSleepFlag_SHVU_RR 9;
BA_ "UserSigValidity" SG_ 1323 NMSleepFlag_SHVU_RR 0;
BA_ "NmMessage" BO_ 1329 1;
BA_ "GenMsgILSupport" BO_ 1329 0;
BA_ "NWM-Botschaft" BO_ 1329 1;
BA_ "UsrSigPurpose" SG_ 1329 Destination_APSU 9;
BA_ "UserSigValidity" SG_ 1329 Destination_APSU 0;
BA_ "UsrSigPurpose" SG_ 1329 NMCommandCode_APSU 9;
BA_ "UserSigValidity" SG_ 1329 NMCommandCode_APSU 0;
BA_ "UsrSigPurpose" SG_ 1329 NMSleepFlag_APSU 9;
BA_ "UserSigValidity" SG_ 1329 NMSleepFlag_APSU 0;
BA_ "NmMessage" BO_ 1313 1;
BA_ "GenMsgILSupport" BO_ 1313 0;
BA_ "NWM-Botschaft" BO_ 1313 1;
BA_ "UsrSigPurpose" SG_ 1313 Destination_FCS 9;
BA_ "UserSigValidity" SG_ 1313 Destination_FCS 0;
BA_ "UsrSigPurpose" SG_ 1313 NMCommandCode_FCS 9;
BA_ "UserSigValidity" SG_ 1313 NMCommandCode_FCS 0;
BA_ "UsrSigPurpose" SG_ 1313 NMSleepFlag_FCS 9;
BA_ "UserSigValidity" SG_ 1313 NMSleepFlag_FCS 0;
BA_ "NmMessage" BO_ 1297 1;
BA_ "GenMsgILSupport" BO_ 1297 0;
BA_ "NWM-Botschaft" BO_ 1297 1;
BA_ "UsrSigPurpose" SG_ 1297 Destination_EMCU 9;
BA_ "UserSigValidity" SG_ 1297 Destination_EMCU 0;
BA_ "UsrSigPurpose" SG_ 1297 NMCommandCode_EMCU 9;
BA_ "UserSigValidity" SG_ 1297 NMCommandCode_EMCU 0;
BA_ "UsrSigPurpose" SG_ 1297 NMSleepFlag_EMCU 9;
BA_ "UserSigValidity" SG_ 1297 NMSleepFlag_EMCU 0;
BA_ "NmMessage" BO_ 1307 1;
BA_ "GenMsgILSupport" BO_ 1307 0;
BA_ "NWM-Botschaft" BO_ 1307 1;
BA_ "UsrSigPurpose" SG_ 1307 Destination_SLB 9;
BA_ "UserSigValidity" SG_ 1307 Destination_SLB 0;
BA_ "UsrSigPurpose" SG_ 1307 NMCommandCode_SLB 9;
BA_ "UserSigValidity" SG_ 1307 NMCommandCode_SLB 0;
BA_ "UsrSigPurpose" SG_ 1307 NMSleepFlag_SLB 9;
BA_ "UserSigValidity" SG_ 1307 NMSleepFlag_SLB 0;
BA_ "NmMessage" BO_ 1290 1;
BA_ "GenMsgILSupport" BO_ 1290 0;
BA_ "NWM-Botschaft" BO_ 1290 1;
BA_ "UsrSigPurpose" SG_ 1290 Destination_ARS 9;
BA_ "UserSigValidity" SG_ 1290 Destination_ARS 0;
BA_ "UsrSigPurpose" SG_ 1290 NMCommandCode_ARS 9;
BA_ "UserSigValidity" SG_ 1290 NMCommandCode_ARS 0;
BA_ "UsrSigPurpose" SG_ 1290 NMSleepFlag_ARS 9;
BA_ "UserSigValidity" SG_ 1290 NMSleepFlag_ARS 0;
BA_ "NmMessage" BO_ 1341 1;
BA_ "GenMsgILSupport" BO_ 1341 0;
BA_ "NWM-Botschaft" BO_ 1341 1;
BA_ "UsrSigPurpose" SG_ 1341 Destination_RCM 9;
BA_ "UserSigValidity" SG_ 1341 Destination_RCM 0;
BA_ "UsrSigPurpose" SG_ 1341 NMCommandCode_RCM 9;
BA_ "UserSigValidity" SG_ 1341 NMCommandCode_RCM 0;
BA_ "UsrSigPurpose" SG_ 1341 NMSleepFlag_RCM 9;
BA_ "UserSigValidity" SG_ 1341 NMSleepFlag_RCM 0;
BA_ "NmMessage" BO_ 1392 1;
BA_ "GenMsgILSupport" BO_ 1392 0;
BA_ "NWM-Botschaft" BO_ 1392 1;
BA_ "UsrSigPurpose" SG_ 1392 Destination_CGW_CCU 9;
BA_ "UserSigValidity" SG_ 1392 Destination_CGW_CCU 0;
BA_ "UsrSigPurpose" SG_ 1392 NMCommandCode_CGW_CCU 9;
BA_ "UserSigValidity" SG_ 1392 NMCommandCode_CGW_CCU 0;
BA_ "UsrSigPurpose" SG_ 1392 NMSleepFlag_CGW_CCU 9;
BA_ "UserSigValidity" SG_ 1392 NMSleepFlag_CGW_CCU 0;
BA_ "NmMessage" BO_ 1360 1;
BA_ "GenMsgILSupport" BO_ 1360 0;
BA_ "NWM-Botschaft" BO_ 1360 1;
BA_ "UsrSigPurpose" SG_ 1360 Destination_ATS 9;
BA_ "UserSigValidity" SG_ 1360 Destination_ATS 0;
BA_ "UsrSigPurpose" SG_ 1360 NMCommandCode_ATS 9;
BA_ "UserSigValidity" SG_ 1360 NMCommandCode_ATS 0;
BA_ "UsrSigPurpose" SG_ 1360 NMSleepFlag_ATS 9;
BA_ "UserSigValidity" SG_ 1360 NMSleepFlag_ATS 0;
BA_ "NmMessage" BO_ 1332 1;
BA_ "GenMsgILSupport" BO_ 1332 0;
BA_ "NWM-Botschaft" BO_ 1332 1;
BA_ "UsrSigPurpose" SG_ 1332 Destination_RLHV 9;
BA_ "UserSigValidity" SG_ 1332 Destination_RLHV 0;
BA_ "UsrSigPurpose" SG_ 1332 NMCommandCode_RLHV 9;
BA_ "UserSigValidity" SG_ 1332 NMCommandCode_RLHV 0;
BA_ "UsrSigPurpose" SG_ 1332 NMSleepFlag_RLHV 9;
BA_ "UserSigValidity" SG_ 1332 NMSleepFlag_RLHV 0;
BA_ "NmMessage" BO_ 1342 1;
BA_ "GenMsgILSupport" BO_ 1342 0;
BA_ "NWM-Botschaft" BO_ 1342 1;
BA_ "UsrSigPurpose" SG_ 1342 Destination_SGU 9;
BA_ "UserSigValidity" SG_ 1342 Destination_SGU 0;
BA_ "UsrSigPurpose" SG_ 1342 NMCommandCode_SGU 9;
BA_ "UserSigValidity" SG_ 1342 NMCommandCode_SGU 0;
BA_ "UsrSigPurpose" SG_ 1342 NMSleepFlag_SGU 9;
BA_ "UserSigValidity" SG_ 1342 NMSleepFlag_SGU 0;
BA_ "NmMessage" BO_ 1325 1;
BA_ "GenMsgILSupport" BO_ 1325 0;
BA_ "NWM-Botschaft" BO_ 1325 1;
BA_ "UsrSigPurpose" SG_ 1325 Destination_PFSU 9;
BA_ "UserSigValidity" SG_ 1325 Destination_PFSU 0;
BA_ "UsrSigPurpose" SG_ 1325 NMCommandCode_PFSU 9;
BA_ "UserSigValidity" SG_ 1325 NMCommandCode_PFSU 0;
BA_ "UsrSigPurpose" SG_ 1325 NMSleepFlag_PFSU 9;
BA_ "UserSigValidity" SG_ 1325 NMSleepFlag_PFSU 0;
BA_ "NmMessage" BO_ 1348 1;
BA_ "GenMsgILSupport" BO_ 1348 0;
BA_ "NWM-Botschaft" BO_ 1348 1;
BA_ "UsrSigPurpose" SG_ 1348 Destination_ALBCU 9;
BA_ "UserSigValidity" SG_ 1348 Destination_ALBCU 0;
BA_ "UsrSigPurpose" SG_ 1348 NMCommandCode_ALBCU 9;
BA_ "UserSigValidity" SG_ 1348 NMCommandCode_ALBCU 0;
BA_ "UsrSigPurpose" SG_ 1348 NMSleepFlag_ALBCU 9;
BA_ "UserSigValidity" SG_ 1348 NMSleepFlag_ALBCU 0;
BA_ "NmMessage" BO_ 1369 1;
BA_ "GenMsgILSupport" BO_ 1369 0;
BA_ "NWM-Botschaft" BO_ 1369 1;
BA_ "UsrSigPurpose" SG_ 1369 Destination_DSAU 9;
BA_ "UserSigValidity" SG_ 1369 Destination_DSAU 0;
BA_ "UsrSigPurpose" SG_ 1369 NMCommandCode_DSAU 9;
BA_ "UserSigValidity" SG_ 1369 NMCommandCode_DSAU 0;
BA_ "UsrSigPurpose" SG_ 1369 NMSleepFlag_DSAU 9;
BA_ "UserSigValidity" SG_ 1369 NMSleepFlag_DSAU 0;
BA_ "NmMessage" BO_ 1288 1;
BA_ "GenMsgILSupport" BO_ 1288 0;
BA_ "NWM-Botschaft" BO_ 1288 1;
BA_ "UsrSigPurpose" SG_ 1288 Destination_SWRC 9;
BA_ "UserSigValidity" SG_ 1288 Destination_SWRC 0;
BA_ "UsrSigPurpose" SG_ 1288 NMCommandCode_SWRC 9;
BA_ "UserSigValidity" SG_ 1288 NMCommandCode_SWRC 0;
BA_ "UsrSigPurpose" SG_ 1288 NMSleepFlag_SWRC 9;
BA_ "UserSigValidity" SG_ 1288 NMSleepFlag_SWRC 0;
BA_ "NmMessage" BO_ 1322 1;
BA_ "GenMsgILSupport" BO_ 1322 0;
BA_ "NWM-Botschaft" BO_ 1322 1;
BA_ "UsrSigPurpose" SG_ 1322 Destination_SHVU_FR 9;
BA_ "UserSigValidity" SG_ 1322 Destination_SHVU_FR 0;
BA_ "UsrSigPurpose" SG_ 1322 NMCommandCode_SHVU_FR 9;
BA_ "UserSigValidity" SG_ 1322 NMCommandCode_SHVU_FR 0;
BA_ "UsrSigPurpose" SG_ 1322 NMSleepFlag_SHVU_FR 9;
BA_ "UserSigValidity" SG_ 1322 NMSleepFlag_SHVU_FR 0;
BA_ "NmMessage" BO_ 1350 1;
BA_ "GenMsgILSupport" BO_ 1350 0;
BA_ "NWM-Botschaft" BO_ 1350 1;
BA_ "UsrSigPurpose" SG_ 1350 Destination_RCS 9;
BA_ "UserSigValidity" SG_ 1350 Destination_RCS 0;
BA_ "UsrSigPurpose" SG_ 1350 NMCommandCode_RCS 9;
BA_ "UserSigValidity" SG_ 1350 NMCommandCode_RCS 0;
BA_ "UsrSigPurpose" SG_ 1350 NMSleepFlag_RCS 9;
BA_ "UserSigValidity" SG_ 1350 NMSleepFlag_RCS 0;
BA_ "NmMessage" BO_ 1309 1;
BA_ "GenMsgILSupport" BO_ 1309 0;
BA_ "NWM-Botschaft" BO_ 1309 1;
BA_ "UsrSigPurpose" SG_ 1309 Destination_RRPSU 9;
BA_ "UserSigValidity" SG_ 1309 Destination_RRPSU 0;
BA_ "UsrSigPurpose" SG_ 1309 NMCommandCode_RRPSU 9;
BA_ "UserSigValidity" SG_ 1309 NMCommandCode_RRPSU 0;
BA_ "UsrSigPurpose" SG_ 1309 NMSleepFlag_RRPSU 9;
BA_ "UserSigValidity" SG_ 1309 NMSleepFlag_RRPSU 0;
BA_ "NmMessage" BO_ 1352 1;
BA_ "GenMsgILSupport" BO_ 1352 0;
BA_ "NWM-Botschaft" BO_ 1352 1;
BA_ "UsrSigPurpose" SG_ 1352 Destination_BLTN_CAM 9;
BA_ "UserSigValidity" SG_ 1352 Destination_BLTN_CAM 0;
BA_ "UsrSigPurpose" SG_ 1352 NMCommandCode_BLTN_CAM 9;
BA_ "UserSigValidity" SG_ 1352 NMCommandCode_BLTN_CAM 0;
BA_ "UsrSigPurpose" SG_ 1352 NMSleepFlag_BLTN_CAM 9;
BA_ "UserSigValidity" SG_ 1352 NMSleepFlag_BLTN_CAM 0;
BA_ "NmMessage" BO_ 1287 1;
BA_ "GenMsgILSupport" BO_ 1287 0;
BA_ "NWM-Botschaft" BO_ 1287 1;
BA_ "UsrSigPurpose" SG_ 1287 Destination_SCM 9;
BA_ "UserSigValidity" SG_ 1287 Destination_SCM 0;
BA_ "UsrSigPurpose" SG_ 1287 NMCommandCode_SCM 9;
BA_ "UserSigValidity" SG_ 1287 NMCommandCode_SCM 0;
BA_ "UsrSigPurpose" SG_ 1287 NMSleepFlag_SCM 9;
BA_ "UserSigValidity" SG_ 1287 NMSleepFlag_SCM 0;
BA_ "NmMessage" BO_ 1344 1;
BA_ "GenMsgILSupport" BO_ 1344 0;
BA_ "NWM-Botschaft" BO_ 1344 1;
BA_ "UsrSigPurpose" SG_ 1344 Destination_DLBCU 9;
BA_ "UserSigValidity" SG_ 1344 Destination_DLBCU 0;
BA_ "UsrSigPurpose" SG_ 1344 NMCommandCode_DLBCU 9;
BA_ "UserSigValidity" SG_ 1344 NMCommandCode_DLBCU 0;
BA_ "UsrSigPurpose" SG_ 1344 NMSleepFlag_DLBCU 9;
BA_ "UserSigValidity" SG_ 1344 NMSleepFlag_DLBCU 0;
BA_ "NmMessage" BO_ 1364 1;
BA_ "GenMsgILSupport" BO_ 1364 0;
BA_ "NWM-Botschaft" BO_ 1364 1;
BA_ "UsrSigPurpose" SG_ 1364 Destination_OHCL 9;
BA_ "UserSigValidity" SG_ 1364 Destination_OHCL 0;
BA_ "UsrSigPurpose" SG_ 1364 NMCommandCode_OHCL 9;
BA_ "UserSigValidity" SG_ 1364 NMCommandCode_OHCL 0;
BA_ "UsrSigPurpose" SG_ 1364 NMSleepFlag_OHCL 9;
BA_ "UserSigValidity" SG_ 1364 NMSleepFlag_OHCL 0;
BA_ "NmMessage" BO_ 1311 1;
BA_ "GenMsgILSupport" BO_ 1311 0;
BA_ "NWM-Botschaft" BO_ 1311 1;
BA_ "UsrSigPurpose" SG_ 1311 Destination_RWPC 9;
BA_ "UserSigValidity" SG_ 1311 Destination_RWPC 0;
BA_ "UsrSigPurpose" SG_ 1311 NMCommandCode_RWPC 9;
BA_ "UserSigValidity" SG_ 1311 NMCommandCode_RWPC 0;
BA_ "UsrSigPurpose" SG_ 1311 NMSleepFlag_RWPC 9;
BA_ "UserSigValidity" SG_ 1311 NMSleepFlag_RWPC 0;
BA_ "NmMessage" BO_ 1333 1;
BA_ "GenMsgILSupport" BO_ 1333 0;
BA_ "NWM-Botschaft" BO_ 1333 1;
BA_ "UsrSigPurpose" SG_ 1333 Destination_RRHV 9;
BA_ "UserSigValidity" SG_ 1333 Destination_RRHV 0;
BA_ "UsrSigPurpose" SG_ 1333 NMCommandCode_RRHV 9;
BA_ "UserSigValidity" SG_ 1333 NMCommandCode_RRHV 0;
BA_ "UsrSigPurpose" SG_ 1333 NMSleepFlag_RRHV 9;
BA_ "UserSigValidity" SG_ 1333 NMSleepFlag_RRHV 0;
BA_ "NmMessage" BO_ 1310 1;
BA_ "GenMsgILSupport" BO_ 1310 0;
BA_ "NWM-Botschaft" BO_ 1310 1;
BA_ "UsrSigPurpose" SG_ 1310 Destination_WPC 9;
BA_ "UserSigValidity" SG_ 1310 Destination_WPC 0;
BA_ "UsrSigPurpose" SG_ 1310 NMCommandCode_WPC 9;
BA_ "UserSigValidity" SG_ 1310 NMCommandCode_WPC 0;
BA_ "UsrSigPurpose" SG_ 1310 NMSleepFlag_WPC 9;
BA_ "UserSigValidity" SG_ 1310 NMSleepFlag_WPC 0;
BA_ "NmMessage" BO_ 1354 1;
BA_ "GenMsgILSupport" BO_ 1354 0;
BA_ "NWM-Botschaft" BO_ 1354 1;
BA_ "UsrSigPurpose" SG_ 1354 Destination_HOD 9;
BA_ "UserSigValidity" SG_ 1354 Destination_HOD 0;
BA_ "UsrSigPurpose" SG_ 1354 NMCommandCode_HOD 9;
BA_ "UserSigValidity" SG_ 1354 NMCommandCode_HOD 0;
BA_ "UsrSigPurpose" SG_ 1354 NMSleepFlag_HOD 9;
BA_ "UserSigValidity" SG_ 1354 NMSleepFlag_HOD 0;
BA_ "NmMessage" BO_ 1363 1;
BA_ "GenMsgILSupport" BO_ 1363 0;
BA_ "NWM-Botschaft" BO_ 1363 1;
BA_ "UsrSigPurpose" SG_ 1363 Destination_ASAU 9;
BA_ "UserSigValidity" SG_ 1363 Destination_ASAU 0;
BA_ "UsrSigPurpose" SG_ 1363 NMCommandCode_ASAU 9;
BA_ "UserSigValidity" SG_ 1363 NMCommandCode_ASAU 0;
BA_ "UsrSigPurpose" SG_ 1363 NMSleepFlag_ASAU 9;
BA_ "UserSigValidity" SG_ 1363 NMSleepFlag_ASAU 0;
VAL_ 1050 Lamp_IntTailLmpOnReq 0 "Off" 1 "On" 2 "Not Used" 3 "Error Indicator" ;
VAL_ 1090 BCM_SmkOptTyp 0 "Non SMK Option" 1 "SMK Option" 2 "Not Used" 3 "Error Indicator" ;
VAL_ 2256644609 CLU_DtntOutSta 0 "Detent Off" 1 "Detent On" 2 "Not used" 3 "Error Indicator" ;
VAL_ 2256644609 CLU_RhstaLvlSta 0 "Reserved" 1 "Step 1" 2 "Step 2" 3 "Step 3" 4 "Step 4" 5 "Step 5" 6 "Step 6" 7 "Step 7" 8 "Step 8" 9 "Step 9" 10 "Step 10" 11 "Step 11" 12 "Step 12" 13 "Step 13" 14 "Step 14" 15 "Step 15" 16 "Step 16" 17 "Step 17" 18 "Step 18" 19 "Step 19" 20 "Step 20 (Reset Value)" 21 "Step 21 (Detent)" ;
VAL_ 2256644610 CLU_DisSpdVal_KPH 511 "Error" ;
VAL_ 2256644610 CLU_AutoBrightSta 0 "Reserved (Not Used)" 1 "0x01~0xC8:Bright State (1~200 Step)" 200 "0x01~0xC8:Bright State (1~200 Step)" ;
VAL_ 2470760705 USM_StaRst1Req 0 "Defualt" 1 "Reset" 2 "Not used" 3 "Error Indicator" ;
VAL_ 2470763009 USM_WpcSetReq 0 "Default" 1 "Off(Disable)" 2 "On(Enable)" 3 "Invalid" ;
VAL_ 2353206529 CLU_ClusterUSM 0 "Default" 1 "Cluster not applied USM" 2 "Cluster applied USM" 3 "Reserved" ;
VAL_ 2214658049 ENG_EngSta 0 "Engine Stop" 1 "Cranking" 2 "Stalled" 3 "Running" 4 "Reserved" 5 "Reserved" 6 "Reserved" 7 "Fault" ;
VAL_ 2214659330 HEV_EngOpSta 0 "ES(Engine Stop)" 1 "ST(Start)" 2 "IS(Idle speed)" 3 "PL(Part Load)" 4 "PU(Pull)" 5 "PUC(Fuel Cut off)" ;
VAL_ 2210462210 HCU_HevRdySta 0 "HEV not ready" 1 "HEV Drivable" 2 "Not used" 3 "Error Indicator" ;
VAL_ 1240 CF_AVN_ProfileIDRValue 0 "Default" 1 "Guest" 2 "Profile 1" 3 "Profile 2" 4 "reserved" 5 "reserved" 6 "reserved" 7 "reserved" 8 "reserved" 9 "reserved" 10 "reserved" 11 "reserved" 12 "reserved" 13 "reserved" 14 "reserved" 15 "Invalid" ;
VAL_ 1193 CF_Gway_WPCNValueSet 0 "Default" 1 "Off(Disable)" 2 "On(Enable)" 3 "Invalid" ;
VAL_ 1195 CF_AVN_CluUSMReset 0 "Default" 1 "USM Reset" 2 "Reserved" 3 "Invalid" ;
VAL_ 1076 IAU_ProfileIDRVal 0 "Default" 1 "Guest" 2 "Profile1" 3 "Profile2" 4 "Reserved" 5 "Reserved" 6 "Reserved" 7 "Reserved" 8 "Reserved" 9 "Reserved" 10 "Reserved" 11 "Reserved" 12 "Reserved" 13 "Reserved" 14 "Reserved" 15 "Invalid" ;
VAL_ 1076 IAU_DigitalKey2Opt 0 "Default (Not applied)" 1 "Digital Key Light (NFC)" 2 "Digital Key Medium (NFC/BLE)" 3 "Digital Key Full (NFC/BLE/UWB)" 4 "Reserved" 5 "Reserved" 6 "Reserved" 7 "invalid" ;
VAL_ 1041 Warn_DrvDrSwSta 0 "Close" 1 "Open" 2 "Not Used" 3 "Error Indicator" ;
VAL_ 1041 Warn_AsstDrSwSta 0 "Close" 1 "Open" 2 "Not Used" 3 "Error Indicator" ;
VAL_ 1041 Warn_RrLftDrSwSta 0 "Close" 1 "Open" 2 "Not Used" 3 "Error Indicator" ;
VAL_ 1041 Warn_RrRtDrSwSta 0 "Close" 1 "Open" 2 "Not Used" 3 "Error Indicator" ;
VAL_ 858 Warn_AsstDrSwSta_SBCM 0 "Close" 1 "Open" 2 "RESERVED" 3 "Error Indicator" ;
VAL_ 799 Warn_DrvDrSwSta_SBCM 0 "Close" 1 "Open" 2 "RESERVED" 3 "Error Indicator" ;
VAL_ 862 Warn_RrLftDrSwSta_SBCM 0 "Close" 1 "Open" 2 "RESERVED" 3 "Error Indicator" ;
VAL_ 905 Warn_RrRtDrSwSta_SBCM 0 "Close" 1 "Open" 2 "RESERVED" 3 "Error Indicator" ;
VAL_ 1093 LFAnt_SrchSta 0 "Off" 1 "On (LF Searching)" 2 "Not Used" 3 "Error Indicator" ;
VAL_ 2160080129 VCU_EvDrvRdySta 0 "None" 1 "EV Drivable" 2 "Not used" 3 "Error Indicator" ;
VAL_ 1099 USM_CmdWPCSta 0 "Default" 1 "Off(Disable)" 2 "On(Enable)" 3 "Invalid" ;
VAL_ 1099 WPC_SWVerMajor1 0 "0x0x0~0x7F:ASCII Code Value (HEX)" 127 "0x0x0~0x7F:ASCII Code Value (HEX)" ;
VAL_ 1099 WPC_PhnLftWrngSta 0 "Off" 1 "Cellphone on the pad" 2 "Charging" 3 "Charging complete" 4 "Cellphone reminder" 5 "Error" 6 "Reserved" 7 "Invalid" ;
VAL_ 1099 WPC_SWVerMinor1 0 "0x0x0~0x7F:ASCII Code Value (HEX)" 127 "0x0x0~0x7F:ASCII Code Value (HEX)" ;
VAL_ 1099 WPC_SWVerMinor2 0 "0x0x0~0x7F:ASCII Code Value (HEX)" 127 "0x0x0~0x7F:ASCII Code Value (HEX)" ;
VAL_ 1301 Destination_WPC2 0 "0x0x0~0xFF:NM Source Node ID" 255 "0x0x0~0xFF:NM Source Node ID" ;
VAL_ 1301 NMCommandCode_WPC2 1 "Alive" 2 "Ring" 3 "RESERVED" 4 "Limphome" 5 "0x5~0xFF:RESERVED" 255 "0x5~0xFF:RESERVED" ;
VAL_ 1301 NMSleepFlag_WPC2 0 "Alive" 1 "SleepInd" 2 "RESERVED" 3 "SleepAck" ;
VAL_ 1308 Destination_RLPSU 0 "0x0x0~0xFF:NM Source Node ID" 255 "0x0x0~0xFF:NM Source Node ID" ;
VAL_ 1308 NMCommandCode_RLPSU 1 "Alive" 2 "Ring" 3 "RESERVED" 4 "Limphome" 5 "0x5~0xFF:RESERVED" 255 "0x5~0xFF:RESERVED" ;
VAL_ 1308 NMSleepFlag_RLPSU 0 "Alive" 1 "SleepInd" 2 "RESERVED" 3 "SleepAck" ;
VAL_ 1336 Destination_DPSU 0 "0x0x0~0xFF:NM Source Node ID" 255 "0x0x0~0xFF:NM Source Node ID" ;
VAL_ 1336 NMCommandCode_DPSU 1 "Alive" 2 "Ring" 3 "RESERVED" 4 "Limphome" 5 "0x5~0xFF:RESERVED" 255 "0x5~0xFF:RESERVED" ;
VAL_ 1336 NMSleepFlag_DPSU 0 "Alive" 1 "SleepInd" 2 "RESERVED" 3 "SleepAck" ;
VAL_ 1345 Destination_PSB 0 "0x0x0~0xFF:NM Source Node ID" 255 "0x0x0~0xFF:NM Source Node ID" ;
VAL_ 1345 NMCommandCode_PSB 1 "Alive" 2 "Ring" 3 "RESERVED" 4 "Limphome" 5 "0x5~0xFF:RESERVED" 255 "0x5~0xFF:RESERVED" ;
VAL_ 1345 NMSleepFlag_PSB 0 "Alive" 1 "SleepInd" 2 "RESERVED" 3 "SleepAck" ;
VAL_ 1323 Destination_SHVU_RR 0 "0x0x0~0xFF:NM Source Node ID" 255 "0x0x0~0xFF:NM Source Node ID" ;
VAL_ 1323 NMCommandCode_SHVU_RR 1 "Alive" 2 "Ring" 3 "RESERVED" 4 "Limphome" 5 "0x5~0xFF:RESERVED" 255 "0x5~0xFF:RESERVED" ;
VAL_ 1323 NMSleepFlag_SHVU_RR 0 "Alive" 1 "SleepInd" 2 "RESERVED" 3 "SleepAck" ;
VAL_ 1329 Destination_APSU 0 "0x0x0~0xFF:NM Source Node ID" 255 "0x0x0~0xFF:NM Source Node ID" ;
VAL_ 1329 NMCommandCode_APSU 1 "Alive" 2 "Ring" 3 "RESERVED" 4 "Limphome" 5 "0x5~0xFF:RESERVED" 255 "0x5~0xFF:RESERVED" ;
VAL_ 1329 NMSleepFlag_APSU 0 "Alive" 1 "SleepInd" 2 "RESERVED" 3 "SleepAck" ;
VAL_ 1313 Destination_FCS 0 "0x0x0~0xFF:NM Source Node ID" 255 "0x0x0~0xFF:NM Source Node ID" ;
VAL_ 1313 NMCommandCode_FCS 1 "Alive" 2 "Ring" 3 "RESERVED" 4 "Limphome" 5 "0x5~0xFF:RESERVED" 255 "0x5~0xFF:RESERVED" ;
VAL_ 1313 NMSleepFlag_FCS 0 "Alive" 1 "SleepInd" 2 "RESERVED" 3 "SleepAck" ;
VAL_ 1297 Destination_EMCU 0 "0x0x0~0xFF:NM Source Node ID" 255 "0x0x0~0xFF:NM Source Node ID" ;
VAL_ 1297 NMCommandCode_EMCU 1 "Alive" 2 "Ring" 3 "RESERVED" 4 "Limphome" 5 "0x5~0xFF:RESERVED" 255 "0x5~0xFF:RESERVED" ;
VAL_ 1297 NMSleepFlag_EMCU 0 "Alive" 1 "SleepInd" 2 "RESERVED" 3 "SleepAck" ;
VAL_ 1307 Destination_SLB 0 "0x0x0~0xFF:NM Source Node ID" 255 "0x0x0~0xFF:NM Source Node ID" ;
VAL_ 1307 NMCommandCode_SLB 1 "Alive" 2 "Ring" 3 "RESERVED" 4 "Limphome" 5 "0x5~0xFF:RESERVED" 255 "0x5~0xFF:RESERVED" ;
VAL_ 1307 NMSleepFlag_SLB 0 "Alive" 1 "SleepInd" 2 "RESERVED" 3 "SleepAck" ;
VAL_ 1290 Destination_ARS 0 "0x0x0~0xFF:NM Source Node ID" 255 "0x0x0~0xFF:NM Source Node ID" ;
VAL_ 1290 NMCommandCode_ARS 1 "Alive" 2 "Ring" 3 "RESERVED" 4 "Limphome" 5 "0x5~0xFF:RESERVED" 255 "0x5~0xFF:RESERVED" ;
VAL_ 1290 NMSleepFlag_ARS 0 "Alive" 1 "SleepInd" 2 "RESERVED" 3 "SleepAck" ;
VAL_ 1341 Destination_RCM 0 "0x0x0~0xFF:NM Source Node ID" 255 "0x0x0~0xFF:NM Source Node ID" ;
VAL_ 1341 NMCommandCode_RCM 1 "Alive" 2 "Ring" 3 "RESERVED" 4 "Limphome" 5 "0x5~0xFF:RESERVED" 255 "0x5~0xFF:RESERVED" ;
VAL_ 1341 NMSleepFlag_RCM 0 "Alive" 1 "SleepInd" 2 "RESERVED" 3 "SleepAck" ;
VAL_ 1392 Destination_CGW_CCU 0 "0x0x0~0xFF:NM Source Node ID" 255 "0x0x0~0xFF:NM Source Node ID" ;
VAL_ 1392 NMCommandCode_CGW_CCU 1 "Alive" 2 "Ring" 3 "RESERVED" 4 "Limphome" 5 "0x5~0xFF:RESERVED" 255 "0x5~0xFF:RESERVED" ;
VAL_ 1392 NMSleepFlag_CGW_CCU 0 "Alive" 1 "SleepInd" 2 "RESERVED" 3 "SleepAck" ;
VAL_ 1360 Destination_ATS 0 "0x0x0~0xFF:NM Source Node ID" 255 "0x0x0~0xFF:NM Source Node ID" ;
VAL_ 1360 NMCommandCode_ATS 1 "Alive" 2 "Ring" 3 "RESERVED" 4 "Limphome" 5 "0x5~0xFF:RESERVED" 255 "0x5~0xFF:RESERVED" ;
VAL_ 1360 NMSleepFlag_ATS 0 "Alive" 1 "SleepInd" 2 "RESERVED" 3 "SleepAck" ;
VAL_ 1332 Destination_RLHV 0 "0x0x0~0xFF:NM Source Node ID" 255 "0x0x0~0xFF:NM Source Node ID" ;
VAL_ 1332 NMCommandCode_RLHV 1 "Alive" 2 "Ring" 3 "RESERVED" 4 "Limphome" 5 "0x5~0xFF:RESERVED" 255 "0x5~0xFF:RESERVED" ;
VAL_ 1332 NMSleepFlag_RLHV 0 "Alive" 1 "SleepInd" 2 "RESERVED" 3 "SleepAck" ;
VAL_ 1342 Destination_SGU 0 "0x0x0~0xFF:NM Source Node ID" 255 "0x0x0~0xFF:NM Source Node ID" ;
VAL_ 1342 NMCommandCode_SGU 1 "Alive" 2 "Ring" 3 "RESERVED" 4 "Limphome" 5 "0x5~0xFF:RESERVED" 255 "0x5~0xFF:RESERVED" ;
VAL_ 1342 NMSleepFlag_SGU 0 "Alive" 1 "SleepInd" 2 "RESERVED" 3 "SleepAck" ;
VAL_ 1325 Destination_PFSU 0 "0x0x0~0xFF:NM Source Node ID" 255 "0x0x0~0xFF:NM Source Node ID" ;
VAL_ 1325 NMCommandCode_PFSU 1 "Alive" 2 "Ring" 3 "RESERVED" 4 "Limphome" 5 "0x5~0xFF:RESERVED" 255 "0x5~0xFF:RESERVED" ;
VAL_ 1325 NMSleepFlag_PFSU 0 "Alive" 1 "SleepInd" 2 "RESERVED" 3 "SleepAck" ;
VAL_ 1348 Destination_ALBCU 0 "0x0x0~0xFF:NM Source Node ID" 255 "0x0x0~0xFF:NM Source Node ID" ;
VAL_ 1348 NMCommandCode_ALBCU 1 "Alive" 2 "Ring" 3 "RESERVED" 4 "Limphome" 5 "0x5~0xFF:RESERVED" 255 "0x5~0xFF:RESERVED" ;
VAL_ 1348 NMSleepFlag_ALBCU 0 "Alive" 1 "SleepInd" 2 "RESERVED" 3 "SleepAck" ;
VAL_ 1369 Destination_DSAU 0 "0x0x0~0xFF:NM Source Node ID" 255 "0x0x0~0xFF:NM Source Node ID" ;
VAL_ 1369 NMCommandCode_DSAU 1 "Alive" 2 "Ring" 3 "RESERVED" 4 "Limphome" 5 "0x5~0xFF:RESERVED" 255 "0x5~0xFF:RESERVED" ;
VAL_ 1369 NMSleepFlag_DSAU 0 "Alive" 1 "SleepInd" 2 "RESERVED" 3 "SleepAck" ;
VAL_ 1288 Destination_SWRC 0 "0x0x0~0xFF:NM Source Node ID" 255 "0x0x0~0xFF:NM Source Node ID" ;
VAL_ 1288 NMCommandCode_SWRC 1 "Alive" 2 "Ring" 3 "RESERVED" 4 "Limphome" 5 "0x5~0xFF:RESERVED" 255 "0x5~0xFF:RESERVED" ;
VAL_ 1288 NMSleepFlag_SWRC 0 "Alive" 1 "SleepInd" 2 "RESERVED" 3 "SleepAck" ;
VAL_ 1322 Destination_SHVU_FR 0 "0x0x0~0xFF:NM Source Node ID" 255 "0x0x0~0xFF:NM Source Node ID" ;
VAL_ 1322 NMCommandCode_SHVU_FR 1 "Alive" 2 "Ring" 3 "RESERVED" 4 "Limphome" 5 "0x5~0xFF:RESERVED" 255 "0x5~0xFF:RESERVED" ;
VAL_ 1322 NMSleepFlag_SHVU_FR 0 "Alive" 1 "SleepInd" 2 "RESERVED" 3 "SleepAck" ;
VAL_ 1350 Destination_RCS 0 "0x0x0~0xFF:NM Source Node ID" 255 "0x0x0~0xFF:NM Source Node ID" ;
VAL_ 1350 NMCommandCode_RCS 1 "Alive" 2 "Ring" 3 "RESERVED" 4 "Limphome" 5 "0x5~0xFF:RESERVED" 255 "0x5~0xFF:RESERVED" ;
VAL_ 1350 NMSleepFlag_RCS 0 "Alive" 1 "SleepInd" 2 "RESERVED" 3 "SleepAck" ;
VAL_ 1309 Destination_RRPSU 0 "0x0x0~0xFF:NM Source Node ID" 255 "0x0x0~0xFF:NM Source Node ID" ;
VAL_ 1309 NMCommandCode_RRPSU 1 "Alive" 2 "Ring" 3 "RESERVED" 4 "Limphome" 5 "0x5~0xFF:RESERVED" 255 "0x5~0xFF:RESERVED" ;
VAL_ 1309 NMSleepFlag_RRPSU 0 "Alive" 1 "SleepInd" 2 "RESERVED" 3 "SleepAck" ;
VAL_ 1352 Destination_BLTN_CAM 0 "0x0x0~0xFF:NM Source Node ID" 255 "0x0x0~0xFF:NM Source Node ID" ;
VAL_ 1352 NMCommandCode_BLTN_CAM 1 "Alive" 2 "Ring" 3 "RESERVED" 4 "Limphome" 5 "0x5~0xFF:RESERVED" 255 "0x5~0xFF:RESERVED" ;
VAL_ 1352 NMSleepFlag_BLTN_CAM 0 "Alive" 1 "SleepInd" 2 "RESERVED" 3 "SleepAck" ;
VAL_ 1287 Destination_SCM 0 "0x0x0~0xFF:NM Source Node ID" 255 "0x0x0~0xFF:NM Source Node ID" ;
VAL_ 1287 NMCommandCode_SCM 1 "Alive" 2 "Ring" 3 "RESERVED" 4 "Limphome" 5 "0x5~0xFF:RESERVED" 255 "0x5~0xFF:RESERVED" ;
VAL_ 1287 NMSleepFlag_SCM 0 "Alive" 1 "SleepInd" 2 "RESERVED" 3 "SleepAck" ;
VAL_ 1344 Destination_DLBCU 0 "0x0x0~0xFF:NM Source Node ID" 255 "0x0x0~0xFF:NM Source Node ID" ;
VAL_ 1344 NMCommandCode_DLBCU 1 "Alive" 2 "Ring" 3 "RESERVED" 4 "Limphome" 5 "0x5~0xFF:RESERVED" 255 "0x5~0xFF:RESERVED" ;
VAL_ 1344 NMSleepFlag_DLBCU 0 "Alive" 1 "SleepInd" 2 "RESERVED" 3 "SleepAck" ;
VAL_ 1364 Destination_OHCL 0 "0x0x0~0xFF:NM Source Node ID" 255 "0x0x0~0xFF:NM Source Node ID" ;
VAL_ 1364 NMCommandCode_OHCL 1 "Alive" 2 "Ring" 3 "RESERVED" 4 "Limphome" 5 "0x5~0xFF:RESERVED" 255 "0x5~0xFF:RESERVED" ;
VAL_ 1364 NMSleepFlag_OHCL 0 "Alive" 1 "SleepInd" 2 "RESERVED" 3 "SleepAck" ;
VAL_ 1311 Destination_RWPC 0 "0x0x0~0xFF:NM Source Node ID" 255 "0x0x0~0xFF:NM Source Node ID" ;
VAL_ 1311 NMCommandCode_RWPC 1 "Alive" 2 "Ring" 3 "RESERVED" 4 "Limphome" 5 "0x5~0xFF:RESERVED" 255 "0x5~0xFF:RESERVED" ;
VAL_ 1311 NMSleepFlag_RWPC 0 "Alive" 1 "SleepInd" 2 "RESERVED" 3 "SleepAck" ;
VAL_ 1333 Destination_RRHV 0 "0x0x0~0xFF:NM Source Node ID" 255 "0x0x0~0xFF:NM Source Node ID" ;
VAL_ 1333 NMCommandCode_RRHV 1 "Alive" 2 "Ring" 3 "RESERVED" 4 "Limphome" 5 "0x5~0xFF:RESERVED" 255 "0x5~0xFF:RESERVED" ;
VAL_ 1333 NMSleepFlag_RRHV 0 "Alive" 1 "SleepInd" 2 "RESERVED" 3 "SleepAck" ;
VAL_ 1310 Destination_WPC 0 "0x0x0~0xFF:NM Source Node ID" 255 "0x0x0~0xFF:NM Source Node ID" ;
VAL_ 1310 NMCommandCode_WPC 1 "Alive" 2 "Ring" 3 "RESERVED" 4 "Limphome" 5 "0x5~0xFF:RESERVED" 255 "0x5~0xFF:RESERVED" ;
VAL_ 1310 NMSleepFlag_WPC 0 "Alive" 1 "SleepInd" 2 "RESERVED" 3 "SleepAck" ;
VAL_ 1354 Destination_HOD 0 "0x0x0~0xFF:NM Source Node ID" 255 "0x0x0~0xFF:NM Source Node ID" ;
VAL_ 1354 NMCommandCode_HOD 1 "Alive" 2 "Ring" 3 "RESERVED" 4 "Limphome" 5 "0x5~0xFF:RESERVED" 255 "0x5~0xFF:RESERVED" ;
VAL_ 1354 NMSleepFlag_HOD 0 "Alive" 1 "SleepInd" 2 "RESERVED" 3 "SleepAck" ;
VAL_ 1363 Destination_ASAU 0 "0x0x0~0xFF:NM Source Node ID" 255 "0x0x0~0xFF:NM Source Node ID" ;
VAL_ 1363 NMCommandCode_ASAU 1 "Alive" 2 "Ring" 3 "RESERVED" 4 "Limphome" 5 "0x5~0xFF:RESERVED" 255 "0x5~0xFF:RESERVED" ;
VAL_ 1363 NMSleepFlag_ASAU 0 "Alive" 1 "SleepInd" 2 "RESERVED" 3 "SleepAck" ;
